VERSION ""

NS_ :

BS_:

BU_: PowertrainControlModule AtmosphericSensor SafetyRestraintSystem2 Aftertreatment_2_GasOutlet Aftertreatment_2_GasIntake DieselParticulateFilterControl Turbocharger SafetyRestraintSystem1 CabDisplay2 Aftertreatment_1_GasOutlet Aftertreatment_1_GasIntake OnBoardDataLogger OffBoardDiagnosticTool2 OffBoardDiagnosticTool1 FileServer ParkingBrakeController SeatController2 FanDriveController SteeringColumnUnit CommunicationUnitRadio CommunicationUnitSatellite CommunicationUnitCellular PropulsionBatteryCharger ChassisController2 ChassisController1 EngineValveControl AuxiliaryHeater2 AuxiliaryHeater1 ClutchUnit RampControl InformationSystem1 SuspensionSystemController2 OilSensor VehicleDynamicStability ExhaustEmissionController TransmissionDisplay2 TransmissionDisplay1 ClimateControl2 WaterPumpController RearAxleSteeringController LightingOperatorControl SeatController1 IgnitionController2 IgnitionController1 TirePressureController CabController2 CabController1 PneumaticSystemController SuspensionSystemController1 HydraulicPumpController EnduranceBrakingSystem RetarderExhaustEngine2 OnBoardDiagnosticUnit HeadwayController RetarderExhaustEngine1 CabDisplay1 ManagementComputer VirtualTerminal OffVehicleGateway PowerTakeOffFront HitchControl AuxiliaryValveControl BodyController TractorTrailerBridge1 StarterSystem ElectricalSystem VehicleSecurity VehicleNavigation AerodynamicControl ElectricalChargingSystem ClimateControl1 TripRecorder InstrumentCluster SuspensionDriveAxle2 SuspensionDriveAxle1 SuspensionSteerAxle SteeringController FuelSystem CruiseControl RetarderDriveline RetarderEngine BrakesDriveAxle2 BrakesDriveAxle1 BrakesSystemController BrakesSteerAxle AxleDrive2 AxleDrive1 AxleSteering PowerTakeOff ShiftConsoleSecondary ShiftConsolePrimary Transmission2 Transmission1 Engine2 Engine1

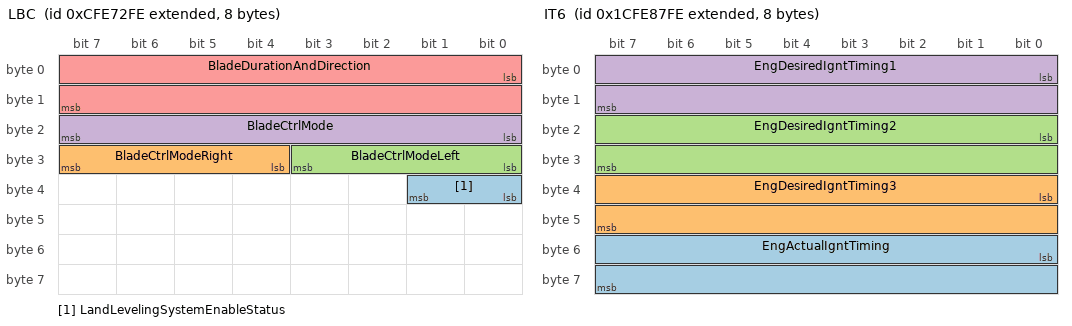
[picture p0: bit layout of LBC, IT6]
BO_ 2365485822 LBC: 8 Vector__XXX
 SG_ LandLevelingSystemEnableStatus : 32|2@1+ (1,0) [0|3] "" Vector__XXX
 SG_ BladeCtrlModeRight : 28|4@1+ (1,0) [0|15] "" Vector__XXX
 SG_ BladeCtrlModeLeft : 24|4@1+ (1,0) [0|15] "" Vector__XXX
 SG_ BladeCtrlMode : 16|8@1+ (1,0) [0|255] "" Vector__XXX
 SG_ BladeDurationAndDirection : 0|16@1+ (0.1,-3276.8) [-3276.8|3148.7] "s" Vector__XXX

BO_ 2633926654 IT6: 8 Vector__XXX
 SG_ EngActualIgntTiming : 48|16@1+ (0.0078125,-200) [-200|301.99] "deg" Vector__XXX
 SG_ EngDesiredIgntTiming3 : 32|16@1+ (0.0078125,-200) [-200|301.99] "deg" Vector__XXX
 SG_ EngDesiredIgntTiming2 : 16|16@1+ (0.0078125,-200) [-200|301.99] "deg" Vector__XXX
 SG_ EngDesiredIgntTiming1 : 0|16@1+ (0.0078125,-200) [-200|301.99] "deg" Vector__XXX

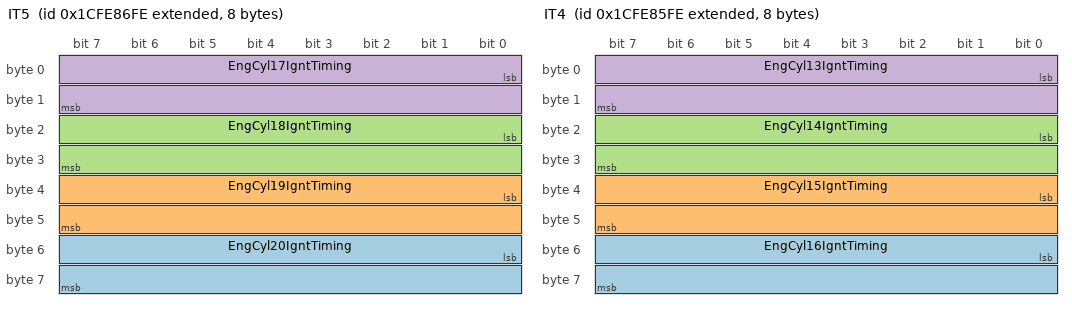
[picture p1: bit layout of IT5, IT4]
BO_ 2633926398 IT5: 8 Vector__XXX
 SG_ EngCyl20IgntTiming : 48|16@1+ (0.0078125,-200) [-200|301.99] "deg" Vector__XXX
 SG_ EngCyl19IgntTiming : 32|16@1+ (0.0078125,-200) [-200|301.99] "deg" Vector__XXX
 SG_ EngCyl18IgntTiming : 16|16@1+ (0.0078125,-200) [-200|301.99] "deg" Vector__XXX
 SG_ EngCyl17IgntTiming : 0|16@1+ (0.0078125,-200) [-200|301.99] "deg" Vector__XXX

BO_ 2633926142 IT4: 8 Vector__XXX
 SG_ EngCyl16IgntTiming : 48|16@1+ (0.0078125,-200) [-200|301.99] "deg" Vector__XXX
 SG_ EngCyl15IgntTiming : 32|16@1+ (0.0078125,-200) [-200|301.99] "deg" Vector__XXX
 SG_ EngCyl14IgntTiming : 16|16@1+ (0.0078125,-200) [-200|301.99] "deg" Vector__XXX
 SG_ EngCyl13IgntTiming : 0|16@1+ (0.0078125,-200) [-200|301.99] "deg" Vector__XXX

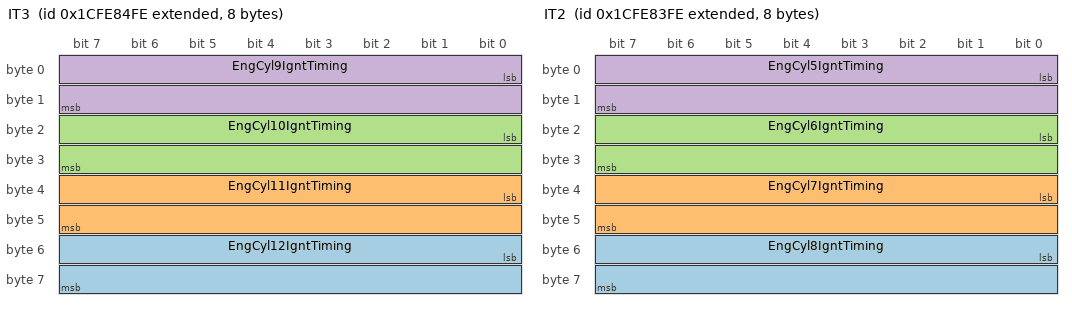
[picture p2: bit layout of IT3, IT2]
BO_ 2633925886 IT3: 8 Vector__XXX
 SG_ EngCyl12IgntTiming : 48|16@1+ (0.0078125,-200) [-200|301.99] "deg" Vector__XXX
 SG_ EngCyl11IgntTiming : 32|16@1+ (0.0078125,-200) [-200|301.99] "deg" Vector__XXX
 SG_ EngCyl10IgntTiming : 16|16@1+ (0.0078125,-200) [-200|301.99] "deg" Vector__XXX
 SG_ EngCyl9IgntTiming : 0|16@1+ (0.0078125,-200) [-200|301.99] "deg" Vector__XXX

BO_ 2633925630 IT2: 8 Vector__XXX
 SG_ EngCyl8IgntTiming : 48|16@1+ (0.0078125,-200) [-200|301.99] "deg" Vector__XXX
 SG_ EngCyl7IgntTiming : 32|16@1+ (0.0078125,-200) [-200|301.99] "deg" Vector__XXX
 SG_ EngCyl6IgntTiming : 16|16@1+ (0.0078125,-200) [-200|301.99] "deg" Vector__XXX
 SG_ EngCyl5IgntTiming : 0|16@1+ (0.0078125,-200) [-200|301.99] "deg" Vector__XXX

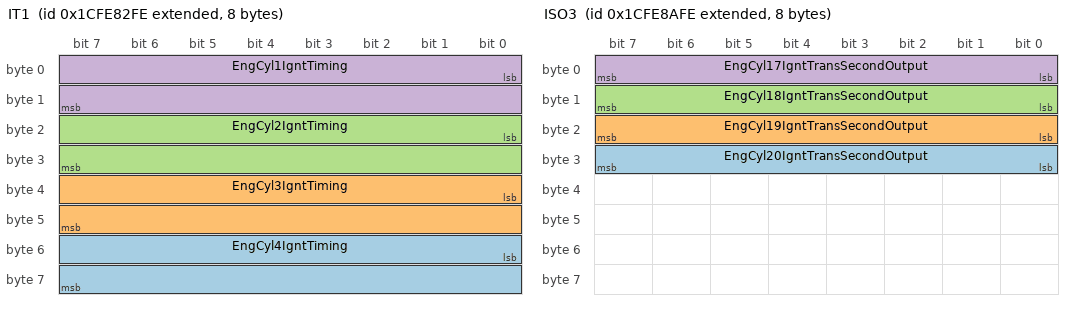
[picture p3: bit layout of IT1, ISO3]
BO_ 2633925374 IT1: 8 Vector__XXX
 SG_ EngCyl4IgntTiming : 48|16@1+ (0.0078125,-200) [-200|301.99] "deg" Vector__XXX
 SG_ EngCyl3IgntTiming : 32|16@1+ (0.0078125,-200) [-200|301.99] "deg" Vector__XXX
 SG_ EngCyl2IgntTiming : 16|16@1+ (0.0078125,-200) [-200|301.99] "deg" Vector__XXX
 SG_ EngCyl1IgntTiming : 0|16@1+ (0.0078125,-200) [-200|301.99] "deg" Vector__XXX

BO_ 2633927422 ISO3: 8 Vector__XXX
 SG_ EngCyl20IgntTransSecondOutput : 24|8@1+ (1,-125) [-125|125] "%" Vector__XXX
 SG_ EngCyl19IgntTransSecondOutput : 16|8@1+ (1,-125) [-125|125] "%" Vector__XXX
 SG_ EngCyl18IgntTransSecondOutput : 8|8@1+ (1,-125) [-125|125] "%" Vector__XXX
 SG_ EngCyl17IgntTransSecondOutput : 0|8@1+ (1,-125) [-125|125] "%" Vector__XXX

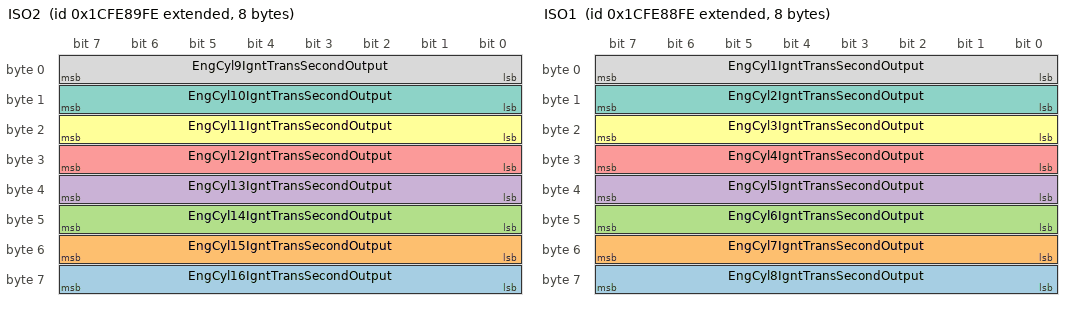
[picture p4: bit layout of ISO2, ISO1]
BO_ 2633927166 ISO2: 8 Vector__XXX
 SG_ EngCyl16IgntTransSecondOutput : 56|8@1+ (1,-125) [-125|125] "%" Vector__XXX
 SG_ EngCyl15IgntTransSecondOutput : 48|8@1+ (1,-125) [-125|125] "%" Vector__XXX
 SG_ EngCyl14IgntTransSecondOutput : 40|8@1+ (1,-125) [-125|125] "%" Vector__XXX
 SG_ EngCyl13IgntTransSecondOutput : 32|8@1+ (1,-125) [-125|125] "%" Vector__XXX
 SG_ EngCyl12IgntTransSecondOutput : 24|8@1+ (1,-125) [-125|125] "%" Vector__XXX
 SG_ EngCyl11IgntTransSecondOutput : 16|8@1+ (1,-125) [-125|125] "%" Vector__XXX
 SG_ EngCyl10IgntTransSecondOutput : 8|8@1+ (1,-125) [-125|125] "%" Vector__XXX
 SG_ EngCyl9IgntTransSecondOutput : 0|8@1+ (1,-125) [-125|125] "%" Vector__XXX

BO_ 2633926910 ISO1: 8 Vector__XXX
 SG_ EngCyl8IgntTransSecondOutput : 56|8@1+ (1,-125) [-125|125] "%" Vector__XXX
 SG_ EngCyl7IgntTransSecondOutput : 48|8@1+ (1,-125) [-125|125] "%" Vector__XXX
 SG_ EngCyl6IgntTransSecondOutput : 40|8@1+ (1,-125) [-125|125] "%" Vector__XXX
 SG_ EngCyl5IgntTransSecondOutput : 32|8@1+ (1,-125) [-125|125] "%" Vector__XXX
 SG_ EngCyl4IgntTransSecondOutput : 24|8@1+ (1,-125) [-125|125] "%" Vector__XXX
 SG_ EngCyl3IgntTransSecondOutput : 16|8@1+ (1,-125) [-125|125] "%" Vector__XXX
 SG_ EngCyl2IgntTransSecondOutput : 8|8@1+ (1,-125) [-125|125] "%" Vector__XXX
 SG_ EngCyl1IgntTransSecondOutput : 0|8@1+ (1,-125) [-125|125] "%" Vector__XXX

BO_ 2566768894 ISCS: 8 Vector__XXX
 SG_ EngOprtrPrmryIntrmdtSpdSlctState : 0|4@1+ (1,0) [0|15] "" Vector__XXX

BO_ 2566769406 ISC: 8 Vector__XXX
 SG_ EngOprtrPrmryIntrmdteSpeedSelect : 0|4@1+ (1,0) [0|15] "" Vector__XXX

BO_ 2566839550 IO: 8 Vector__XXX
 SG_ EngTotalIdleHours : 32|32@1+ (0.05,0) [0|210554060.75] "h" Vector__XXX
 SG_ EngTotalIdleFuelUsed : 0|32@1+ (0.5,0) [0|2105540607.5] "l" Vector__XXX

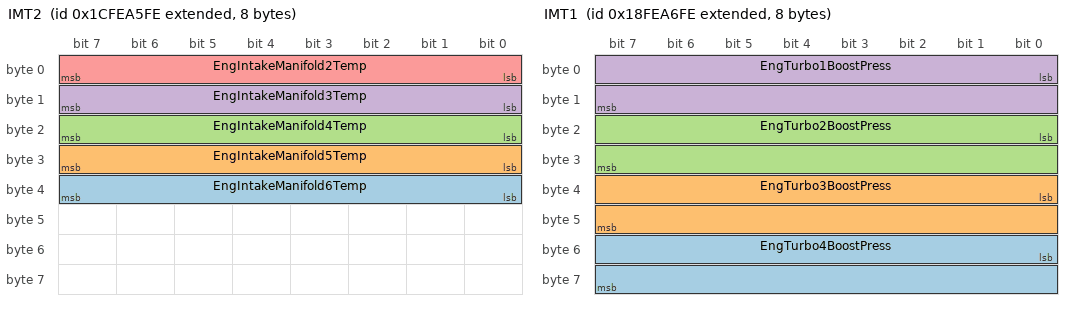
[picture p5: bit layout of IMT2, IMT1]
BO_ 2633934334 IMT2: 8 Vector__XXX
 SG_ EngIntakeManifold6Temp : 32|8@1+ (1,-40) [-40|210] "캜" Vector__XXX
 SG_ EngIntakeManifold5Temp : 24|8@1+ (1,-40) [-40|210] "캜" Vector__XXX
 SG_ EngIntakeManifold4Temp : 16|8@1+ (1,-40) [-40|210] "캜" Vector__XXX
 SG_ EngIntakeManifold3Temp : 8|8@1+ (1,-40) [-40|210] "캜" Vector__XXX
 SG_ EngIntakeManifold2Temp : 0|8@1+ (1,-40) [-40|210] "캜" Vector__XXX

BO_ 2566825726 IMT1: 8 Vector__XXX
 SG_ EngTurbo4BoostPress : 48|16@1+ (0.125,0) [0|8031.875] "kPa" Vector__XXX
 SG_ EngTurbo3BoostPress : 32|16@1+ (0.125,0) [0|8031.875] "kPa" Vector__XXX
 SG_ EngTurbo2BoostPress : 16|16@1+ (0.125,0) [0|8031.875] "kPa" Vector__XXX
 SG_ EngTurbo1BoostPress : 0|16@1+ (0.125,0) [0|8031.875] "kPa" Vector__XXX

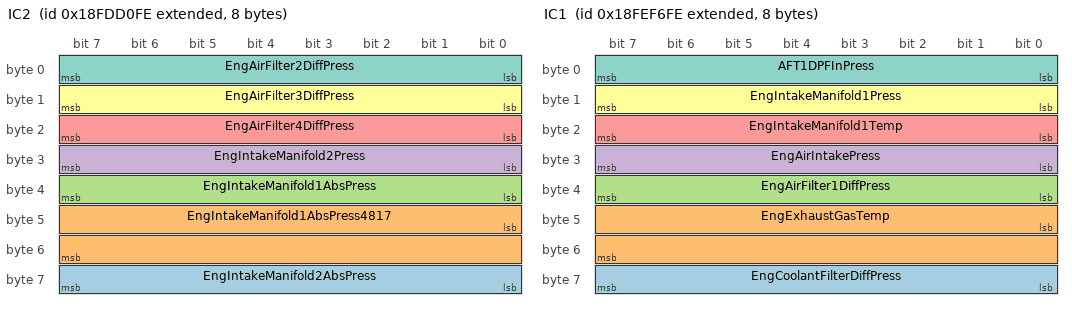
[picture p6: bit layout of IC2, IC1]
BO_ 2566770942 IC2: 8 Vector__XXX
 SG_ EngIntakeManifold2AbsPress : 56|8@1+ (2,0) [0|500] "kPa" Vector__XXX
 SG_ EngIntakeManifold1AbsPress4817 : 40|16@1+ (0.1,0) [0|6425.5] "kPa" Vector__XXX
 SG_ EngIntakeManifold1AbsPress : 32|8@1+ (2,0) [0|500] "kPa" Vector__XXX
 SG_ EngIntakeManifold2Press : 24|8@1+ (2,0) [0|500] "kPa" Vector__XXX
 SG_ EngAirFilter4DiffPress : 16|8@1+ (0.05,0) [0|12.5] "kPa" Vector__XXX
 SG_ EngAirFilter3DiffPress : 8|8@1+ (0.05,0) [0|12.5] "kPa" Vector__XXX
 SG_ EngAirFilter2DiffPress : 0|8@1+ (0.05,0) [0|12.5] "kPa" Vector__XXX

BO_ 2566846206 IC1: 8 Vector__XXX
 SG_ EngCoolantFilterDiffPress : 56|8@1+ (0.5,0) [0|125] "kPa" Vector__XXX
 SG_ EngExhaustGasTemp : 40|16@1+ (0.03125,-273) [-273|1734.96875] "캜" Vector__XXX
 SG_ EngAirFilter1DiffPress : 32|8@1+ (0.05,0) [0|12.5] "kPa" Vector__XXX
 SG_ EngAirIntakePress : 24|8@1+ (2,0) [0|500] "kPa" Vector__XXX
 SG_ EngIntakeManifold1Temp : 16|8@1+ (1,-40) [-40|210] "캜" Vector__XXX
 SG_ EngIntakeManifold1Press : 8|8@1+ (2,0) [0|500] "kPa" Vector__XXX
 SG_ AFT1DPFInPress : 0|8@1+ (0.5,0) [0|125] "kPa" Vector__XXX

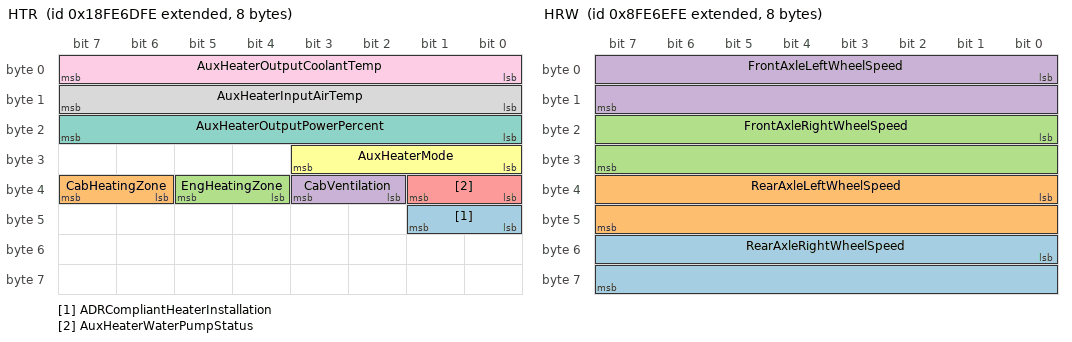
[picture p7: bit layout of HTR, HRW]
BO_ 2566811134 HTR: 8 Vector__XXX
 SG_ ADRCompliantHeaterInstallation : 40|2@1+ (1,0) [0|3] "" Vector__XXX
 SG_ CabHeatingZone : 38|2@1+ (1,0) [0|3] "" Vector__XXX
 SG_ EngHeatingZone : 36|2@1+ (1,0) [0|3] "" Vector__XXX
 SG_ CabVentilation : 34|2@1+ (1,0) [0|3] "" Vector__XXX
 SG_ AuxHeaterWaterPumpStatus : 32|2@1+ (1,0) [0|3] "" Vector__XXX
 SG_ AuxHeaterMode : 24|4@1+ (1,0) [0|15] "" Vector__XXX
 SG_ AuxHeaterOutputPowerPercent : 16|8@1+ (0.4,0) [0|100] "%" Vector__XXX
 SG_ AuxHeaterInputAirTemp : 8|8@1+ (1,-40) [-40|210] "캜" Vector__XXX
 SG_ AuxHeaterOutputCoolantTemp : 0|8@1+ (1,-40) [-40|210] "캜" Vector__XXX

BO_ 2298375934 HRW: 8 Vector__XXX
 SG_ RearAxleRightWheelSpeed : 48|16@1+ (0.00390625,0) [0|250.996] "km/h" Vector__XXX
 SG_ RearAxleLeftWheelSpeed : 32|16@1+ (0.00390625,0) [0|250.996] "km/h" Vector__XXX
 SG_ FrontAxleRightWheelSpeed : 16|16@1+ (0.00390625,0) [0|250.996] "km/h" Vector__XXX
 SG_ FrontAxleLeftWheelSpeed : 0|16@1+ (0.00390625,0) [0|250.996] "km/h" Vector__XXX

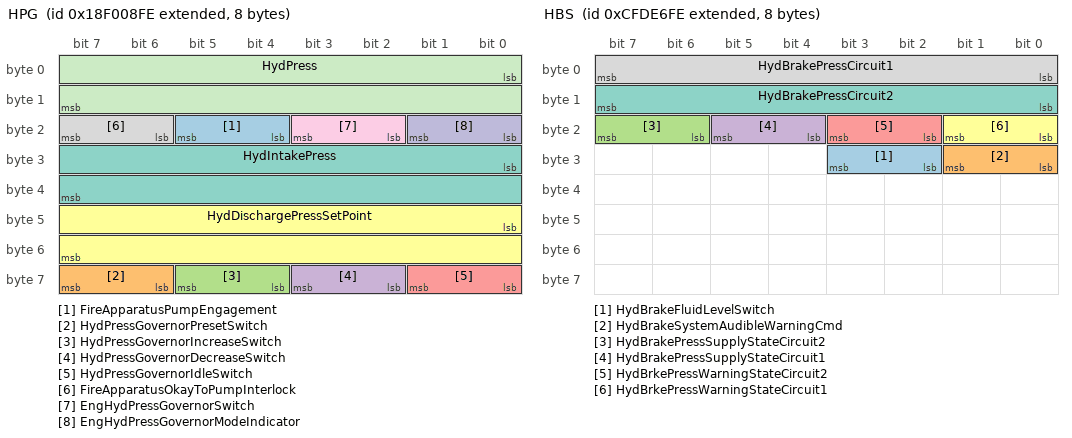
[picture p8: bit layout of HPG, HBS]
BO_ 2565867774 HPG: 8 Vector__XXX
 SG_ FireApparatusPumpEngagement : 20|2@1+ (1,0) [0|3] "" Vector__XXX
 SG_ HydPressGovernorPresetSwitch : 62|2@1+ (1,0) [0|3] "" Vector__XXX
 SG_ HydPressGovernorIncreaseSwitch : 60|2@1+ (1,0) [0|3] "" Vector__XXX
 SG_ HydPressGovernorDecreaseSwitch : 58|2@1+ (1,0) [0|3] "" Vector__XXX
 SG_ HydPressGovernorIdleSwitch : 56|2@1+ (1,0) [0|3] "" Vector__XXX
 SG_ HydDischargePressSetPoint : 40|16@1+ (2,0) [0|128510] "kPa" Vector__XXX
 SG_ HydIntakePress : 24|16@1+ (0.0001220703125,-1) [-1|6.84362793] "MPa" Vector__XXX
 SG_ FireApparatusOkayToPumpInterlock : 22|2@1+ (1,0) [0|3] "" Vector__XXX
 SG_ EngHydPressGovernorSwitch : 18|2@1+ (1,0) [0|3] "" Vector__XXX
 SG_ EngHydPressGovernorModeIndicator : 16|2@1+ (1,0) [0|3] "" Vector__XXX
 SG_ HydPress : 0|16@1+ (2,0) [0|128510] "kPa" Vector__XXX

BO_ 2566841854 HOURS: 8 Vector__XXX
 SG_ EngTotalRevolutions : 32|32@1+ (1000,0) [0|4211081215000] "r" Vector__XXX
 SG_ EngTotalHoursOfOperation : 0|32@1+ (0.05,0) [0|210554060.75] "h" Vector__XXX

BO_ 2365449982 HBS: 8 Vector__XXX
 SG_ HydBrakeFluidLevelSwitch : 26|2@1+ (1,0) [0|3] "" Vector__XXX
 SG_ HydBrakeSystemAudibleWarningCmd : 24|2@1+ (1,0) [0|3] "" Vector__XXX
 SG_ HydBrakePressSupplyStateCircuit2 : 22|2@1+ (1,0) [0|3] "" Vector__XXX
 SG_ HydBrakePressSupplyStateCircuit1 : 20|2@1+ (1,0) [0|3] "" Vector__XXX
 SG_ HydBrkePressWarningStateCircuit2 : 18|2@1+ (1,0) [0|3] "" Vector__XXX
 SG_ HydBrkePressWarningStateCircuit1 : 16|2@1+ (1,0) [0|3] "" Vector__XXX
 SG_ HydBrakePressCircuit2 : 8|8@1+ (100,0) [0|25000] "kPa" Vector__XXX
 SG_ HydBrakePressCircuit1 : 0|8@1+ (100,0) [0|25000] "kPa" Vector__XXX

BO_ 2633939198 GTFI: 22 Vector__XXX
 SG_ TripDriveFuelEconomy : 160|16@1+ (0.001953125,0) [0|125.498046875] "km/kg" Vector__XXX
 SG_ TripCruiseFuelUsed : 128|32@1+ (0.5,0) [0|2105540607.5] "kg" Vector__XXX
 SG_ TripVehicleIdleFuelUsed : 96|32@1+ (0.5,0) [0|2105540607.5] "kg" Vector__XXX
 SG_ TripPTOGovernorNonmovingFuelUsed : 64|32@1+ (0.5,0) [0|2105540607.5] "kg" Vector__XXX
 SG_ TripPTOGovernorMovingFuelUsed : 32|32@1+ (0.5,0) [0|2105540607.5] "kg" Vector__XXX
 SG_ TripDriveFuelUsed : 0|32@1+ (0.5,0) [0|2105540607.5] "kg" Vector__XXX

BO_ 2633927678 GFP1: 8 Vector__XXX
 SG_ EngFuelValve1OutletAbsPress : 48|16@1+ (0.1,0) [0|6425.5] "kPa" Vector__XXX
 SG_ EngAirToFuelDiffPress : 32|16@1+ (0.1,0) [0|6425.5] "kPa" Vector__XXX
 SG_ EngFuelValveDiffPress : 16|16@1+ (0.1,0) [0|6425.5] "kPa" Vector__XXX
 SG_ EngFuelValve1IntakeAbsPress : 0|16@1+ (0.1,0) [0|6425.5] "kPa" Vector__XXX

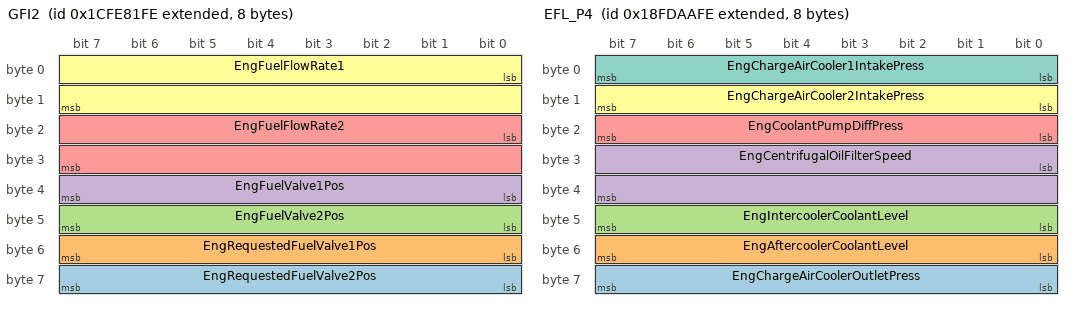
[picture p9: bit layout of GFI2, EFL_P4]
BO_ 2633925118 GFI2: 8 Vector__XXX
 SG_ EngRequestedFuelValve2Pos : 56|8@1+ (0.4,0) [0|100] "%" Vector__XXX
 SG_ EngRequestedFuelValve1Pos : 48|8@1+ (0.4,0) [0|100] "%" Vector__XXX
 SG_ EngFuelValve2Pos : 40|8@1+ (0.4,0) [0|100] "%" Vector__XXX
 SG_ EngFuelValve1Pos : 32|8@1+ (0.4,0) [0|100] "%" Vector__XXX
 SG_ EngFuelFlowRate2 : 16|16@1+ (0.1,0) [0|6425.5] "m�/h" Vector__XXX
 SG_ EngFuelFlowRate1 : 0|16@1+ (0.1,0) [0|6425.5] "m�/h" Vector__XXX

BO_ 2633937662 GFI1: 8 Vector__XXX
 SG_ EngFuelSpecificGravity : 48|16@1+ (0.0001,0) [0|2] "" Vector__XXX
 SG_ TripAverageFuelRate : 32|16@1+ (0.05,0) [0|3212.75] "kg/h" Vector__XXX
 SG_ TotalEngPTOGovernorFuelUsed : 0|32@1+ (0.5,0) [0|2105540607.5] "kg" Vector__XXX

BO_ 2566804990 GFD: 8 Vector__XXX
 SG_ FuelEnergyContent : 32|16@1+ (0.00390625,0) [0|250.996] "MJ/Nm�" Vector__XXX
 SG_ ReferenceEngGasMassFlowRate : 16|16@1+ (0.05,0) [0|3212.75] "kg/h" Vector__XXX
 SG_ SpecificHeatRatio : 0|16@1+ (0.001,0) [0|2] "" Vector__XXX

BO_ 2633936894 GFC: 8 Vector__XXX
 SG_ TotalFuelUsed : 32|32@1+ (0.5,0) [0|2105540607.5] "kg" Vector__XXX
 SG_ TripFuel : 0|32@1+ (0.5,0) [0|2105540607.5] "kg" Vector__XXX

BO_ 2566757630 SEP2: 8 Vector__XXX
 SG_ SensorSupplyVoltage8 : 48|16@1+ (0.05,0) [0|3212.75] "V" Vector__XXX
 SG_ SensorSupplyVoltage7 : 32|16@1+ (0.05,0) [0|3212.75] "V" Vector__XXX
 SG_ SensorSupplyVoltage6 : 16|16@1+ (0.05,0) [0|3212.75] "V" Vector__XXX
 SG_ SensorSupplyVoltage5 : 0|16@1+ (0.05,0) [0|3212.75] "V" Vector__XXX

BO_ 2566757886 SEP1: 8 Vector__XXX
 SG_ SensorSupplyVoltage4 : 48|16@1+ (0.05,0) [0|3212.75] "V" Vector__XXX
 SG_ SensorSupplyVoltage3 : 32|16@1+ (0.05,0) [0|3212.75] "V" Vector__XXX
 SG_ SensorSupplyVoltage2 : 16|16@1+ (0.05,0) [0|3212.75] "V" Vector__XXX
 SG_ SensorSupplyVoltage1 : 0|16@1+ (0.05,0) [0|3212.75] "V" Vector__XXX

BO_ 2566759678 PTODE: 8 Vector__XXX
 SG_ AtLeastOnePTOEngaged : 48|2@1+ (1,0) [0|3] "" Vector__XXX
 SG_ EnggmntSttsPTOEngAccessoryDrive2 : 44|2@1+ (1,0) [0|3] "" Vector__XXX
 SG_ EnggmntSttsPTOEngAccessoryDrive1 : 42|2@1+ (1,0) [0|3] "" Vector__XXX
 SG_ EngagementStatusPTOEngFlywheel : 40|2@1+ (1,0) [0|3] "" Vector__XXX
 SG_ EnggmntStatusTransInputShaftPTO1 : 38|2@1+ (1,0) [0|3] "" Vector__XXX
 SG_ EnggmntStatusTransInputShaftPTO2 : 36|2@1+ (1,0) [0|3] "" Vector__XXX
 SG_ EnggmntStatusTransOutputShaftPTO : 34|2@1+ (1,0) [0|3] "" Vector__XXX
 SG_ EnggmntSttsTrnsfrCsOtputShaftPTO : 32|2@1+ (1,0) [0|3] "" Vector__XXX
 SG_ EnggmntCnsntPTOEngAccssoryDrive2 : 28|2@1+ (1,0) [0|3] "" Vector__XXX
 SG_ EnggmntCnsntPTOEngAccssoryDrive1 : 26|2@1+ (1,0) [0|3] "" Vector__XXX
 SG_ EngagementConsentPTOEngFlywheel : 24|2@1+ (1,0) [0|3] "" Vector__XXX
 SG_ EnggmntCnsentTransInputShaftPTO1 : 22|2@1+ (1,0) [0|3] "" Vector__XXX
 SG_ EnggmntCnsentTransInputShaftPTO2 : 20|2@1+ (1,0) [0|3] "" Vector__XXX
 SG_ EnggmntCnsentTransOutputShaftPTO : 18|2@1+ (1,0) [0|3] "" Vector__XXX
 SG_ EnggmntCnsntTrnsfrCsOtptShaftPTO : 16|2@1+ (1,0) [0|3] "" Vector__XXX
 SG_ EnbleSwitchPTOEngAccessoryDrive2 : 12|2@1+ (1,0) [0|3] "" Vector__XXX
 SG_ EnbleSwitchPTOEngAccessoryDrive1 : 10|2@1+ (1,0) [0|3] "" Vector__XXX
 SG_ EnableSwitchPTOEngFlywheel : 8|2@1+ (1,0) [0|3] "" Vector__XXX
 SG_ EnableSwitchTransInputShaftPTO1 : 6|2@1+ (1,0) [0|3] "" Vector__XXX
 SG_ EnableSwitchTransInputShaftPTO2 : 4|2@1+ (1,0) [0|3] "" Vector__XXX
 SG_ EnableSwitchTransOutputShaftPTO : 2|2@1+ (1,0) [0|3] "" Vector__XXX
 SG_ EnblSwtchTrnsfrCseOutputShaftPTO : 0|2@1+ (1,0) [0|3] "" Vector__XXX

BO_ 2432541438 GFI3: 8 Vector__XXX
 SG_ EngFuelValve2OutletAbsPress : 48|16@1+ (0.1,0) [0|6425.5] "kPa" Vector__XXX
 SG_ EngFuelTemp2 : 32|8@1+ (1,-40) [-40|210] "캜" Vector__XXX
 SG_ EngGas2MassFlowRate : 16|16@1+ (0.05,0) [0|3212.75] "kg/h" Vector__XXX
 SG_ EngFuelValve2IntakeAbsPress : 0|16@1+ (0.1,0) [0|6425.5] "kPa" Vector__XXX

BO_ 2566761214 EFL_P4: 8 Vector__XXX
 SG_ EngChargeAirCoolerOutletPress : 56|8@1+ (2,0) [0|500] "kPa" Vector__XXX
 SG_ EngAftercoolerCoolantLevel : 48|8@1+ (0.4,0) [0|100] "%" Vector__XXX
 SG_ EngIntercoolerCoolantLevel : 40|8@1+ (0.4,0) [0|100] "%" Vector__XXX
 SG_ EngCentrifugalOilFilterSpeed : 24|16@1+ (4,0) [0|257020] "rpm" Vector__XXX
 SG_ EngCoolantPumpDiffPress : 16|8@1+ (1.64,-7) [-7|403] "kPa" Vector__XXX
 SG_ EngChargeAirCooler2IntakePress : 8|8@1+ (2,0) [0|500] "kPa" Vector__XXX
 SG_ EngChargeAirCooler1IntakePress : 0|8@1+ (2,0) [0|500] "kPa" Vector__XXX

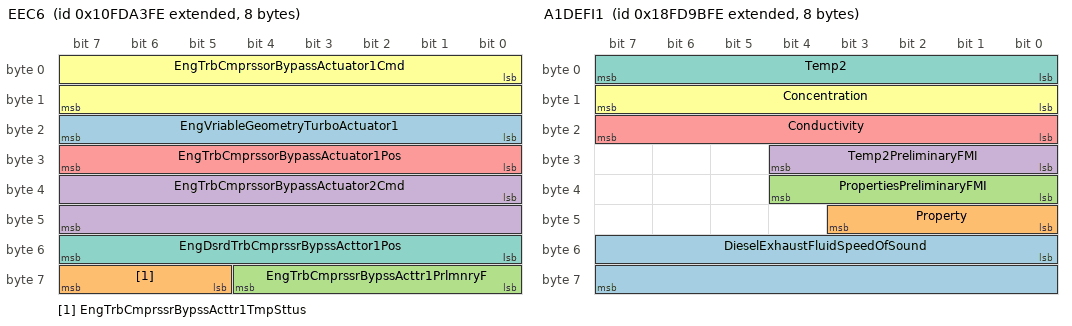
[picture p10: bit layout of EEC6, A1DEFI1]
BO_ 2432541694 EEC6: 8 Vector__XXX
 SG_ EngVriableGeometryTurboActuator1 : 16|8@1+ (0.4,0) [0|100] "%" Vector__XXX
 SG_ EngTrbCmprssrBypssActtr1TmpSttus : 61|3@1+ (1,0) [0|7] "" Vector__XXX
 SG_ EngTrbCmprssrBypssActtr1PrlmnryF : 56|5@1+ (1,0) [0|31] "" Vector__XXX
 SG_ EngTrbCmprssorBypassActuator2Cmd : 32|16@1+ (0.0025,0) [0|160.6375] "%" Vector__XXX
 SG_ EngTrbCmprssorBypassActuator1Pos : 24|8@1+ (0.4,0) [0|100] "%" Vector__XXX
 SG_ EngTrbCmprssorBypassActuator1Cmd : 0|16@1+ (0.0025,0) [0|100] "%" Vector__XXX
 SG_ EngDsrdTrbCmprssrBypssActtor1Pos : 48|8@1+ (0.4,0) [0|100] "%" Vector__XXX

BO_ 2566759934 DC2: 8 Vector__XXX
 SG_ EnableStatusOfDoor10 : 58|2@1+ (1,0) [0|3] "" Vector__XXX
 SG_ OpenStatusOfDoor10 : 56|2@1+ (1,0) [0|3] "" Vector__XXX
 SG_ LockStatusOfDoor10 : 54|2@1+ (1,0) [0|3] "" Vector__XXX
 SG_ EnableStatusOfDoor9 : 52|2@1+ (1,0) [0|3] "" Vector__XXX
 SG_ OpenStatusOfDoor9 : 50|2@1+ (1,0) [0|3] "" Vector__XXX
 SG_ LockStatusOfDoor9 : 48|2@1+ (1,0) [0|3] "" Vector__XXX
 SG_ EnableStatusOfDoor8 : 46|2@1+ (1,0) [0|3] "" Vector__XXX
 SG_ OpenStatusOfDoor8 : 44|2@1+ (1,0) [0|3] "" Vector__XXX
 SG_ LockStatusOfDoor8 : 42|2@1+ (1,0) [0|3] "" Vector__XXX
 SG_ EnableStatusOfDoor7 : 40|2@1+ (1,0) [0|3] "" Vector__XXX
 SG_ OpenStatusOfDoor7 : 38|2@1+ (1,0) [0|3] "" Vector__XXX
 SG_ LockStatusOfDoor7 : 36|2@1+ (1,0) [0|3] "" Vector__XXX
 SG_ EnableStatusOfDoor6 : 34|2@1+ (1,0) [0|3] "" Vector__XXX
 SG_ OpenStatusOfDoor6 : 32|2@1+ (1,0) [0|3] "" Vector__XXX
 SG_ LockStatusOfDoor6 : 30|2@1+ (1,0) [0|3] "" Vector__XXX
 SG_ EnableStatusOfDoor5 : 28|2@1+ (1,0) [0|3] "" Vector__XXX
 SG_ OpenStatusOfDoor5 : 26|2@1+ (1,0) [0|3] "" Vector__XXX
 SG_ LockStatusOfDoor5 : 24|2@1+ (1,0) [0|3] "" Vector__XXX
 SG_ EnableStatusOfDoor4 : 22|2@1+ (1,0) [0|3] "" Vector__XXX
 SG_ OpenStatusOfDoor4 : 20|2@1+ (1,0) [0|3] "" Vector__XXX
 SG_ LockStatusOfDoor4 : 18|2@1+ (1,0) [0|3] "" Vector__XXX
 SG_ EnableStatusOfDoor3 : 16|2@1+ (1,0) [0|3] "" Vector__XXX
 SG_ OpenStatusOfDoor3 : 14|2@1+ (1,0) [0|3] "" Vector__XXX
 SG_ LockStatusOfDoor3 : 12|2@1+ (1,0) [0|3] "" Vector__XXX
 SG_ EnableStatusOfDoor2 : 10|2@1+ (1,0) [0|3] "" Vector__XXX
 SG_ OpenStatusOfDoor2 : 8|2@1+ (1,0) [0|3] "" Vector__XXX
 SG_ LockStatusOfDoor2 : 6|2@1+ (1,0) [0|3] "" Vector__XXX
 SG_ EnableStatusOfDoor1 : 4|2@1+ (1,0) [0|3] "" Vector__XXX
 SG_ OpenStatusOfDoor1 : 2|2@1+ (1,0) [0|3] "" Vector__XXX
 SG_ LockStatusOfDoor1 : 0|2@1+ (1,0) [0|3] "" Vector__XXX

BO_ 2566757374 A1DEFI1: 8 Vector__XXX
 SG_ DieselExhaustFluidSpeedOfSound : 48|16@1+ (0.1,0) [0|6425.5] "m/s" Vector__XXX
 SG_ Property : 40|4@1+ (1,0) [0|15] "" Vector__XXX
 SG_ PropertiesPreliminaryFMI : 32|5@1+ (1,0) [0|31] "" Vector__XXX
 SG_ Temp2PreliminaryFMI : 24|5@1+ (1,0) [0|31] "" Vector__XXX
 SG_ Conductivity : 16|8@1+ (5,0) [0|1250] "킪iemens/mm" Vector__XXX
 SG_ Concentration : 8|8@1+ (0.25,0) [0|62.5] "%" Vector__XXX
 SG_ Temp2 : 0|8@1+ (1,-40) [-40|210] "캜" Vector__XXX

BO_ 2364546302 RGAAC: 8 Vector__XXX
 SG_ RqdGnrtrAvrgLneLineACRMSVoltage : 0|32@1+ (0.0078125,0) [0|32899071] "V" Vector__XXX

BO_ 2431654654 TFAC: 8 Vector__XXX
 SG_ EngFuelActuator2CtrlCmd : 48|16@1+ (0.0025,0) [0|100] "%" Vector__XXX
 SG_ EngFuelActuator1CtrlCmd : 32|16@1+ (0.0025,0) [0|100] "%" Vector__XXX
 SG_ EngThrottleActuator2CtrlCmd : 16|16@1+ (0.0025,0) [0|100] "%" Vector__XXX
 SG_ EngThrottleActuator1CtrlCmd : 0|16@1+ (0.0025,0) [0|100] "%" Vector__XXX

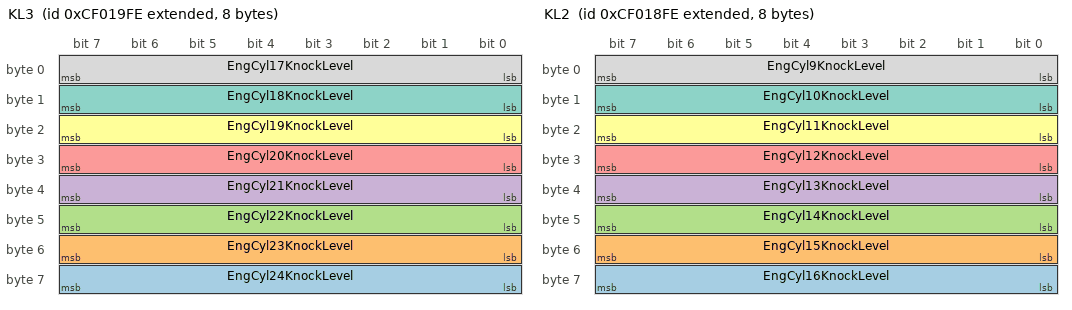
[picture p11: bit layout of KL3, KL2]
BO_ 2364545534 KL3: 8 Vector__XXX
 SG_ EngCyl24KnockLevel : 56|8@1+ (1,0) [0|250] "%" Vector__XXX
 SG_ EngCyl23KnockLevel : 48|8@1+ (1,0) [0|250] "%" Vector__XXX
 SG_ EngCyl22KnockLevel : 40|8@1+ (1,0) [0|250] "%" Vector__XXX
 SG_ EngCyl21KnockLevel : 32|8@1+ (1,0) [0|250] "%" Vector__XXX
 SG_ EngCyl20KnockLevel : 24|8@1+ (1,0) [0|250] "%" Vector__XXX
 SG_ EngCyl19KnockLevel : 16|8@1+ (1,0) [0|250] "%" Vector__XXX
 SG_ EngCyl18KnockLevel : 8|8@1+ (1,0) [0|250] "%" Vector__XXX
 SG_ EngCyl17KnockLevel : 0|8@1+ (1,0) [0|250] "%" Vector__XXX

BO_ 2364545278 KL2: 8 Vector__XXX
 SG_ EngCyl16KnockLevel : 56|8@1+ (1,0) [0|250] "%" Vector__XXX
 SG_ EngCyl15KnockLevel : 48|8@1+ (1,0) [0|250] "%" Vector__XXX
 SG_ EngCyl14KnockLevel : 40|8@1+ (1,0) [0|250] "%" Vector__XXX
 SG_ EngCyl13KnockLevel : 32|8@1+ (1,0) [0|250] "%" Vector__XXX
 SG_ EngCyl12KnockLevel : 24|8@1+ (1,0) [0|250] "%" Vector__XXX
 SG_ EngCyl11KnockLevel : 16|8@1+ (1,0) [0|250] "%" Vector__XXX
 SG_ EngCyl10KnockLevel : 8|8@1+ (1,0) [0|250] "%" Vector__XXX
 SG_ EngCyl9KnockLevel : 0|8@1+ (1,0) [0|250] "%" Vector__XXX

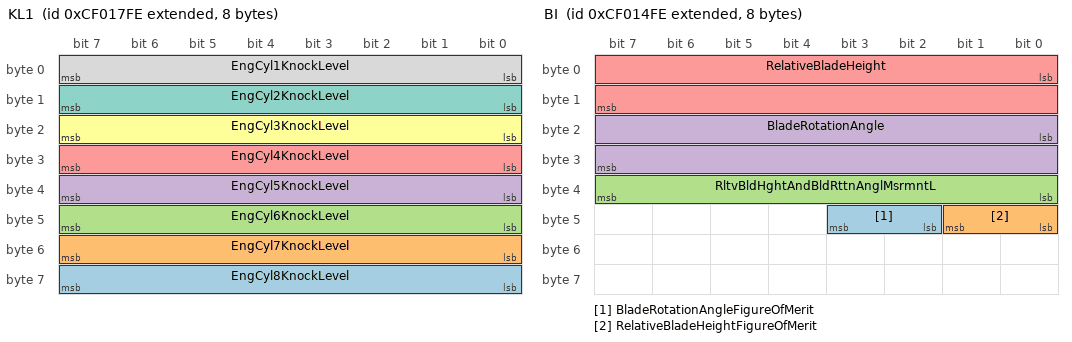
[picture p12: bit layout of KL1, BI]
BO_ 2364545022 KL1: 8 Vector__XXX
 SG_ EngCyl8KnockLevel : 56|8@1+ (1,0) [0|250] "%" Vector__XXX
 SG_ EngCyl7KnockLevel : 48|8@1+ (1,0) [0|250] "%" Vector__XXX
 SG_ EngCyl6KnockLevel : 40|8@1+ (1,0) [0|250] "%" Vector__XXX
 SG_ EngCyl5KnockLevel : 32|8@1+ (1,0) [0|250] "%" Vector__XXX
 SG_ EngCyl4KnockLevel : 24|8@1+ (1,0) [0|250] "%" Vector__XXX
 SG_ EngCyl3KnockLevel : 16|8@1+ (1,0) [0|250] "%" Vector__XXX
 SG_ EngCyl2KnockLevel : 8|8@1+ (1,0) [0|250] "%" Vector__XXX
 SG_ EngCyl1KnockLevel : 0|8@1+ (1,0) [0|100] "%" Vector__XXX

BO_ 2364544766 CCS: 8 Vector__XXX
 SG_ EngCyl24CombustionStatus : 46|2@1+ (1,0) [0|3] "" Vector__XXX
 SG_ EngCyl23CombustionStatus : 44|2@1+ (1,0) [0|3] "" Vector__XXX
 SG_ EngCyl22CombustionStatus : 42|2@1+ (1,0) [0|3] "" Vector__XXX
 SG_ EngCyl21CombustionStatus : 40|2@1+ (1,0) [0|3] "" Vector__XXX
 SG_ EngCyl20CombustionStatus : 38|2@1+ (1,0) [0|3] "" Vector__XXX
 SG_ EngCyl19CombustionStatus : 36|2@1+ (1,0) [0|3] "" Vector__XXX
 SG_ EngCyl18CombustionStatus : 34|2@1+ (1,0) [0|3] "" Vector__XXX
 SG_ EngCyl17CombustionStatus : 32|2@1+ (1,0) [0|3] "" Vector__XXX
 SG_ EngCyl16CombustionStatus : 30|2@1+ (1,0) [0|3] "" Vector__XXX
 SG_ EngCyl15CombustionStatus : 28|2@1+ (1,0) [0|3] "" Vector__XXX
 SG_ EngCyl14CombustionStatus : 26|2@1+ (1,0) [0|3] "" Vector__XXX
 SG_ EngCyl13CombustionStatus : 24|2@1+ (1,0) [0|3] "" Vector__XXX
 SG_ EngCyl12CombustionStatus : 22|2@1+ (1,0) [0|3] "" Vector__XXX
 SG_ EngCyl11CombustionStatus : 20|2@1+ (1,0) [0|3] "" Vector__XXX
 SG_ EngCyl10CombustionStatus : 18|2@1+ (1,0) [0|3] "" Vector__XXX
 SG_ EngCyl9CombustionStatus : 16|2@1+ (1,0) [0|3] "" Vector__XXX
 SG_ EngCyl8CombustionStatus : 14|2@1+ (1,0) [0|3] "" Vector__XXX
 SG_ EngCyl7CombustionStatus : 12|2@1+ (1,0) [0|3] "" Vector__XXX
 SG_ EngCyl6CombustionStatus : 10|2@1+ (1,0) [0|3] "" Vector__XXX
 SG_ EngCyl5CombustionStatus : 8|2@1+ (1,0) [0|3] "" Vector__XXX
 SG_ EngCyl4CombustionStatus : 6|2@1+ (1,0) [0|3] "" Vector__XXX
 SG_ EngCyl3CombustionStatus : 4|2@1+ (1,0) [0|3] "" Vector__XXX
 SG_ EngCyl2CombustionStatus : 2|2@1+ (1,0) [0|3] "" Vector__XXX
 SG_ EngCyl1CombustionStatus : 0|2@1+ (1,0) [0|3] "" Vector__XXX

BO_ 2364544510 RGTACRP: 8 Vector__XXX
 SG_ RqGenOverallPowerFactorLagging : 48|2@1+ (1,0) [0|3] "" Vector__XXX
 SG_ RqGeneratorOverallPowerFactor : 32|16@1+ (6.103515625E-005,-1) [-1|1] "" Vector__XXX
 SG_ RqGeneratorTotalACReactivePower : 0|32@1+ (1,-2000000000) [-2000000000|2211081215] "VA" Vector__XXX

BO_ 2364544254 BI: 8 Vector__XXX
 SG_ BladeRotationAngleFigureOfMerit : 42|2@1+ (1,0) [0|3] "" Vector__XXX
 SG_ RelativeBladeHeightFigureOfMerit : 40|2@1+ (1,0) [0|3] "" Vector__XXX
 SG_ RltvBldHghtAndBldRttnAnglMsrmntL : 32|8@1+ (0.5,0) [0|125] "ms" Vector__XXX
 SG_ BladeRotationAngle : 16|16@1+ (0.0078125,-200) [-200|301.99] "deg" Vector__XXX
 SG_ RelativeBladeHeight : 0|16@1+ (0.1,-3200) [-3200|3225.5] "mm" Vector__XXX

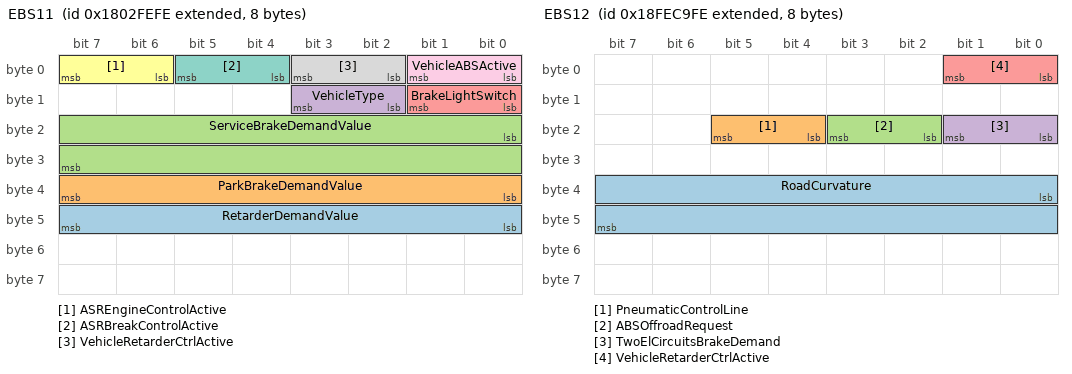
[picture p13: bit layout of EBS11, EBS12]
BO_ 2550333182 EBS11: 8 Vector__XXX
 SG_ RetarderDemandValue : 40|8@1+ (1,-125) [-125|125] "%" Vector__XXX
 SG_ ParkBrakeDemandValue : 32|8@1+ (0.4,0) [0|100] "%" Vector__XXX
 SG_ ServiceBrakeDemandValue : 16|16@1+ (0.01953125,0) [0|1255] "kPa" Vector__XXX
 SG_ VehicleType : 10|2@1+ (1,0) [0|3] "" Vector__XXX
 SG_ BrakeLightSwitch : 8|2@1+ (1,0) [0|3] "" Vector__XXX
 SG_ ASREngineControlActive : 6|2@1+ (1,0) [0|3] "" Vector__XXX
 SG_ ASRBreakControlActive : 4|2@1+ (1,0) [0|3] "" Vector__XXX
 SG_ VehicleRetarderCtrlActive : 2|2@1+ (1,0) [0|3] "" Vector__XXX
 SG_ VehicleABSActive : 0|2@1+ (1,0) [0|1] "" Vector__XXX

BO_ 2566834686 EBS12: 8 Vector__XXX
 SG_ RoadCurvature : 32|16@1+ (0.0078125,-250) [-250|251.992] "1/km" Vector__XXX
 SG_ PneumaticControlLine : 20|2@1+ (1,0) [0|1] "" Vector__XXX
 SG_ ABSOffroadRequest : 18|2@1+ (1,0) [0|1] "" Vector__XXX
 SG_ TwoElCircuitsBrakeDemand : 16|2@1+ (1,0) [0|1] "" Vector__XXX
 SG_ VehicleRetarderCtrlActive : 0|2@1+ (1,0) [0|3] "" Vector__XXX

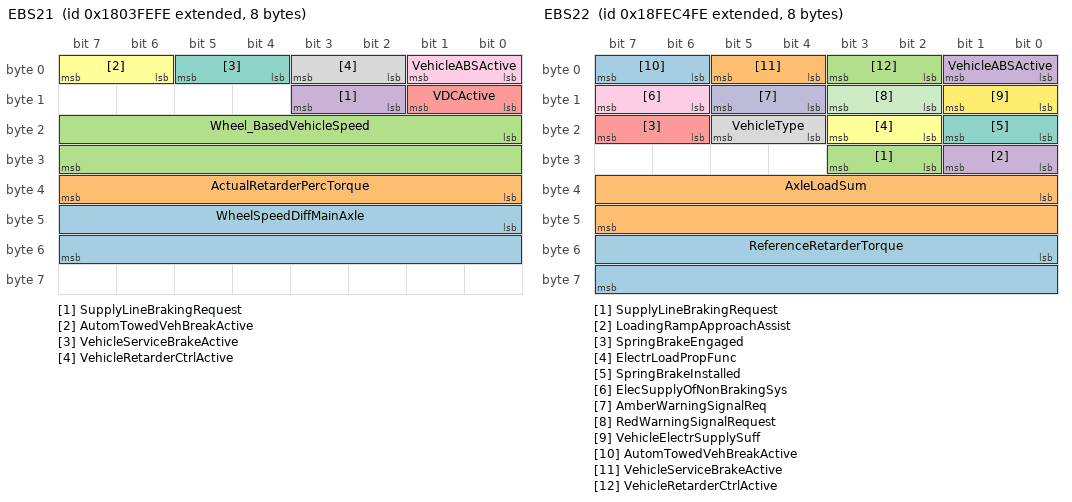
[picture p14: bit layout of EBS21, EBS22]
BO_ 2550398718 EBS21: 8 Vector__XXX
 SG_ WheelSpeedDiffMainAxle : 40|16@1+ (0.00390625,-125) [-125|125] "km/hr" Vector__XXX
 SG_ ActualRetarderPercTorque : 32|8@1+ (1,-125) [-125|125] "%" Vector__XXX
 SG_ Wheel_BasedVehicleSpeed : 16|16@1+ (0.00390625,0) [0|251] "km/hr" Vector__XXX
 SG_ SupplyLineBrakingRequest : 10|2@1+ (1,0) [0|1] "" Vector__XXX
 SG_ VDCActive : 8|2@1+ (1,0) [0|1] "" Vector__XXX
 SG_ AutomTowedVehBreakActive : 6|2@1+ (1,0) [0|1] "" Vector__XXX
 SG_ VehicleServiceBrakeActive : 4|2@1+ (1,0) [0|1] "" Vector__XXX
 SG_ VehicleRetarderCtrlActive : 2|2@1+ (1,0) [0|3] "" Vector__XXX
 SG_ VehicleABSActive : 0|2@1+ (1,0) [0|1] "" Vector__XXX

BO_ 2566833406 EBS22: 8 Vector__XXX
 SG_ ReferenceRetarderTorque : 48|16@1+ (1,0) [0|64255] "Nm" Vector__XXX
 SG_ AxleLoadSum : 32|16@1+ (2,0) [0|128510] "kg" Vector__XXX
 SG_ SupplyLineBrakingRequest : 26|2@1+ (1,0) [0|1] "" Vector__XXX
 SG_ LoadingRampApproachAssist : 24|2@1+ (1,0) [0|1] "" Vector__XXX
 SG_ SpringBrakeEngaged : 22|2@1+ (1,0) [0|1] "" Vector__XXX
 SG_ ElectrLoadPropFunc : 18|2@1+ (1,0) [0|1] "" Vector__XXX
 SG_ SpringBrakeInstalled : 16|2@1+ (1,0) [0|1] "" Vector__XXX
 SG_ VehicleType : 20|2@1+ (1,0) [0|3] "" Vector__XXX
 SG_ ElecSupplyOfNonBrakingSys : 14|2@1+ (1,0) [0|1] "" Vector__XXX
 SG_ AmberWarningSignalReq : 12|2@1+ (1,0) [0|1] "" Vector__XXX
 SG_ RedWarningSignalRequest : 10|2@1+ (1,0) [0|1] "" Vector__XXX
 SG_ VehicleElectrSupplySuff : 8|2@1+ (1,0) [0|1] "" Vector__XXX
 SG_ AutomTowedVehBreakActive : 6|2@1+ (1,0) [0|1] "" Vector__XXX
 SG_ VehicleServiceBrakeActive : 4|2@1+ (1,0) [0|1] "" Vector__XXX
 SG_ VehicleRetarderCtrlActive : 2|2@1+ (1,0) [0|3] "" Vector__XXX
 SG_ VehicleABSActive : 0|2@1+ (1,0) [0|1] "" Vector__XXX

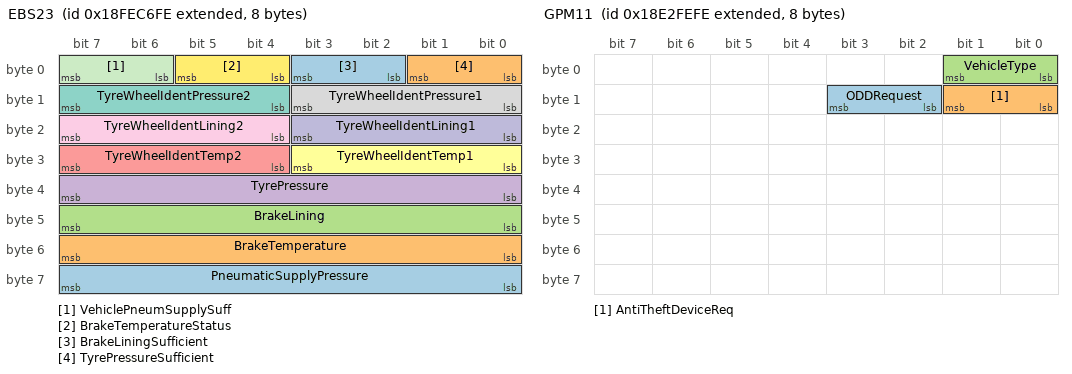
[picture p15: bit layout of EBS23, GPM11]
BO_ 2566833918 EBS23: 8 Vector__XXX
 SG_ PneumaticSupplyPressure : 56|8@1+ (5,0) [0|1250] "kPa" Vector__XXX
 SG_ BrakeTemperature : 48|8@1+ (10,0) [0|2500] "캜" Vector__XXX
 SG_ BrakeLining : 40|8@1+ (0.4,0) [0|100] "%" Vector__XXX
 SG_ TyrePressure : 32|8@1+ (10,0) [0|2500] "kPa" Vector__XXX
 SG_ TyreWheelIdentTemp2 : 28|4@1+ (1,0) [0|15] "" Vector__XXX
 SG_ TyreWheelIdentTemp1 : 24|4@1+ (1,0) [0|15] "" Vector__XXX
 SG_ TyreWheelIdentPressure2 : 12|4@1+ (1,0) [0|15] "" Vector__XXX
 SG_ TyreWheelIdentPressure1 : 8|4@1+ (1,0) [0|15] "" Vector__XXX
 SG_ TyreWheelIdentLining2 : 20|4@1+ (1,0) [0|15] "" Vector__XXX
 SG_ TyreWheelIdentLining1 : 16|4@1+ (1,0) [0|15] "" Vector__XXX
 SG_ VehiclePneumSupplySuff : 6|2@1+ (1,0) [0|1] "" Vector__XXX
 SG_ BrakeTemperatureStatus : 4|2@1+ (1,0) [0|1] "" Vector__XXX
 SG_ BrakeLiningSufficient : 2|2@1+ (1,0) [0|1] "" Vector__XXX
 SG_ TyrePressureSufficient : 0|2@1+ (1,0) [0|1] "" Vector__XXX

BO_ 2565013246 GPM11: 8 Vector__XXX
 SG_ ODDRequest : 10|2@1+ (1,0) [0|3] "" Vector__XXX
 SG_ AntiTheftDeviceReq : 8|2@1+ (1,0) [0|3] "" Vector__XXX
 SG_ VehicleType : 0|2@1+ (1,0) [0|3] "" Vector__XXX

BO_ 2566807038 GPM12: 8 Vector__XXX
 SG_ MaxVehicleSpeedLimit : 32|8@1+ (1,0) [0|250] "km/h" Vector__XXX
 SG_ EngineSpeedUpperLimit : 0|16@1+ (0.125,0) [0|8031.875] "rpm" Vector__XXX
 SG_ EngineSpeedLowerLimit : 16|16@1+ (0.125,0) [0|8191.875] "rpm" Vector__XXX

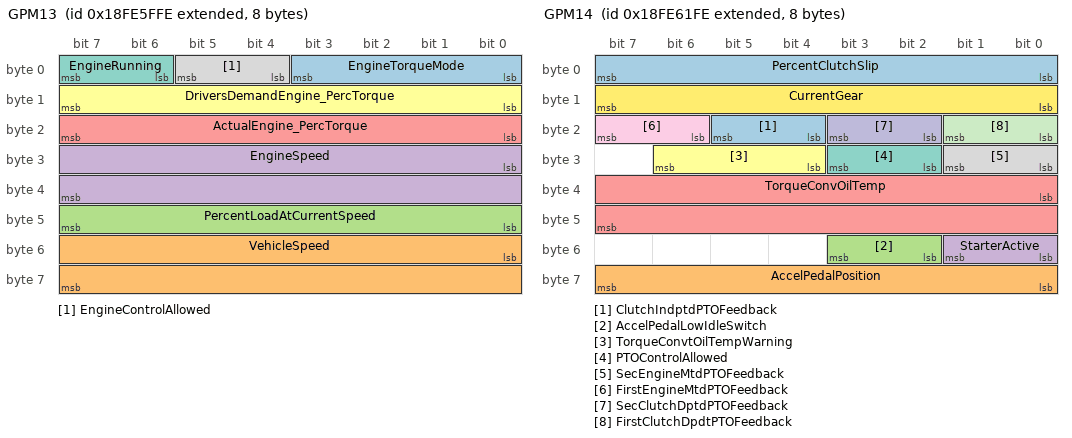
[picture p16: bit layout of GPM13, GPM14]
BO_ 2566807550 GPM13: 8 Vector__XXX
 SG_ EngineTorqueMode : 0|4@1+ (1,0) [0|15] "" Vector__XXX
 SG_ VehicleSpeed : 48|16@1+ (0.00390625,0) [0|250.996] "km/hr" Vector__XXX
 SG_ PercentLoadAtCurrentSpeed : 40|8@1+ (1,0) [0|125] "%" Vector__XXX
 SG_ EngineSpeed : 24|16@1+ (0.125,0) [0|8031.88] "rpm" Vector__XXX
 SG_ ActualEngine_PercTorque : 16|8@1+ (1,-125) [-125|125] "%" Vector__XXX
 SG_ DriversDemandEngine_PercTorque : 8|8@1+ (1,-125) [-125|125] "%" Vector__XXX
 SG_ EngineRunning : 6|2@1+ (1,0) [0|1] "" Vector__XXX
 SG_ EngineControlAllowed : 4|2@1+ (1,0) [0|1] "" Vector__XXX

BO_ 2566808062 GPM14: 8 Vector__XXX
 SG_ ClutchIndptdPTOFeedback : 20|2@1+ (1,0) [0|1] "" Vector__XXX
 SG_ AccelPedalPosition : 56|8@1+ (0.4,0) [0|100] "%" Vector__XXX
 SG_ AccelPedalLowIdleSwitch : 50|2@1+ (1,0) [0|1] "" Vector__XXX
 SG_ StarterActive : 48|2@1+ (1,0) [0|1] "" Vector__XXX
 SG_ TorqueConvOilTemp : 32|16@1+ (0.03125,-273) [-273|1735] "캜" Vector__XXX
 SG_ TorqueConvtOilTempWarning : 28|3@1+ (1,0) [0|2] "" Vector__XXX
 SG_ PTOControlAllowed : 26|2@1+ (1,0) [0|1] "" Vector__XXX
 SG_ SecEngineMtdPTOFeedback : 24|2@1+ (1,0) [0|1] "" Vector__XXX
 SG_ FirstEngineMtdPTOFeedback : 22|2@1+ (1,0) [0|1] "" Vector__XXX
 SG_ SecClutchDptdPTOFeedback : 18|2@1+ (1,0) [0|1] "" Vector__XXX
 SG_ FirstClutchDpdtPTOFeedback : 16|2@1+ (1,0) [0|1] "" Vector__XXX
 SG_ CurrentGear : 8|8@1+ (1,-125) [-125|125] "" Vector__XXX
 SG_ PercentClutchSlip : 0|8@1+ (0.4,0) [0|100] "%" Vector__XXX

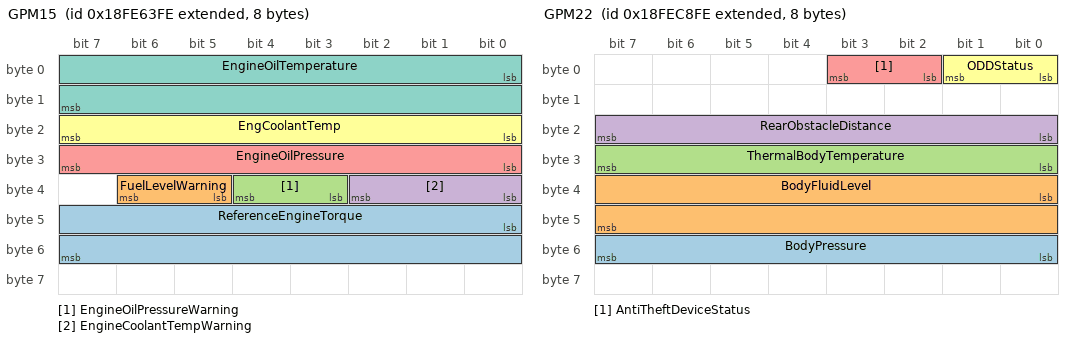
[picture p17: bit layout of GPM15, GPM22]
BO_ 2566808574 GPM15: 8 Vector__XXX
 SG_ ReferenceEngineTorque : 40|16@1+ (1,0) [0|64255] "Nm" Vector__XXX
 SG_ FuelLevelWarning : 37|2@1+ (1,0) [0|1] "" Vector__XXX
 SG_ EngineOilPressureWarning : 35|2@1+ (1,0) [0|1] "" Vector__XXX
 SG_ EngineCoolantTempWarning : 32|3@1+ (1,0) [0|2] "" Vector__XXX
 SG_ EngineOilPressure : 24|8@1+ (4,0) [0|1000] "kPa" Vector__XXX
 SG_ EngCoolantTemp : 16|8@1+ (1,-40) [-40|210] "캜" Vector__XXX
 SG_ EngineOilTemperature : 0|16@1+ (0.03125,-273) [-273|1735] "캜" Vector__XXX

BO_ 2566809086 GPM16: 8 Vector__XXX
 SG_ AmbientAirTemperature : 0|16@1+ (0.03125,-273) [-273|1735] "캜" Vector__XXX

BO_ 2564947710 GPM21: 8 Vector__XXX
 SG_ VehicleType : 0|2@1+ (1,0) [0|3] "" Vector__XXX

BO_ 2566834430 GPM22: 8 Vector__XXX
 SG_ BodyPressure : 48|8@1+ (0.1,0) [0|25] "bar" Vector__XXX
 SG_ BodyFluidLevel : 32|16@1+ (2,0) [0|128510] "L" Vector__XXX
 SG_ ThermalBodyTemperature : 24|8@1+ (1,-125) [-125|125] "캜" Vector__XXX
 SG_ RearObstacleDistance : 16|8@1+ (2,0) [0|500] "cm" Vector__XXX
 SG_ AntiTheftDeviceStatus : 2|2@1+ (1,0) [0|1] "" Vector__XXX
 SG_ ODDStatus : 0|2@1+ (1,0) [0|1] "" Vector__XXX

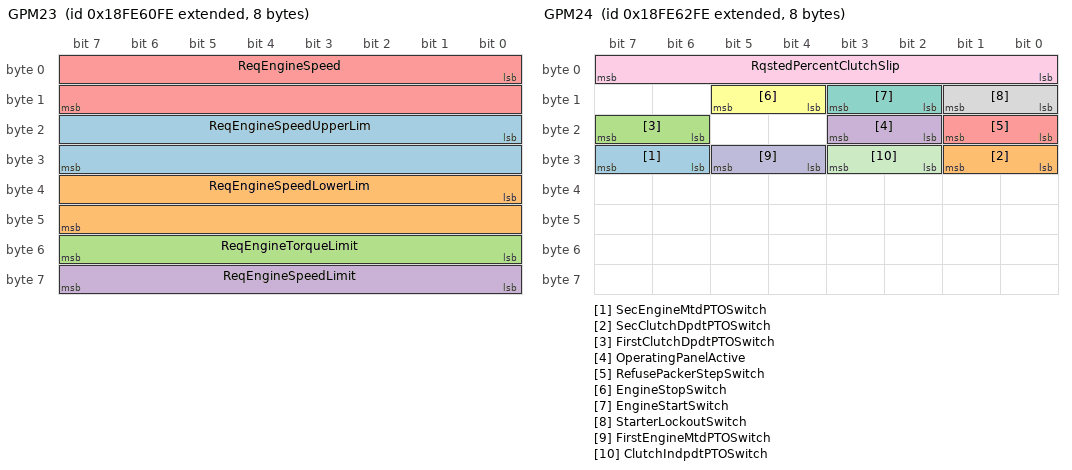
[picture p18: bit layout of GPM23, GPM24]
BO_ 2566807806 GPM23: 8 Vector__XXX
 SG_ ReqEngineSpeedUpperLim : 16|16@1+ (0.125,0) [0|8031.875] "rpm" Vector__XXX
 SG_ ReqEngineSpeedLowerLim : 32|16@1+ (0.125,0) [0|8031.875] "rpm" Vector__XXX
 SG_ ReqEngineTorqueLimit : 48|8@1+ (1,-125) [-125|125] "%" Vector__XXX
 SG_ ReqEngineSpeedLimit : 56|8@1+ (1,0) [0|250] "km/hr" Vector__XXX
 SG_ ReqEngineSpeed : 0|16@1+ (0.125,0) [0|8031.875] "rpm" Vector__XXX

BO_ 2566808318 GPM24: 8 Vector__XXX
 SG_ SecEngineMtdPTOSwitch : 30|2@1+ (1,0) [0|1] "" Vector__XXX
 SG_ SecClutchDpdtPTOSwitch : 24|2@1+ (1,0) [0|1] "" Vector__XXX
 SG_ FirstClutchDpdtPTOSwitch : 22|2@1+ (1,0) [0|1] "" Vector__XXX
 SG_ OperatingPanelActive : 18|2@1+ (1,0) [0|1] "" Vector__XXX
 SG_ RefusePackerStepSwitch : 16|2@1+ (1,0) [0|1] "" Vector__XXX
 SG_ EngineStopSwitch : 12|2@1+ (1,0) [0|1] "" Vector__XXX
 SG_ EngineStartSwitch : 10|2@1+ (1,0) [0|3] "" Vector__XXX
 SG_ StarterLockoutSwitch : 8|2@1+ (1,0) [0|1] "" Vector__XXX
 SG_ RqstedPercentClutchSlip : 0|8@1+ (0.4,0) [0|100] "%" Vector__XXX
 SG_ FirstEngineMtdPTOSwitch : 28|2@1+ (1,0) [0|1] "" Vector__XXX
 SG_ ClutchIndpdtPTOSwitch : 26|2@1+ (1,0) [0|1] "" Vector__XXX

BO_ 2566808830 GPM25: 8 Vector__XXX
 SG_ TrailerLeftSideMarkerLight : 20|2@1+ (1,0) [0|3] "" Vector__XXX
 SG_ TrailerLeftReversingLight : 16|2@1+ (1,0) [0|3] "" Vector__XXX
 SG_ TrailerLeftRearWidIndLight : 24|2@1+ (1,0) [0|3] "" Vector__XXX
 SG_ TrailerLeftRearRegPltLight : 32|2@1+ (1,0) [0|3] "" Vector__XXX
 SG_ TrailerLeftRearLight : 8|2@1+ (1,0) [0|3] "" Vector__XXX
 SG_ TrailerLeftRearFogLight : 12|2@1+ (1,0) [0|3] "" Vector__XXX
 SG_ TrailerLeftDirIndLight : 4|2@1+ (1,0) [0|3] "" Vector__XXX
 SG_ TrailerLeftCrnMarkerLight : 28|2@1+ (1,0) [0|3] "" Vector__XXX
 SG_ TrailerInteriorLight : 40|2@1+ (1,0) [0|3] "" Vector__XXX
 SG_ TrailerWorkLamp : 42|2@1+ (1,0) [0|3] "" Vector__XXX
 SG_ TrailerRotatingIdentLight : 38|2@1+ (1,0) [0|3] "" Vector__XXX
 SG_ TrailerRightStopLight : 2|2@1+ (1,0) [0|3] "" Vector__XXX
 SG_ TrailerRightSideMrkLight : 22|2@1+ (1,0) [0|3] "" Vector__XXX
 SG_ TrailerRightReversingLight : 18|2@1+ (1,0) [0|3] "" Vector__XXX
 SG_ TrailRightRearWidIndLight : 26|2@1+ (1,0) [0|3] "" Vector__XXX
 SG_ TrailerRightRearRegPltLight : 34|2@1+ (1,0) [0|3] "" Vector__XXX
 SG_ TrailerRightRearLight : 10|2@1+ (1,0) [0|3] "" Vector__XXX
 SG_ TrailerRightRearFogLight : 14|2@1+ (1,0) [0|3] "" Vector__XXX
 SG_ TrailerRightDirIndLight : 6|2@1+ (1,0) [0|3] "" Vector__XXX
 SG_ TrailerRightCrnMarkerLight : 30|2@1+ (1,0) [0|3] "" Vector__XXX
 SG_ TrailerRearWarningLight : 36|2@1+ (1,0) [0|3] "" Vector__XXX
 SG_ TrailerLeftStopLight : 0|2@1+ (1,0) [0|3] "" Vector__XXX

BO_ 2564554494 KWP1: 8 Vector__XXX
 SG_ SN m2 : 0|4@1+ (1,0) [0|15] "" Vector__XXX
 SG_ SeparationTime m3 : 16|8@1+ (1,0) [0|255] "ms" Vector__XXX
 SG_ BlockSize m3 : 8|8@1+ (1,0) [0|255] "" Vector__XXX
 SG_ FlowStatus m3 : 0|4@1+ (1,0) [0|3] "" Vector__XXX
 SG_ FirstFrameDataLength m1 : 3|12@0+ (1,0) [0|4095] "Byte" Vector__XXX
 SG_ SingleFrameDataLength m0 : 0|4@1+ (1,0) [0|7] "Byte" Vector__XXX
 SG_ ProtocolCtrlInformation M : 4|4@1+ (1,0) [0|3] "" Vector__XXX

BO_ 2564488958 KWP2: 8 Vector__XXX
 SG_ SN m2 : 0|4@1+ (1,0) [0|15] "" Vector__XXX
 SG_ SeparationTime m3 : 16|8@1+ (1,0) [0|255] "ms" Vector__XXX
 SG_ BlockSize m3 : 8|8@1+ (1,0) [0|255] "" Vector__XXX
 SG_ FlowStatus m3 : 0|4@1+ (1,0) [0|3] "" Vector__XXX
 SG_ FirstFrameDataLength m1 : 3|12@0+ (1,0) [0|4095] "Byte" Vector__XXX
 SG_ SingleFrameDataLength m0 : 0|4@1+ (1,0) [0|7] "Byte" Vector__XXX
 SG_ ProtocolCtrlInformation M : 4|4@1+ (1,0) [0|3] "" Vector__XXX

BO_ 2565734142 Nxx: 8 Vector__XXX
 SG_ NumberOfSA_NAMEPairs m67 : 16|8@1+ (1,0) [0|0] "" Vector__XXX
 SG_ ToPort m0 : 8|4@1+ (1,0) [0|15] "" Vector__XXX
 SG_ NetworkMessageControlByte M : 0|8@1+ (1,0) [0|255] "" Vector__XXX
 SG_ FilterMode m1 : 16|8@1+ (1,0) [0|255] "" Vector__XXX
 SG_ NIECUPort m64 : 8|4@1+ (1,0) [0|15] "" Vector__XXX
 SG_ FromPort m0 : 12|4@1+ (1,0) [0|15] "" Vector__XXX

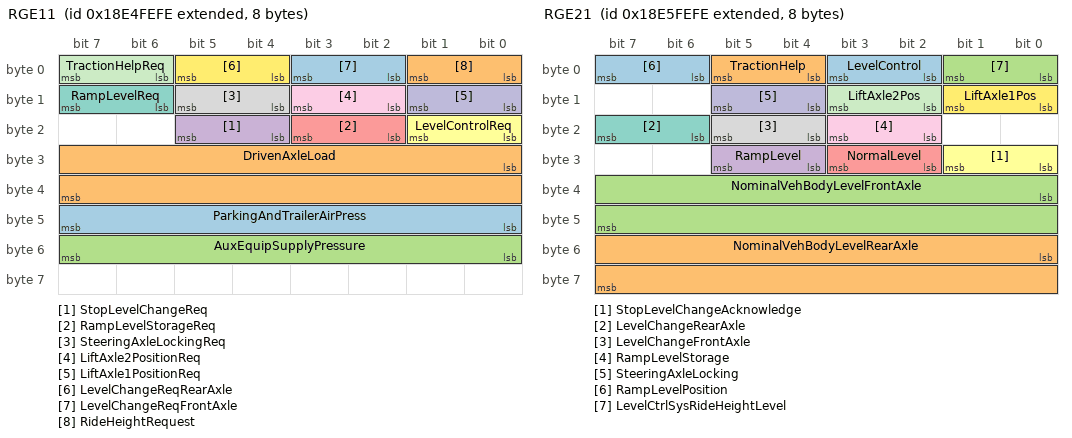
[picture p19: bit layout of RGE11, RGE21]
BO_ 2565144318 RGE11: 8 Vector__XXX
 SG_ ParkingAndTrailerAirPress : 40|8@1+ (8,0) [0|2000] "kPa" Vector__XXX
 SG_ DrivenAxleLoad : 24|16@1+ (2,0) [0|128510] "kg" Vector__XXX
 SG_ AuxEquipSupplyPressure : 48|8@1+ (8,0) [0|2000] "kPa" Vector__XXX
 SG_ StopLevelChangeReq : 20|2@1+ (1,0) [0|3] "" Vector__XXX
 SG_ RampLevelStorageReq : 18|2@1+ (1,0) [0|3] "" Vector__XXX
 SG_ LevelControlReq : 16|2@1+ (1,0) [0|3] "" Vector__XXX
 SG_ RampLevelReq : 14|2@1+ (1,0) [0|3] "" Vector__XXX
 SG_ SteeringAxleLockingReq : 12|2@1+ (1,0) [0|3] "" Vector__XXX
 SG_ LiftAxle2PositionReq : 10|2@1+ (1,0) [0|3] "" Vector__XXX
 SG_ LiftAxle1PositionReq : 8|2@1+ (1,0) [0|3] "" Vector__XXX
 SG_ TractionHelpReq : 6|2@1+ (1,0) [0|3] "" Vector__XXX
 SG_ LevelChangeReqRearAxle : 4|2@1+ (1,0) [0|3] "" Vector__XXX
 SG_ LevelChangeReqFrontAxle : 2|2@1+ (1,0) [0|3] "" Vector__XXX
 SG_ RideHeightRequest : 0|2@1+ (1,0) [0|3] "" Vector__XXX

BO_ 2565209854 RGE21: 8 Vector__XXX
 SG_ LevelControl : 2|2@1+ (1,0) [0|1] "" Vector__XXX
 SG_ NominalVehBodyLevelRearAxle : 48|16@1+ (1,0) [0|64255] "mm" Vector__XXX
 SG_ NominalVehBodyLevelFrontAxle : 32|16@1+ (1,0) [0|64255] "mm" Vector__XXX
 SG_ RampLevel : 28|2@1+ (1,0) [0|1] "" Vector__XXX
 SG_ NormalLevel : 26|2@1+ (1,0) [0|3] "" Vector__XXX
 SG_ StopLevelChangeAcknowledge : 24|2@1+ (1,0) [0|1] "" Vector__XXX
 SG_ LevelChangeRearAxle : 22|2@1+ (1,0) [0|1] "" Vector__XXX
 SG_ LevelChangeFrontAxle : 20|2@1+ (1,0) [0|1] "" Vector__XXX
 SG_ RampLevelStorage : 18|2@1+ (1,0) [0|1] "" Vector__XXX
 SG_ SteeringAxleLocking : 12|2@1+ (1,0) [0|3] "" Vector__XXX
 SG_ LiftAxle2Pos : 10|2@1+ (1,0) [0|3] "" Vector__XXX
 SG_ LiftAxle1Pos : 8|2@1+ (1,0) [0|3] "" Vector__XXX
 SG_ RampLevelPosition : 6|2@1+ (1,0) [0|3] "" Vector__XXX
 SG_ TractionHelp : 4|2@1+ (1,0) [0|1] "" Vector__XXX
 SG_ LevelCtrlSysRideHeightLevel : 0|2@1+ (1,0) [0|1] "" Vector__XXX

BO_ 2566806782 RGE22: 8 Vector__XXX
 SG_ RelVehBodyLevelRearAxle : 16|16@1+ (1,0) [0|64255] "mm" Vector__XXX
 SG_ RelVehBodyLevelFrontAxle : 0|16@1+ (1,-32000) [-32000|32255] "mm" Vector__XXX

CM_ BO_ 2365485822 "Laser Leveling System Blade Control";
CM_ SG_ 2365485822 LandLevelingSystemEnableStatus "Communicate the enable/disable status of the Land Leveling System.

00 = Disabled
01= Enabled
10 = Error
11 = Not available / Not installed";
CM_ SG_ 2365485822 BladeCtrlModeRight "Indicate if the land leveling system's automatic control is active or inactive for the elevation sensor on the right side of the blade.  The \"left\" notation is applicable to grading machines such tractors and motor graders where \"right\" is the ...";
CM_ SG_ 2365485822 BladeCtrlModeLeft "Indicate if the land leveling system's automatic control is active or inactive for the elevation sensor on the left side of the blade.  The \"left\" notation is applicable to grading machines such tractors and motor graders where \"left\" is the ...";
CM_ SG_ 2365485822 BladeCtrlMode "Allows the user to select the type of blade control for the land leveling system.  

00000000 Manual mode
00000001 Automatic mode
00000010 Inactive automatic mode
All other values Reserved";
CM_ SG_ 2365485822 BladeDurationAndDirection "Used to indicate the duration and direction that the land leveling system blade moves.";
CM_ BO_ 2633926654 "Ignition Timing 6";
CM_ SG_ 2633926654 EngActualIgntTiming "The actual ignition timing at the current engine conditions. This parameter may or may not be equal to one of the desired timing parameters (see SPNs 1433-1435), depending on the status of the engine. Positive values indicate an increasingly ...";
CM_ SG_ 2633926654 EngDesiredIgntTiming3 "A programmable timing value specific to the engine뭩 application. Factors affecting this value include both fuel type and the nature of the load being driven. Positive values indicate an increasingly advanced timing from TDC.";
CM_ SG_ 2633926654 EngDesiredIgntTiming2 "A programmable timing value specific to the engine뭩 application. Factors affecting this value include both fuel type and the nature of the load being driven. Positive values indicate an increasingly advanced timing from TDC.";
CM_ SG_ 2633926654 EngDesiredIgntTiming1 "A programmable timing value specific to the engine뭩 application. Factors affecting this value include both fuel type and the nature of the load being driven. Positive values indicate an increasingly advanced timing from TDC.";
CM_ BO_ 2633926398 "Ignition Timing 5";
CM_ SG_ 2633926398 EngCyl20IgntTiming "The ignition timing (SI engines) or main fuel injection timing (CI engines) of the cylinder. Positive values indicate an increasingly advanced timing from TDC.";
CM_ SG_ 2633926398 EngCyl19IgntTiming "The ignition timing (SI engines) or main fuel injection timing (CI engines) of the cylinder. Positive values indicate an increasingly advanced timing from TDC.";
CM_ SG_ 2633926398 EngCyl18IgntTiming "The ignition timing (SI engines) or main fuel injection timing (CI engines) of the cylinder. Positive values indicate an increasingly advanced timing from TDC.";
CM_ SG_ 2633926398 EngCyl17IgntTiming "The ignition timing (SI engines) or main fuel injection timing (CI engines) of the cylinder. Positive values indicate an increasingly advanced timing from TDC.";
CM_ BO_ 2633926142 "Ignition Timing 4";
CM_ SG_ 2633926142 EngCyl16IgntTiming "The ignition timing (SI engines) or main fuel injection timing (CI engines) of the cylinder. Positive values indicate an increasingly advanced timing from TDC.";
CM_ SG_ 2633926142 EngCyl15IgntTiming "The ignition timing (SI engines) or main fuel injection timing (CI engines) of the cylinder. Positive values indicate an increasingly advanced timing from TDC.";
CM_ SG_ 2633926142 EngCyl14IgntTiming "The ignition timing (SI engines) or main fuel injection timing (CI engines) of the cylinder. Positive values indicate an increasingly advanced timing from TDC.";
CM_ SG_ 2633926142 EngCyl13IgntTiming "The ignition timing (SI engines) or main fuel injection timing (CI engines) of the cylinder. Positive values indicate an increasingly advanced timing from TDC.";
CM_ BO_ 2633925886 "Ignition Timing 3";
CM_ SG_ 2633925886 EngCyl12IgntTiming "The ignition timing (SI engines) or main fuel injection timing (CI engines) of the cylinder. Positive values indicate an increasingly advanced timing from TDC.";
CM_ SG_ 2633925886 EngCyl11IgntTiming "The ignition timing (SI engines) or main fuel injection timing (CI engines) of the cylinder. Positive values indicate an increasingly advanced timing from TDC.";
CM_ SG_ 2633925886 EngCyl10IgntTiming "The ignition timing (SI engines) or main fuel injection timing (CI engines) of the cylinder. Positive values indicate an increasingly advanced timing from TDC.";
CM_ SG_ 2633925886 EngCyl9IgntTiming "The ignition timing (SI engines) or main fuel injection timing (CI engines) of the cylinder. Positive values indicate an increasingly advanced timing from TDC.";
CM_ BO_ 2633925630 "Ignition Timing 2";
CM_ SG_ 2633925630 EngCyl8IgntTiming "The ignition timing (SI engines) or main fuel injection timing (CI engines) of the cylinder. Positive values indicate an increasingly advanced timing from TDC.";
CM_ SG_ 2633925630 EngCyl7IgntTiming "The ignition timing (SI engines) or main fuel injection timing (CI engines) of the cylinder. Positive values indicate an increasingly advanced timing from TDC.";
CM_ SG_ 2633925630 EngCyl6IgntTiming "The ignition timing (SI engines) or main fuel injection timing (CI engines) of the cylinder. Positive values indicate an increasingly advanced timing from TDC.";
CM_ SG_ 2633925630 EngCyl5IgntTiming "The ignition timing (SI engines) or main fuel injection timing (CI engines) of the cylinder. Positive values indicate an increasingly advanced timing from TDC.";
CM_ BO_ 2633925374 "Ignition Timing 1";
CM_ SG_ 2633925374 EngCyl4IgntTiming "The ignition timing (SI engines) or main fuel injection timing (CI engines) of the cylinder. Positive values indicate an increasingly advanced timing from TDC.";
CM_ SG_ 2633925374 EngCyl3IgntTiming "The ignition timing (SI engines) or main fuel injection timing (CI engines) of the cylinder. Positive values indicate an increasingly advanced timing from TDC.";
CM_ SG_ 2633925374 EngCyl2IgntTiming "The ignition timing (SI engines) or main fuel injection timing (CI engines) of the cylinder. Positive values indicate an increasingly advanced timing from TDC.";
CM_ SG_ 2633925374 EngCyl1IgntTiming "The ignition timing (SI engines) or main fuel injection timing (CI engines) of the cylinder. Positive values indicate an increasingly advanced timing from TDC.";
CM_ BO_ 2633927422 "Ignition Transformer Secondary Output 3";
CM_ SG_ 2633927422 EngCyl20IgntTransSecondOutput "This parameter indicates the relative intensity of the secondary output voltage of the ignition transformer.";
CM_ SG_ 2633927422 EngCyl19IgntTransSecondOutput "This parameter indicates the relative intensity of the secondary output voltage of the ignition transformer.";
CM_ SG_ 2633927422 EngCyl18IgntTransSecondOutput "This parameter indicates the relative intensity of the secondary output voltage of the ignition transformer.";
CM_ SG_ 2633927422 EngCyl17IgntTransSecondOutput "This parameter indicates the relative intensity of the secondary output voltage of the ignition transformer.";
CM_ BO_ 2633927166 "Ignition Transformer Secondary Output 2";
CM_ SG_ 2633927166 EngCyl16IgntTransSecondOutput "This parameter indicates the relative intensity of the secondary output voltage of the ignition transformer.";
CM_ SG_ 2633927166 EngCyl15IgntTransSecondOutput "This parameter indicates the relative intensity of the secondary output voltage of the ignition transformer.";
CM_ SG_ 2633927166 EngCyl14IgntTransSecondOutput "This parameter indicates the relative intensity of the secondary output voltage of the ignition transformer.";
CM_ SG_ 2633927166 EngCyl13IgntTransSecondOutput "This parameter indicates the relative intensity of the secondary output voltage of the ignition transformer.";
CM_ SG_ 2633927166 EngCyl12IgntTransSecondOutput "This parameter indicates the relative intensity of the secondary output voltage of the ignition transformer.";
CM_ SG_ 2633927166 EngCyl11IgntTransSecondOutput "This parameter indicates the relative intensity of the secondary output voltage of the ignition transformer.";
CM_ SG_ 2633927166 EngCyl10IgntTransSecondOutput "This parameter indicates the relative intensity of the secondary output voltage of the ignition transformer.";
CM_ SG_ 2633927166 EngCyl9IgntTransSecondOutput "This parameter indicates the relative intensity of the secondary output voltage of the ignition transformer.";
CM_ BO_ 2633926910 "Ignition Transformer Secondary Output 1";
CM_ SG_ 2633926910 EngCyl8IgntTransSecondOutput "This parameter indicates the relative intensity of the secondary output voltage of the ignition transformer.";
CM_ SG_ 2633926910 EngCyl7IgntTransSecondOutput "This parameter indicates the relative intensity of the secondary output voltage of the ignition transformer.";
CM_ SG_ 2633926910 EngCyl6IgntTransSecondOutput "This parameter indicates the relative intensity of the secondary output voltage of the ignition transformer.";
CM_ SG_ 2633926910 EngCyl5IgntTransSecondOutput "This parameter indicates the relative intensity of the secondary output voltage of the ignition transformer.";
CM_ SG_ 2633926910 EngCyl4IgntTransSecondOutput "This parameter indicates the relative intensity of the secondary output voltage of the ignition transformer.";
CM_ SG_ 2633926910 EngCyl3IgntTransSecondOutput "This parameter indicates the relative intensity of the secondary output voltage of the ignition transformer.";
CM_ SG_ 2633926910 EngCyl2IgntTransSecondOutput "This parameter indicates the relative intensity of the secondary output voltage of the ignition transformer.";
CM_ SG_ 2633926910 EngCyl1IgntTransSecondOutput "This parameter indicates the relative intensity of the secondary output voltage of the ignition transformer.";
CM_ BO_ 2566768894 "Operator Primary Intermediate Speed Control state
The Operator Primary Intermediate Speed Control State is used to provide the controller feedback to indicate the controls state achieved.";
CM_ SG_ 2566768894 EngOprtrPrmryIntrmdtSpdSlctState "13 preprogrammed intermediate speed control settings are available for the controlling ECM to select.  If no speed setting is requested, the engine operates normally. The Intermediate Speed Control is widely used in the Industrial application to ...";
CM_ BO_ 2566769406 "Intermediate Speed Control
The Intermediate Speed Control is widely used in the Industrial application to control the engine to an intermediate speed setting which can bypass the accelerator position control. An example of this operation would be ...";
CM_ SG_ 2566769406 EngOprtrPrmryIntrmdteSpeedSelect "Allows the operator to select one of 13 preprogrammed Intermediate Speed Control settings. If no speed setting is requested, the engine operates normally. The Intermediate Speed Control is widely used in the Industrial application to control the ...";
CM_ BO_ 2566839550 "Idle Operation";
CM_ SG_ 2566839550 EngTotalIdleHours "Accumulated time of operation of the engine while under idle conditions.";
CM_ SG_ 2566839550 EngTotalIdleFuelUsed "Accumulated amount of fuel used during vehicle operation while under idle conditions.";
CM_ BO_ 2633934334 "Intake Manifold Information 2";
CM_ SG_ 2633934334 EngIntakeManifold6Temp "Temperature of pre-combustion air found in intake manifold  number 6 of engine air supply system.";
CM_ SG_ 2633934334 EngIntakeManifold5Temp "Temperature of pre-combustion air found in intake manifold number 5 of engine air supply system.";
CM_ SG_ 2633934334 EngIntakeManifold4Temp "Temperature of pre-combustion air found in intake manifold of engine air supply system.";
CM_ SG_ 2633934334 EngIntakeManifold3Temp "Temperature of pre-combustion air found in intake manifold of engine air supply system.";
CM_ SG_ 2633934334 EngIntakeManifold2Temp "Temperature of pre-combustion air found in intake manifold of engine air supply system.";
CM_ BO_ 2566825726 "Intake Manifold Information 1";
CM_ SG_ 2566825726 EngTurbo4BoostPress "Gage pressure of air measured downstream of the compressor discharge side of the turbocharger.  See also SPN 102 for alternate range and resolution. If there is only one boost pressure to report and the range and resolution in SPN 102 is adequate, ...";
CM_ SG_ 2566825726 EngTurbo3BoostPress "Gage pressure of air measured downstream of the compressor discharge side of the turbocharger.  See also SPN 102 for alternate range and resolution. If there is only one boost pressure to report and the range and resolution in SPN 102 is adequate, ...";
CM_ SG_ 2566825726 EngTurbo2BoostPress "Gage pressure of air measured downstream of the compressor discharge side of the turbocharger.  See also SPN 102 for alternate range and resolution. If there is only one boost pressure to report and the range and resolution in SPN 102  is adequate, ...";
CM_ SG_ 2566825726 EngTurbo1BoostPress "Gage pressure of air measured downstream of the compressor discharge side of the turbocharger.  See also SPN 102 for alternate range and resolution. If there is only one boost pressure to report and the range and resolution in SPN 102 is adequate, ...";
CM_ BO_ 2566770942 "Intake/Exhaust Conditions 2
Intake/Exhaust Conditions 2 is a second PGN conveying this type of engine information. Also see PGN 65270.";
CM_ SG_ 2566770942 EngIntakeManifold2AbsPress "The absolute pressure measurement of the air intake manifold for bank 2 or the second air intake manifold. If there are multiple air pressure sensors in the intake stream, this is the last one in flow direction before entering the combustion ...";
CM_ SG_ 2566770942 EngIntakeManifold1AbsPress4817 "The absolute pressure measurement of the air intake manifold. If there are multiple air pressure sensors in the intake stream, this is the last one in flow direction before entering the combustion chamber.  This SPN is a high resolution measurement ...";
CM_ SG_ 2566770942 EngIntakeManifold1AbsPress "The absolute pressure measurement of the air intake manifold. If there are multiple air pressure sensors in the intake stream, this is the last one in flow direction before entering the combustion chamber.";
CM_ SG_ 2566770942 EngIntakeManifold2Press "The gage pressure measurement of the air intake manifold for bank #2 or the second air intake manifold. If there are multiple air pressure sensors in the second intake stream, this is the last one in flow direction before entering the combustion ...";
CM_ SG_ 2566770942 EngAirFilter4DiffPress "Change in engine air system pressure, measured across the fourth air filter, due to the filter and any accumulation of solid foreign matter on or in the filter.
This is for monitoring the air filter on the intake to the fourth turbocharger. Filter ...";
CM_ SG_ 2566770942 EngAirFilter3DiffPress "Change in engine air system pressure, measured across the third air filter, due to the filter and any accumulation of solid foreign matter on or in the filter.
This is for monitoring the air filter on the intake to the third turbocharger. Filter ...";
CM_ SG_ 2566770942 EngAirFilter2DiffPress "Change in engine air system pressure, measured across the second air filter, due to the filter and any accumulation of solid foreign matter on or in the filter.
This is for monitoring the air filter on the intake to the second turbocharger. Filter ...";
CM_ BO_ 2566846206 "Intake/Exhaust Conditions 1";
CM_ SG_ 2566846206 EngCoolantFilterDiffPress "Change in coolant pressure, measured across the filter, due to the filter and any accumulation of solid or semisolid matter on or in the filter.";
CM_ SG_ 2566846206 EngExhaustGasTemp "Temperature of combustion byproducts leaving the engine.  See SPNs 2433, 2434, 5969 and 5970 for engines with more than one exhaust temperature measurement.";
CM_ SG_ 2566846206 EngAirFilter1DiffPress "Change in engine air system pressure, measured across the filter, due to the filter and any accumulation of solid foreign matter on or in the filter.
This is the measurement of the first filter in a multiple air filter system.  In a single air ...";
CM_ SG_ 2566846206 EngAirIntakePress "Absolute air pressure at input port to intake manifold or air box.";
CM_ SG_ 2566846206 EngIntakeManifold1Temp "Temperature of pre-combustion air found in intake manifold of engine air supply system.";
CM_ SG_ 2566846206 EngIntakeManifold1Press "The gage pressure measurement of the air intake manifold. If there are multiple air pressure sensors in the intake stream, this is the last one in flow direction before entering the combustion chamber.  This should be the pressure used to drive ...";
CM_ SG_ 2566846206 AFT1DPFInPress "Exhaust pressure as a result of particle accumulation on filter media placed in the exhaust stream.  It is recommended that SPN 3609 be used as it has better resolution.";
CM_ BO_ 2566811134 "Heater Information";
CM_ SG_ 2566811134 ADRCompliantHeaterInstallation "Indicates that the heater is installed in an ADR compliant vehicle.
00 -  Heater installation is not ADR compliant
01 -  Heater installation is ADR compliant
10 -  Error
11 -  Not Available
Note:  ADR is a European agreement concerning the ...";
CM_ SG_ 2566811134 CabHeatingZone "Parameter indicating whether the cab zone is being heated.

00 Cab heating zone off
01 Cab heating zone on
10 Reserved
11 Not available";
CM_ SG_ 2566811134 EngHeatingZone "Parameter indicating whether the engine zone is being heated.

00 Engine heating zone off
01 Engine heating zone on
10 Reserved
11 Not available";
CM_ SG_ 2566811134 CabVentilation "Indicates whether the cab is being ventilated or not.

00 Cab not ventilated
01 Cab is ventilated
10 Reserved
11 Not available";
CM_ SG_ 2566811134 AuxHeaterWaterPumpStatus "Parameter indicating whether the auxiliary heater water pump is running

00 Water Pump is not running
01 Water Pump is  running
10 Reserved
11 Not available";
CM_ SG_ 2566811134 AuxHeaterMode "State of the auxiliary heater
0000 Heater not active
0001 Off due to ADR per European Regulations for Transport of hazardous materials
0010 Economy mode
0011 Normal mode
0100 Heater pump up-keep   (running the equipment in order to keep it in ...";
CM_ SG_ 2566811134 AuxHeaterOutputPowerPercent "Current auxiliary heater output power, relative to the auxiliary heater maximum output power.";
CM_ SG_ 2566811134 AuxHeaterInputAirTemp "Temperature of the input air in an auxiliary heater system.";
CM_ SG_ 2566811134 AuxHeaterOutputCoolantTemp "Temperature of the auxiliary heater output coolant (I.e. water in a water heater system.)";
CM_ BO_ 2298375934 "High Resolution Wheel Speed";
CM_ SG_ 2298375934 RearAxleRightWheelSpeed "High resolution measurement of the speed of the right wheel on the rear axle.";
CM_ SG_ 2298375934 RearAxleLeftWheelSpeed "High resolution measurement of the speed of the left wheel on the rear axle.";
CM_ SG_ 2298375934 FrontAxleRightWheelSpeed "High resolution measurement of the speed of the right wheel on the front axle.";
CM_ SG_ 2298375934 FrontAxleLeftWheelSpeed "High resolution measurement of the speed of the left wheel on the front axle.";
CM_ BO_ 2565867774 "Hydraulic Pressure Governor Info
Information to be used for a hydraulic pressure governing control system";
CM_ SG_ 2565867774 FireApparatusPumpEngagement "The measured status of the pump used to provide water in fire fighting apparatus for distribution of water through water cannons or fire hoses.

00 Pump not engaged
01 Pump engaged
10 Error
11 Not available or not installed";
CM_ SG_ 2565867774 HydPressGovernorPresetSwitch "Switch that commands hydraulic pressure governor to increase or decrease engine rpm to achieve a predefined discharge pressure.

00 Preset Switch Inactive
01 Preset Switch Active
10 Error
11 Not available";
CM_ SG_ 2565867774 HydPressGovernorIncreaseSwitch "Switch that commands hydraulic pressure governor to increase engine rpm resulting in expected increase of hydraulic discharge pressure.

00 Increase Switch Inactive
01 Increase Switch Active
10 Error
11 Not available";
CM_ SG_ 2565867774 HydPressGovernorDecreaseSwitch "Switch that commands hydraulic pressure governor to decrease engine rpm resulting in expected decrease of hydraulic discharge pressure.

00 Decrease Switch Inactive
01 Decrease Switch Active
10 Error
11 Not available";
CM_ SG_ 2565867774 HydPressGovernorIdleSwitch "Switch that commands hydraulic pressure governor to decrease engine rpm to its idle position.

00 Idle Switch Inactive
01 Idle Switch Active
10 Error
11 Not available";
CM_ SG_ 2565867774 HydDischargePressSetPoint "Hydraulic pressure governing system discharge pressure set point.";
CM_ SG_ 2565867774 HydIntakePress "Hydraulic pressure measured at the intake of the hydraulic pump.";
CM_ SG_ 2565867774 FireApparatusOkayToPumpInterlock "The measured state of the Okay To Pump interlock of the fire apparatus.
00 Okay to Pump Interlock Inactive
01 Okay to Pump Interlock Active
10 Error
11 Not Available
Note: \"Okay to Pump\" is incorporated into the NFPA 1901 Standard for Fire ...";
CM_ SG_ 2565867774 EngHydPressGovernorSwitch "Switch that sets the  mode of hydraulic governor

00 Pressure Mode Inactive
01 Pressure Mode Active
10 Error Indicator
11 Not Available";
CM_ SG_ 2565867774 EngHydPressGovernorModeIndicator "Mode for governor operation is hydraulic pressure control.

00 Disabled
01 Enabled
10 Error Indicator
11 Not Available";
CM_ SG_ 2565867774 HydPress "Hydraulic pressure measured at the output of the hydraulic pump.";
CM_ BO_ 2566841854 "Engine Hours, Revolutions";
CM_ SG_ 2566841854 EngTotalRevolutions "Accumulated number of revolutions of engine crankshaft during its operation.";
CM_ SG_ 2566841854 EngTotalHoursOfOperation "Accumulated time of operation of engine.";
CM_ BO_ 2365449982 "Hydraulic Braking System
Used for information on a hydraulic brake system
As an example: this PGN may be used for a two circuit hydraulic brake system with separate circuits for front and rear axle. The hydraulic energy is supplied via two ...";
CM_ SG_ 2365449982 HydBrakeFluidLevelSwitch "Signal which indicates whether the hydraulic fluid level in the reservoir(s) is sufficient.

00      Fluid level is not sufficient
01      Fluid level is sufficient
10      Error indicator
11      Not available";
CM_ SG_ 2365449982 HydBrakeSystemAudibleWarningCmd "Signal which commands an audible warning by the hydraulic braking system.

00       Audible warning off
01       Audible warning on
10       Reserved
11       Don't care";
CM_ SG_ 2365449982 HydBrakePressSupplyStateCircuit2 "Signal which indicates whether the hydraulic brake pressure supply of circuit 2 is reliable; that is, able to support continued braking.

00 Supply is not reliable
01 Supply is reliable
10 Error indicator
11 Not available";
CM_ SG_ 2365449982 HydBrakePressSupplyStateCircuit1 "Signal which indicates whether the hydraulic brake pressure supply of circuit 1 is reliable; that is, able to support continued braking.

00 Supply is not reliable
01 Supply is reliable
10 Error indicator
11 Not available";
CM_ SG_ 2365449982 HydBrkePressWarningStateCircuit2 "Signal which indicates whether the hydraulic brake pressure of circuit 2 is below the warning level

00 Pressure level sufficient
01 Pressure level below warning level
10 Error indicator
11 Not available";
CM_ SG_ 2365449982 HydBrkePressWarningStateCircuit1 "Signal which indicates whether the hydraulic brake pressure of circuit 1 is below the warning level

00 Pressure level sufficient
01 Pressure level below warning level
10 Error indicator
11 Not available";
CM_ SG_ 2365449982 HydBrakePressCircuit2 "Gage hydraulic pressure in circuit 2 of the hydraulic brake system";
CM_ SG_ 2365449982 HydBrakePressCircuit1 "Gage hydraulic pressure in circuit 1 of the hydraulic brake system";
CM_ BO_ 2633939198 "Trip Fuel Information (Gaseous)";
CM_ SG_ 2633939198 TripDriveFuelEconomy "Trip drive fuel economy is equal to the distance traveled by vehicle in the drive state (engine speed greater than zero, vehicle speed greater than or equal to 2 km/h, and neither the PTO or remote PTO governors are controlling engine power output) ...";
CM_ SG_ 2633939198 TripCruiseFuelUsed "Total fuel consumed while the engine is in the cruise hold state since the last trip reset.  If both cruise control and VSL (vehicle speed limiter) are commanding the same amount of fuel, the cruise control is deemed the active torque mode and fuel ...";
CM_ SG_ 2633939198 TripVehicleIdleFuelUsed "Total fuel consumed while neither the PTO or remote PTO governors are active, the engine speed is greater than zero, and vehicle speed is less than to 2 km/h, since the last trip reset.
NOTE뾗his parameter is intended for gaseous fueled engines ...";
CM_ SG_ 2633939198 TripPTOGovernorNonmovingFuelUsed "Total fuel consumed while the PTO or remote PTO governors are in the hold state, the engine speed is greater than zero, and vehicle speed is less than to 2 km/h, since the last trip reset.
NOTE뾗his parameter is intended for gaseous fueled engines ...";
CM_ SG_ 2633939198 TripPTOGovernorMovingFuelUsed "Total fuel consumed while the PTO or remote PTO governors are in the hold state, the engine speed is greater than zero, and vehicle speed is greater than or equal to 2 km/h, since the last trip reset.
NOTE뾗his parameter is intended for gaseous ...";
CM_ SG_ 2633939198 TripDriveFuelUsed "Total fuel consumed while the engine speed is greater than zero, vehicle speed is greater than or equal to 2 km/h, and neither the PTO or the remote PTO governors are controlling the engine power output, since the last trip reset.
NOTE뾗his ...";
CM_ BO_ 2633927678 "Gaseous Fuel Pressure 1";
CM_ SG_ 2633927678 EngFuelValve1OutletAbsPress "Absolute Pressure of gas on outlet side of the first or only fuel system control valve.  See SPN 3469 for the second fuel control valve.";
CM_ SG_ 2633927678 EngAirToFuelDiffPress "The differential pressure between the gaseous fuel and the air intake manifold.";
CM_ SG_ 2633927678 EngFuelValveDiffPress "The differential pressure between the intake and the outlet of the first or only gaseous fuel valve.

See SPN 8494 for alternate range and resolution.";
CM_ SG_ 2633927678 EngFuelValve1IntakeAbsPress "The absolute pressure of gas on the intake side of the first system control valve.  See SPN 3466 for Engine Fuel Valve 2, 7505 for Engine Fuel Valve 3 & 7506 for Engine Fuel Valve 4.";
CM_ BO_ 2633925118 "Fuel Information 2 (Gaseous)
Gaseous fuel information 2";
CM_ SG_ 2633925118 EngRequestedFuelValve2Pos "The commanded position of the second fuel valve that is metering the fuel flow to the engine.";
CM_ SG_ 2633925118 EngRequestedFuelValve1Pos "The commanded position of the first fuel valve that is metering the fuel flow to the engine.";
CM_ SG_ 2633925118 EngFuelValve2Pos "The position of a gaseous fuel valve that is metering the fuel flow to the engine.  0% indicates no fuel flow through valve and 100% means maximum fuel flow through valve.";
CM_ SG_ 2633925118 EngFuelValve1Pos "The position of a gaseous fuel valve that is metering the fuel flow to the engine.  0% indicates no fuel flow through valve and 100% means maximum fuel flow through valve.";
CM_ SG_ 2633925118 EngFuelFlowRate2 "The rate at which the fuel is flowing through a fuel valve.";
CM_ SG_ 2633925118 EngFuelFlowRate1 "The rate at which the fuel is flowing through a fuel valve.";
CM_ BO_ 2633937662 "Fuel Information 1 (Gaseous)";
CM_ SG_ 2633937662 EngFuelSpecificGravity "This parameter conveys the specific gravity of the gaseous fuel being used by the engine.  The specific gravity of the fuel can then be used to compute the density of the fuel.";
CM_ SG_ 2633937662 TripAverageFuelRate "Average fuel rate, equal to trip fuel divided by trip time while the engine speed is above zero, since the last trip reset.  This includes idle, engine PTO governor (both moving and non-moving) and drive operation but excludes ignition-on time while ...";
CM_ SG_ 2633937662 TotalEngPTOGovernorFuelUsed "Total fuel used while the PTO or remote PTO governors are in the hold state and engine speed is above zero, over the life of the engine.

NOTE뾗his parameter is intended for gaseous fueled engines.  See SPN 1028 for alternate resolution.";
CM_ BO_ 2566804990 "Gaseous Fuel Properties";
CM_ SG_ 2566804990 FuelEnergyContent "Energy content (lower heating value) of the gaseous fuel.
Note:  For gaseous fuels, the fuel's energy content (lower heating value) is commonly defined in terms of energy / volume. The gas volume is defined for regular pressure and temperature ...";
CM_ SG_ 2566804990 ReferenceEngGasMassFlowRate "Configuration of the mass flow rate of gaseous fuel expected for 100% engine fuel valve control command.
Note:  The actuator will request this parameter from the ECU in order to determine what mass fuel flow to associate with a command of 100% from ...";
CM_ SG_ 2566804990 SpecificHeatRatio "The specific heat ratio of the fuel.";
CM_ BO_ 2633936894 "Fuel Consumption (Gaseous)";
CM_ SG_ 2633936894 TotalFuelUsed "Total fuel consumed (trip drive fuel + trip PTO governor moving fuel + trip PTO governor non-moving fuel + trip idle fuel) over the life of the engine.";
CM_ SG_ 2633936894 TripFuel "Total fuel consumed (trip drive fuel + trip PTO governor moving fuel + trip PTO governor non-moving fuel + trip idle fuel) since the last trip reset.";
CM_ BO_ 2566757630 "Sensor Electrical Power #2
Voltage supplies for sensors #2";
CM_ SG_ 2566757630 SensorSupplyVoltage8 "Sensor ECU supply voltage 8";
CM_ SG_ 2566757630 SensorSupplyVoltage7 "Sensor ECU supply voltage 7";
CM_ SG_ 2566757630 SensorSupplyVoltage6 "Sensor ECU supply voltage 6";
CM_ SG_ 2566757630 SensorSupplyVoltage5 "Sensor ECU supply voltage 5";
CM_ BO_ 2566757886 "Sensor Electrical Power #1
Voltage supplies for sensors #1";
CM_ SG_ 2566757886 SensorSupplyVoltage4 "Sensor ECU supply voltage 4";
CM_ SG_ 2566757886 SensorSupplyVoltage3 "Sensor ECU supply voltage 3";
CM_ SG_ 2566757886 SensorSupplyVoltage2 "Sensor ECU supply voltage 2";
CM_ SG_ 2566757886 SensorSupplyVoltage1 "Sensor ECU supply voltage 1";
CM_ BO_ 2566759678 "PTO Drive Engagement
Information relating to the request for engagement, consent for engagement, and status of engagement of various specific physical PTO drives.  This message may be broadcast by one or all controllers involved in the enabling of ...";
CM_ SG_ 2566759678 AtLeastOnePTOEngaged "Indicates that at least one PTO is engaged
00 No PTO drive is engaged
01 At least one PTO drive is engaged
10 Error
11 Not available
Note:  This parameter should only be sent by the controller that has knowledge of all PTO drives on the vehicle ...";
CM_ SG_ 2566759678 EnggmntSttsPTOEngAccessoryDrive2 "Engagement status of the PTO engine accessory drive 2

00 Drive not engaged
01 Drive engaged
10 Error
11 Not available";
CM_ SG_ 2566759678 EnggmntSttsPTOEngAccessoryDrive1 "Engagement status of the PTO engine accessory drive 1

00 Drive not engaged
01 Drive engaged
10 Error
11 Not available";
CM_ SG_ 2566759678 EngagementStatusPTOEngFlywheel "Engagement status of the PTO Engine Flywheel

00 Drive not engaged
01 Drive engaged
10 Error
11 Not available";
CM_ SG_ 2566759678 EnggmntStatusTransInputShaftPTO1 "Reports if this specific PTO drive is engaged.  This parameter should be broadcast only by the controller(s) receiving feedback about the specific drive.
For example, a pressure switch may be used to determine if a PTO-driven pump has been engaged ...";
CM_ SG_ 2566759678 EnggmntStatusTransInputShaftPTO2 "Reports if this specific PTO drive is engaged.  This parameter should be broadcast only by the controller(s) receiving feedback about the specific drive.
For example, a pressure switch may be used to determine if a PTO-driven pump has been engaged ...";
CM_ SG_ 2566759678 EnggmntStatusTransOutputShaftPTO "Reports if this specific PTO drive is engaged.  This parameter should be broadcast only by the controller(s) receiving feedback about the specific drive.
For example, a pressure switch may be used to determine if a PTO-driven pump has been engaged ...";
CM_ SG_ 2566759678 EnggmntSttsTrnsfrCsOtputShaftPTO "Reports if this specific PTO drive is engaged.  This parameter should be broadcast only by the controller(s) receiving feedback about the specific drive.
For example, a pressure switch may be used to determine if a PTO-driven pump has been engaged ...";
CM_ SG_ 2566759678 EnggmntCnsntPTOEngAccssoryDrive2 "Engagement Consent status for the PTO engine accessory drive 2 

00 Consent not given - PTO drive may not be engaged
01 Consent given - PTO drive may be engaged
10 Error
11 Not available";
CM_ SG_ 2566759678 EnggmntCnsntPTOEngAccssoryDrive1 "Engagement consent status for the PTO engine accessory drive 1

00 Consent not given - PTO drive may not be engaged
01 Consent given - PTO drive may be engaged
10 Error
11 Not available";
CM_ SG_ 2566759678 EngagementConsentPTOEngFlywheel "Engagement Consent status for the PTO Engine Flywheel

00 Consent not given - PTO drive may not be engaged
01 Consent given - PTO drive may be engaged
10 Error
11 Not available";
CM_ SG_ 2566759678 EnggmntCnsentTransInputShaftPTO1 "Status of the transmission controller뭩 consent to engage the first or sole PTO drive mounted on the transmission case.  The controller in charge of the PTO drive should monitor this parameter and only engage the drive when consent is given.  If ...";
CM_ SG_ 2566759678 EnggmntCnsentTransInputShaftPTO2 "Status of the transmission controller뭩 consent to engage the second PTO drive mounted on the transmission case.  The controller in charge of the PTO drive should monitor this parameter and only engage the drive when consent is given.  If consent is ...";
CM_ SG_ 2566759678 EnggmntCnsentTransOutputShaftPTO "Status of the transmission controller뭩 consent to engage the PTO drive connected to the transmission output shaft.  The controller in charge of the PTO drive should monitor this parameter and only engage the drive when consent is given.  If consent ...";
CM_ SG_ 2566759678 EnggmntCnsntTrnsfrCsOtptShaftPTO "Status of the transmission controller뭩 consent to engage the PTO drive connected to the transfer case output shaft.  The controller in charge of the PTO drive should monitor this parameter and only engage the drive when consent is given.  If ...";
CM_ SG_ 2566759678 EnbleSwitchPTOEngAccessoryDrive2 "Status of the PTO engine accessory drive 2 enable switch

00 Enable switch off - PTO operation not desired
01 Enable switch on - PTO operation desired
10 Error
11 Not available";
CM_ SG_ 2566759678 EnbleSwitchPTOEngAccessoryDrive1 "Status of the PTO engine accessory drive 1 enable switch

00 Enable switch off - PTO operation not desired
01 Enable switch on - PTO operation desired
10 Error
11 Not available";
CM_ SG_ 2566759678 EnableSwitchPTOEngFlywheel "Status of the PTO Engine Flywheel enable switch

00 Enable switch off - PTO operation not desired
01 Enable switch on - PTO operation desired 
10 Error
11 Not available";
CM_ SG_ 2566759678 EnableSwitchTransInputShaftPTO1 "Status of the operator뭩 switch or other input which indicates the desire for engaging the first PTO drive mounted on the transmission case.  There may be more than one PTO drive mounted on the transmission case.
00   Enable switch off - PTO ...";
CM_ SG_ 2566759678 EnableSwitchTransInputShaftPTO2 "Status of the operator뭩 switch or other input which indicates the desire for engaging the second PTO drive mounted on the transmission case.   If there is only one PTO drive on the transmission case, use SPN 3452 Enable Switch - Transmission input ...";
CM_ SG_ 2566759678 EnableSwitchTransOutputShaftPTO "Status of the operator뭩 switch or other input which indicates the desire for engaging the PTO drive mounted on the transmission output shaft.
00   Enable switch off - PTO operation not desired
01   Enable switch on - PTO operation desired
10 ...";
CM_ SG_ 2566759678 EnblSwtchTrnsfrCseOutputShaftPTO "Status of the operator뭩 switch or other input which indicates the desire for engaging the PTO drive mounted on the output shaft of the transfer case.
00   Enable switch off - PTO operation not desired
01   Enable switch on - PTO operation desired
 ...";
CM_ BO_ 2432541438 "Fuel Information 3 (Gaseous)
Gaseous fuel information 3";
CM_ SG_ 2432541438 EngFuelValve2OutletAbsPress "Absolute pressure of gas on outlet side of the second fuel system control valve.  See SPN 2980 for the first or only fuel system control valve.";
CM_ SG_ 2432541438 EngFuelTemp2 "Second Temperature measurement of fuel (or gas) of the first fuel type. See SPN 174 for first fuel temperature measurement.";
CM_ SG_ 2432541438 EngGas2MassFlowRate "Gas mass flow rate delivered to an engine through its second fuel control system, using standard convention for determining position.
In a system with two fuel system control valves, left/front is #1 (SPN 1241) and right/rear is #2 (SPN 3467).
In ...";
CM_ SG_ 2432541438 EngFuelValve2IntakeAbsPress "Absolute pressure of gas on intake side of the second fuel system control valve, using standard convention for determining position.
In a system with two fuel system control valves, left/front is #1 (SPN 1390) and right/rear is #2 (SPN 3466).
In a ...";
CM_ BO_ 2566761214 "Engine Fluid Level/Pressure 4
4th PGN which identifies parameters that are either measuring various pressures within the engine or identifying engine fluid levels";
CM_ SG_ 2566761214 EngChargeAirCoolerOutletPress "Measures pressure of air at outlet from charge air cooler";
CM_ SG_ 2566761214 EngAftercoolerCoolantLevel "Ratio of aftercooler coolant system volume of liquid to total cooling system volume.  The engine aftercooler coolant level is for  the low temperature (LT) cooling circuit used for the compressor outlet air or charge aftercooling.
SPN 111 \"Coolant ...";
CM_ SG_ 2566761214 EngIntercoolerCoolantLevel "Ratio of volume of liquid found in an engine charge air cooler cooling system to total engine charge air cooler cooling system volume.";
CM_ SG_ 2566761214 EngCentrifugalOilFilterSpeed "The speed of a rotating (centrifugal) engine oil filter.";
CM_ SG_ 2566761214 EngCoolantPumpDiffPress "The differential pressure measured across the input and output of the engine coolant pump.";
CM_ SG_ 2566761214 EngChargeAirCooler2IntakePress "Pressure of air at intake to 2nd charge air cooler, from multiple first stage turbochargers being cooled and feeding multiple second stage turbochargers.";
CM_ SG_ 2566761214 EngChargeAirCooler1IntakePress "Pressure of air at intake to 1st or only charge air cooler, from multiple first stage turbochargers being cooled and feeding multiple second stage turbochargers.";
CM_ BO_ 2432541694 "Electronic Engine Controller 6
Engine related parameters";
CM_ SG_ 2432541694 EngVriableGeometryTurboActuator1 "Actuator that controls the variable geometry turbocharger geometry.The control command to the actuator, normalized to percent, where 0% nominally represents fully closed (smallest turbocharger geometry) and 100% represents fully open (largest ...";
CM_ SG_ 2432541694 EngTrbCmprssrBypssActtr1TmpSttus "Used to identify the status of the Engine Turbocharger Compresssor Bypass Actuator 1 drive circuitry temperature.  Temperature excursions may affect the torque output.
000 - High Most severe
001 - High Least severe
010 - In Range
011 - Low Least ...";
CM_ SG_ 2432541694 EngTrbCmprssrBypssActtr1PrlmnryF "Used to identify the applicable J1939-73 FMI detected in the Engine Turbocharger Compressor Bypass Actuator 1 by the manufacturers software.  When there is multiple failures, the most severe is transmitted.
A value of 31 is sent to indicate that no ...";
CM_ SG_ 2432541694 EngTrbCmprssorBypassActuator2Cmd "The command to a compressor bypass actuator 2, normalized to percent, where 0% nominally represents fully closed and 100% represents fully open. Typically, the turbocharger compressor bypass actuator is used to keep the engine out of surge by ...";
CM_ SG_ 2432541694 EngTrbCmprssorBypassActuator1Pos "Measures the position of the turbocharger compressor bypass actuator, where 0% represents bypass fully closed and 100% represents bypass fully open.  Typically, the compressor bypass is used to lower the compressor outlet pressure and/or intake ...";
CM_ SG_ 2432541694 EngTrbCmprssorBypassActuator1Cmd "The command to a compressor bypass actuator, normalized to percent, where 0% nominally represents fully closed and 100% represents fully open.  Typically, the turbocharger compressor bypass actuator is used to keep the engine out of surge by ...";
CM_ SG_ 2432541694 EngDsrdTrbCmprssrBypssActtor1Pos "The requested position of the Engine Turbocharger Compressor Bypass actuator by the engine ECU, where 0% represents bypass fully closed and 100% represents bypass fully open.

This is the position that the device is attempting to achieve.";
CM_ BO_ 2566759934 "Door Control 2
Used for door information.";
CM_ SG_ 2566759934 EnableStatusOfDoor10 "Enable status of bus door 10.  Enabled means the bus doors are able to be automatically opened or closed.

00  door disabled
01  door enabled
10  error
11  not available";
CM_ SG_ 2566759934 OpenStatusOfDoor10 "Open status of bus door 10

00  door closed
01  door opened
10  error
11  not available";
CM_ SG_ 2566759934 LockStatusOfDoor10 "Lock status of bus door 10

00  unlocked 
01  locked
10  error
11  not available";
CM_ SG_ 2566759934 EnableStatusOfDoor9 "Enable status of bus door 9.  Enabled means the bus doors are able to be automatically opened or closed.

00  door disabled
01  door enabled
10  error
11  not available";
CM_ SG_ 2566759934 OpenStatusOfDoor9 "Open status of bus door 9

00  door closed
01  door opened
10  error
11  not available";
CM_ SG_ 2566759934 LockStatusOfDoor9 "Lock status of bus door 9

00  unlocked 
01  locked
10  error
11  not available";
CM_ SG_ 2566759934 EnableStatusOfDoor8 "Enable status of bus door 8.  Enabled means the bus doors are able to be automatically opened or closed.

00  door disabled
01  door enabled
10  error
11  not available";
CM_ SG_ 2566759934 OpenStatusOfDoor8 "Open status of bus door 8

00  door closed
01  door opened
10  error
11  not available";
CM_ SG_ 2566759934 LockStatusOfDoor8 "Lock status of bus door 8

00  unlocked 
01  locked
10  error
11  not available";
CM_ SG_ 2566759934 EnableStatusOfDoor7 "Enable status of bus door 7.  Enabled means the bus doors are able to be automatically opened or closed.

00  door disabled
01  door enabled
10  error
11  not available";
CM_ SG_ 2566759934 OpenStatusOfDoor7 "Open status of bus door 7

00  door closed
01  door opened
10  error
11  not available";
CM_ SG_ 2566759934 LockStatusOfDoor7 "Lock status of bus door 7

00  unlocked 
01  locked
10  error
11  not available";
CM_ SG_ 2566759934 EnableStatusOfDoor6 "Enable status of bus door 6.  Enabled means the bus doors are able to be automatically opened or closed.

00  door disabled
01  door enabled
10  error
11  not available";
CM_ SG_ 2566759934 OpenStatusOfDoor6 "Open status of bus door 6

00  door closed
01  door opened
10  error
11  not available";
CM_ SG_ 2566759934 LockStatusOfDoor6 "Lock status of bus door 6

00  unlocked 
01  locked
10  error
11  not available";
CM_ SG_ 2566759934 EnableStatusOfDoor5 "Enable status of bus door 5.  Enabled means the bus doors are able to be automatically opened or closed.

00  door disabled
01  door enabled
10  error
11  not available";
CM_ SG_ 2566759934 OpenStatusOfDoor5 "Open status of bus door 5

00  door closed
01  door opened
10  error
11  not available";
CM_ SG_ 2566759934 LockStatusOfDoor5 "Lock status of bus door 5

00  unlocked 
01  locked
10  error
11  not available";
CM_ SG_ 2566759934 EnableStatusOfDoor4 "Enable status of bus door 4.  Enabled means the bus doors are able to be automatically opened or closed.

00  door disabled
01  door enabled
10  error
11  not available";
CM_ SG_ 2566759934 OpenStatusOfDoor4 "Open status of bus door 4

00  door closed
01  door opened
10  error
11  not available";
CM_ SG_ 2566759934 LockStatusOfDoor4 "Lock status of bus door 4

00  unlocked 
01  locked
10  error
11  not available";
CM_ SG_ 2566759934 EnableStatusOfDoor3 "Enable status of bus door 3.  Enabled means the bus doors are able to be automatically opened or closed.

00  door disabled
01  door enabled
10  error
11  not available";
CM_ SG_ 2566759934 OpenStatusOfDoor3 "Open status of bus door 3

00  door closed
01  door opened
10  error
11  not available";
CM_ SG_ 2566759934 LockStatusOfDoor3 "Lock status of bus door 3

00  unlocked 
01  locked
10  error
11  not available";
CM_ SG_ 2566759934 EnableStatusOfDoor2 "Enable status of bus door 2.  Enabled means the bus doors are able to be automatically opened or closed.

00  door disabled
01  door enabled
10  error
11  not available";
CM_ SG_ 2566759934 OpenStatusOfDoor2 "Open status of bus door 2

00  door closed
01  door opened
10  error
11  not available";
CM_ SG_ 2566759934 LockStatusOfDoor2 "Lock status of bus door 2

00  unlocked 
01  locked
10  error
11  not available";
CM_ SG_ 2566759934 EnableStatusOfDoor1 "Enable status of bus door 1.  Enabled means the bus doors are able to be automatically opened or closed.

00  door disabled
01  door enabled
10  error
11  not available";
CM_ SG_ 2566759934 OpenStatusOfDoor1 "Open status of bus door 1

00  door closed
01  door opened
10  error
11  not available";
CM_ SG_ 2566759934 LockStatusOfDoor1 "Lock status of bus door 1

00  unlocked 
01  locked
10  error
11  not available";
CM_ BO_ 2566757374 "Aftertreatment 1 Diesel Exhaust Fluid Information 1
Sensor Information which measures temperature, concentration, and conductivity of the diesel exhaust fluid of the aftertreatment 1 system.";
CM_ SG_ 2566757374 DieselExhaustFluidSpeedOfSound "The speed of sound in the fluid that is in the diesel exhaust fluid tank.";
CM_ SG_ 2566757374 Property "This parameter indicates the property of the fluid compound in the tank.  A value of 0011 indicates uncontaminated Diesel Exhaust Fluid.
0000 - Urea concentration too high
0001 - Urea concentration too low
0010 - Fluid is diesel
0011 - Diesel ...";
CM_ SG_ 2566757374 PropertiesPreliminaryFMI "Used to identify the applicable J1939-73 FMI that applies to the most significant failure of the diesel exhaust fluid properties sensor.  This may be used for indicating failures of the diesel exhaust fluid concentration, diesel exhaust fluid ...";
CM_ SG_ 2566757374 Temp2PreliminaryFMI "Used to identify the applicable J1939-73 FMI that applies to the most significant failure of the diesel exhaust fluid temperature sensor.  In the case of multiple failures the most severe is communicated.
A value of 31 is sent to indicate that no ...";
CM_ SG_ 2566757374 Conductivity "A measure of the conductivity of the diesel exhaust fluid at the sensor.  The conductivity is an indication of the diesel exhaust fluid's chemical make up.";
CM_ SG_ 2566757374 Concentration "A measure of the concentration of urea in water.  Zero percent means that the tank contains no urea.  A 32.5% value indicates that the diesel exhaust fluid is of the proper concentration.  The 32.5% value indicates that the concentration is highest ...";
CM_ SG_ 2566757374 Temp2 "Temperature of the diesel exhaust fluid at the device measuring diesel exhaust fluid quality";
CM_ BO_ 2364546302 "Requested Generator Average Basic AC Quantities
Contains Requested Generator Average Basic AC Quantities";
CM_ SG_ 2364546302 RqdGnrtrAvrgLneLineACRMSVoltage "The requested average AC RMS voltage to be delivered by the generator.";
CM_ BO_ 2431654654 "Engine Throttle / Fuel Actuator Control Command
Used to control networked electronic throttle control actuator and/or fuel control actuator valves.  Otherwise, this PGN can be used to monitor commanded % positioning to electronic throttle control ...";
CM_ SG_ 2431654654 EngFuelActuator2CtrlCmd "The control command to fuel actuator 2, normalized to percent, where 0% represents fully closed and 100% represents fully open. Typically, this fuel actuator is used to regulate low pressure natural gas flow rate, mixing into the air flow, which ...";
CM_ SG_ 2431654654 EngFuelActuator1CtrlCmd "The control command to fuel actuator 1, normalized to percent, where 0% represents fully closed and 100% represents fully open. In applications where the fuel actuator controls to differential pressure, 0% represents minimum differential pressure ...";
CM_ SG_ 2431654654 EngThrottleActuator2CtrlCmd "The control command to throttle actuator 2, normalized to percent, where 0% represents fully closed and 100% represents fully open.  Typically, this throttle actuator is used to regulate air or air / fuel mix to the engine. Using the standard ...";
CM_ SG_ 2431654654 EngThrottleActuator1CtrlCmd "The control command to throttle actuator 1, normalized to percent, where 0% represents fully closed and 100% represents fully open.  Typically, this throttle actuator is used to regulate air or air / fuel mix to the engine. Using the standard ...";
CM_ BO_ 2364545534 "Engine Knock Level #3
Used to send the SPNs containing information relating to the level of knock for 8 cylinders. When knock is detected on any one cylinder, this PGN needs to be sent every crank revolution (engine speed dependant). If there is no ...";
CM_ SG_ 2364545534 EngCyl24KnockLevel "Used to indicate the level of knock for engine cylinder 24. The level of knock is reported using a relative scale where 0% is least level of knock, and increasing levels indicate more knock until 100% indicates the most severe level of knock allowed ...";
CM_ SG_ 2364545534 EngCyl23KnockLevel "Used to indicate the level of knock for engine cylinder 23. The level of knock is reported using a relative scale where 0% is least level of knock, and increasing levels indicate more knock until 100% indicates the most severe level of knock allowed ...";
CM_ SG_ 2364545534 EngCyl22KnockLevel "Used to indicate the level of knock for engine cylinder 22. The level of knock is reported using a relative scale where 0% is least level of knock, and increasing levels indicate more knock until 100% indicates the most severe level of knock allowed ...";
CM_ SG_ 2364545534 EngCyl21KnockLevel "Used to indicate the level of knock for engine cylinder 21. The level of knock is reported using a relative scale where 0% is least level of knock, and increasing levels indicate more knock until 100% indicates the most severe level of knock allowed ...";
CM_ SG_ 2364545534 EngCyl20KnockLevel "Used to indicate the level of knock for engine cylinder 20. The level of knock is reported using a relative scale where 0% is least level of knock, and increasing levels indicate more knock until 100% indicates the most severe level of knock allowed ...";
CM_ SG_ 2364545534 EngCyl19KnockLevel "Used to indicate the level of knock for engine cylinder 19. The level of knock is reported using a relative scale where 0% is least level of knock, and increasing levels indicate more knock until 100% indicates the most severe level of knock allowed ...";
CM_ SG_ 2364545534 EngCyl18KnockLevel "Used to indicate the level of knock for engine cylinder 18. The level of knock is reported using a relative scale where 0% is least level of knock, and increasing levels indicate more knock until 100% indicates the most severe level of knock allowed ...";
CM_ SG_ 2364545534 EngCyl17KnockLevel "Used to indicate the level of knock for engine cylinder 17. The level of knock is reported using a relative scale where 0% is least level of knock, and increasing levels indicate more knock until 100% indicates the most severe level of knock allowed ...";
CM_ BO_ 2364545278 "Engine Knock Level #2
Used to send the SPNs containing information relating to the level of knock for 8 cylinders. When knock is detected on any one cylinder, this PGN needs to be sent every crank revolution (engine speed dependant). If there is no ...";
CM_ SG_ 2364545278 EngCyl16KnockLevel "Used to indicate the level of knock for engine cylinder 16. The level of knock is reported using a relative scale where 0% is least level of knock, and increasing levels indicate more knock until 100% indicates the most severe level of knock allowed ...";
CM_ SG_ 2364545278 EngCyl15KnockLevel "Used to indicate the level of knock for engine cylinder 15. The level of knock is reported using a relative scale where 0% is least level of knock, and increasing levels indicate more knock until 100% indicates the most severe level of knock allowed ...";
CM_ SG_ 2364545278 EngCyl14KnockLevel "Used to indicate the level of knock for engine cylinder 14. The level of knock is reported using a relative scale where 0% is least level of knock, and increasing levels indicate more knock until 100% indicates the most severe level of knock allowed ...";
CM_ SG_ 2364545278 EngCyl13KnockLevel "Used to indicate the level of knock for engine cylinder 13. The level of knock is reported using a relative scale where 0% is least level of knock, and increasing levels indicate more knock until 100% indicates the most severe level of knock allowed ...";
CM_ SG_ 2364545278 EngCyl12KnockLevel "Used to indicate the level of knock for engine cylinder 12. The level of knock is reported using a relative scale where 0% is least level of knock, and increasing levels indicate more knock until 100% indicates the most severe level of knock allowed ...";
CM_ SG_ 2364545278 EngCyl11KnockLevel "Used to indicate the level of knock for engine cylinder 11. The level of knock is reported using a relative scale where 0% is least level of knock, and increasing levels indicate more knock until 100% indicates the most severe level of knock allowed ...";
CM_ SG_ 2364545278 EngCyl10KnockLevel "Used to indicate the level of knock for engine cylinder 10. The level of knock is reported using a relative scale where 0% is least level of knock, and increasing levels indicate more knock until 100% indicates the most severe level of knock allowed ...";
CM_ SG_ 2364545278 EngCyl9KnockLevel "Used to indicate the level of knock for engine cylinder 9. The level of knock is reported using a relative scale where 0% is least level of knock, and increasing levels indicate more knock until 100% indicates the most severe level of knock allowed ...";
CM_ BO_ 2364545022 "Engine Knock Level #1
Used to send the SPNs containing information relating to the level of knock for 8 cylinders. When knock is detected on any one cylinder, this PGN needs to be sent every crank revolution (engine speed dependant). If there is no ...";
CM_ SG_ 2364545022 EngCyl8KnockLevel "Used to indicate the level of knock for engine cylinder 8. The level of knock is reported using a relative scale where 0% is least level of knock, and increasing levels indicate more knock until 100% indicates the most severe level of knock allowed ...";
CM_ SG_ 2364545022 EngCyl7KnockLevel "Used to indicate the level of knock for engine cylinder 7. The level of knock is reported using a relative scale where 0% is least level of knock, and increasing levels indicate more knock until 100% indicates the most severe level of knock allowed ...";
CM_ SG_ 2364545022 EngCyl6KnockLevel "Used to indicate the level of knock for engine cylinder 6. The level of knock is reported using a relative scale where 0% is least level of knock, and increasing levels indicate more knock until 100% indicates the most severe level of knock allowed ...";
CM_ SG_ 2364545022 EngCyl5KnockLevel "Used to indicate the level of knock for engine cylinder 5. The level of knock is reported using a relative scale where 0% is least level of knock, and increasing levels indicate more knock until 100% indicates the most severe level of knock allowed ...";
CM_ SG_ 2364545022 EngCyl4KnockLevel "Used to indicate the level of knock for engine cylinder 4. The level of knock is reported using a relative scale where 0% is least level of knock, and increasing levels indicate more knock until 100% indicates the most severe level of knock allowed ...";
CM_ SG_ 2364545022 EngCyl3KnockLevel "Used to indicate the level of knock for engine cylinder 3. The level of knock is reported using a relative scale where 0% is least level of knock, and increasing levels indicate more knock until 100% indicates the most severe level of knock allowed ...";
CM_ SG_ 2364545022 EngCyl2KnockLevel "Used to indicate the level of knock for engine cylinder 2. The level of knock is reported using a relative scale where 0% is least level of knock, and increasing levels indicate more knock until 100% indicates the most severe level of knock allowed ...";
CM_ SG_ 2364545022 EngCyl1KnockLevel "Used to indicate the level of knock for engine cylinder 1. The level of knock is reported using a relative scale where 0% is least level of knock, and increasing levels indicate more knock until 100% indicates the most severe level of knock allowed ...";
CM_ BO_ 2364544766 "Cylinder Combustion Status
Used to send the SPNs containing information relating to the state of combustion for 24 cylinders. When there is no combustion detected on any one cylinder, this PGN needs to be sent every crank revolution (engine speed ...";
CM_ SG_ 2364544766 EngCyl24CombustionStatus "This parameter is used to indicate state of combustion in engine cylinder #24

00        No combustion
01        Combustion exists
10        Error
11        Not available";
CM_ SG_ 2364544766 EngCyl23CombustionStatus "This parameter is used to indicate state of combustion in engine cylinder #23

00        No combustion
01        Combustion exists
10        Error
11        Not available";
CM_ SG_ 2364544766 EngCyl22CombustionStatus "This parameter is used to indicate state of combustion in engine cylinder #22

00        No combustion
01        Combustion exists
10        Error
11        Not available";
CM_ SG_ 2364544766 EngCyl21CombustionStatus "This parameter is used to indicate state of combustion in engine cylinder #21

00        No combustion
01        Combustion exists
10        Error
11        Not available";
CM_ SG_ 2364544766 EngCyl20CombustionStatus "This parameter is used to indicate state of combustion in engine cylinder #20

00        No combustion
01        Combustion exists
10        Error
11        Not available";
CM_ SG_ 2364544766 EngCyl19CombustionStatus "This parameter is used to indicate state of combustion in engine cylinder #19

00        No combustion
01        Combustion exists
10        Error
11        Not available";
CM_ SG_ 2364544766 EngCyl18CombustionStatus "This parameter is used to indicate state of combustion in engine cylinder #18

00        No combustion
01        Combustion exists
10        Error
11        Not available";
CM_ SG_ 2364544766 EngCyl17CombustionStatus "This parameter is used to indicate state of combustion in engine cylinder #17

00        No combustion
01        Combustion exists
10        Error
11        Not available";
CM_ SG_ 2364544766 EngCyl16CombustionStatus "This parameter is used to indicate state of combustion in engine cylinder #16

00        No combustion
01        Combustion exists
10        Error
11        Not available";
CM_ SG_ 2364544766 EngCyl15CombustionStatus "This parameter is used to indicate state of combustion in engine cylinder #15

00        No combustion
01        Combustion exists
10        Error
11        Not available";
CM_ SG_ 2364544766 EngCyl14CombustionStatus "This parameter is used to indicate state of combustion in engine cylinder #14
00        No combustion
01        Combustion exists
10        Error
11        Not available";
CM_ SG_ 2364544766 EngCyl13CombustionStatus "This parameter is used to indicate state of combustion in engine cylinder #13

00        No combustion
01        Combustion exists
10        Error
11        Not available";
CM_ SG_ 2364544766 EngCyl12CombustionStatus "This parameter is used to indicate state of combustion in engine cylinder #12

00        No combustion
01        Combustion exists
10        Error
11        Not available";
CM_ SG_ 2364544766 EngCyl11CombustionStatus "This parameter is used to indicate state of combustion in engine cylinder #11

00        No combustion
01        Combustion exists
10        Error
11        Not available";
CM_ SG_ 2364544766 EngCyl10CombustionStatus "This parameter is used to indicate state of combustion in engine cylinder #10

00        No combustion
01        Combustion exists
10        Error
11        Not available";
CM_ SG_ 2364544766 EngCyl9CombustionStatus "This parameter is used to indicate state of combustion in engine cylinder #9

00        No combustion
01        Combustion exists
10        Error
11        Not available";
CM_ SG_ 2364544766 EngCyl8CombustionStatus "This parameter is used to indicate state of combustion in engine cylinder #8

00        No combustion
01        Combustion exists
10        Error
11        Not available";
CM_ SG_ 2364544766 EngCyl7CombustionStatus "This parameter is used to indicate state of combustion in engine cylinder #7

00        No combustion
01        Combustion exists
10        Error
11        Not available";
CM_ SG_ 2364544766 EngCyl6CombustionStatus "This parameter is used to indicate state of combustion in engine cylinder #6

00        No combustion
01        Combustion exists
10        Error
11        Not available";
CM_ SG_ 2364544766 EngCyl5CombustionStatus "This parameter is used to indicate state of combustion in engine cylinder #5

00        No combustion
01        Combustion exists
10        Error
11        Not available";
CM_ SG_ 2364544766 EngCyl4CombustionStatus "This parameter is used to indicate state of combustion in engine cylinder #4

00        No combustion
01        Combustion exists
10        Error
11        Not available";
CM_ SG_ 2364544766 EngCyl3CombustionStatus "This parameter is used to indicate state of combustion in engine cylinder #3

00        No combustion
01        Combustion exists
10        Error
11        Not available";
CM_ SG_ 2364544766 EngCyl2CombustionStatus "This parameter is used to indicate state of combustion in engine cylinder #2

00        No combustion
01        Combustion exists
10        Error
11        Not available";
CM_ SG_ 2364544766 EngCyl1CombustionStatus "This parameter is used to indicate state of combustion in engine cylinder #1

00        No combustion
01        Combustion exists
10        Error
11        Not available";
CM_ BO_ 2364544510 "Requested Generator Total AC Reactive Power
Contains requested reactive and power factor control values";
CM_ SG_ 2364544510 RqGenOverallPowerFactorLagging "The requested lead/lag status for the generator average AC power factor

00 - Leading
01 - Lagging
10 - Reserved
11 - Not available or Not installed";
CM_ SG_ 2364544510 RqGeneratorOverallPowerFactor "The requested average power factor of the generator.";
CM_ SG_ 2364544510 RqGeneratorTotalACReactivePower "The total reactive power requested to be delivered by the generator";
CM_ BO_ 2364544254 "Blade Information
A measurement of the machine's relative blade height and a rotational angle measurement of the machine blade yaw angle around the machine z-axis.  The vehicle dynamics measurements in this message shall be according to a Z-Down ...";
CM_ SG_ 2364544254 BladeRotationAngleFigureOfMerit "Figure of merit for blade rotation measurement.
Bits
00  Blade Rotation Angle fully functional.  Data is within sensor specification.
01  Blade Rotation Angle  degraded.  Data is suspect due to environmental conditions.
10  Blade Rotation Angle ...";
CM_ SG_ 2364544254 RelativeBladeHeightFigureOfMerit "Figure of merit for blade height measurement.
Bits
00  Relative Blade Height fully functional.  Data is within sensor specification.
01  Relative Blade Height degraded.  Data is suspect due to environmental conditions.
10  Relative Blade Height ...";
CM_ SG_ 2364544254 RltvBldHghtAndBldRttnAnglMsrmntL "The estimated measurement latency of the measurement.
NOTE: This is only the sensor latency and does not include any additional latencies that might exist because of the CAN Bus or overall system implementation.
For example, if the technique used ...";
CM_ SG_ 2364544254 BladeRotationAngle "The blade rotation angle measurement around the yaw (z-axis).  The Blade Rotation Angle is defined to be the angle from the null position on the machine.  The null position is orthogonal from the z-axis along the x-axis.  A positive blade angle ...";
CM_ SG_ 2364544254 RelativeBladeHeight "The measured vertical distance from a fixed location on the machine blade to a ground-based reference (i.e. relative height).  Examples of a ground based reference include a curb, a stringline or the ground itself.  The measurement may be positive ...";
CM_ BO_ 2550333182 "Electronic Brake System #1/1
Message to transmit data of the towing vehicle to the towed vehicle. See ISO 11992-2.";
CM_ SG_ 2550333182 RetarderDemandValue "The demanded value of the retarder on the towed vehicle(s) as a percentage of the absolute peak torque of retarder.";
CM_ SG_ 2550333182 ParkBrakeDemandValue "The requested brake pressure value of the parking brake as a percentage of maximum.";
CM_ SG_ 2550333182 ServiceBrakeDemandValue "The requested brake pressure value of the service brake demanded by the driver.";
CM_ SG_ 2550333182 VehicleType "Information to identify a dolly axle within the road train.";
CM_ SG_ 2550333182 BrakeLightSwitch "Signal which indicates that the brake pedal is being pressed.";
CM_ SG_ 2550333182 ASREngineControlActive "Signal which indicates that ASR engine control is active/passive.";
CM_ SG_ 2550333182 ASRBreakControlActive "Signal which indicates that ASR brake control is active/passive.";
CM_ SG_ 2550333182 VehicleRetarderCtrlActive "This signal indicates the active/passive state in all cases when the installed retarder is applied by the driver뭩 demand or by other systems (brakes).";
CM_ SG_ 2550333182 VehicleABSActive "Signal indicating the ABS is active/passive.";
CM_ BO_ 2566834686 "Electronic Brake System #1/2
Message to transmit data of the towing vehicle to the towed vehicle. See ISO 11992-2.";
CM_ SG_ 2566834686 RoadCurvature "Estimated value of the current road curvature for use by the adaptive cruise control system.  Positive values are used for left curves.  Curvature is the inverse of the radius and is zero for straight roads.";
CM_ SG_ 2566834686 PneumaticControlLine "Signal which indicates that the towing vehicle has a pneumatic control line for the towed vehicle service braking system";
CM_ SG_ 2566834686 ABSOffroadRequest "Request to activate the ABS off-road function. The switch signal is independent of an actual ABS control situation.";
CM_ SG_ 2566834686 TwoElCircuitsBrakeDemand "Signal which indicates that the service brake demand value sent by the towing vehicle can be generated by one or two independent electrical braking circuit(s).";
CM_ SG_ 2566834686 VehicleRetarderCtrlActive "This signal indicates the active/passive state in all cases when the installed retarder is applied by the driver뭩 demand or by other systems (brakes).";
CM_ BO_ 2550398718 "Electronic Brake System #2/1
Message to transmit data of the towed vehicle to the towing vehicle. See ISO 11992-2.";
CM_ SG_ 2550398718 WheelSpeedDiffMainAxle "Difference between the wheel speed at the right side and and the left side of the main axle.";
CM_ SG_ 2550398718 ActualRetarderPercTorque "Actual torque of the retarder as negative percentage of maximum.";
CM_ SG_ 2550398718 Wheel_BasedVehicleSpeed "Actual speed of the vehicle (positive value for forward and backward speed) calculated as the average of the wheel speeds of one axle influenced by slip and filtered by a frequency range of 5 Hz to 20 Hz.";
CM_ SG_ 2550398718 SupplyLineBrakingRequest "Signal indicating the trailer is requesting to be braked by the commercial vehicle by means of bleeding the pneumatic supply line.";
CM_ SG_ 2550398718 VDCActive "Signal which indicates that Vehicle Dynamic Control (VDC) is active/passive.";
CM_ SG_ 2550398718 AutomTowedVehBreakActive "Signal indicating the automatic towed vehicle braking is active/passive.";
CM_ SG_ 2550398718 VehicleServiceBrakeActive "Signal indicating the service brake of the towed vehicle is active/passive, by observing the brake pressure.";
CM_ SG_ 2550398718 VehicleRetarderCtrlActive "This signal indicates the active/passive state in all cases when the installed retarder is applied by the driver뭩 demand or by other systems (brakes).";
CM_ SG_ 2550398718 VehicleABSActive "Signal indicating the ABS is active/passive.";
CM_ BO_ 2566833406 "Electronic Brake System #2/2
Message to transmit data of the towed vehicle to the towing vehicle. See ISO 11992-2.";
CM_ SG_ 2566833406 ReferenceRetarderTorque "This parameter is the 100% reference value for all defined indicated retarder torque parameters.  It is only defined once and doesn't change if a different retarder torque map becomes valid.";
CM_ SG_ 2566833406 AxleLoadSum "Sum of the static vertical loads of the vehicle axles.";
CM_ SG_ 2566833406 SupplyLineBrakingRequest "Signal indicating the trailer is requesting to be braked by the commercial vehicle by means of bleeding the pneumatic supply line.";
CM_ SG_ 2566833406 LoadingRampApproachAssist "The parameter indicates whether the loading ramp approach assistance is activated.";
CM_ SG_ 2566833406 SpringBrakeEngaged "Signal indicating the vehicle spring brake is engaged.";
CM_ SG_ 2566833406 ElectrLoadPropFunc "Signal indicating the vehicle is equipped with an electrical load proportional function.";
CM_ SG_ 2566833406 SpringBrakeInstalled "Signal indicating the vehicle has one or more axle(s) fitted with spring brakes.";
CM_ SG_ 2566833406 VehicleType "Information to identify a dolly axle within the road train.";
CM_ SG_ 2566833406 ElecSupplyOfNonBrakingSys "Signal which indicates the status of the supply of non-braking systems.";
CM_ SG_ 2566833406 AmberWarningSignalReq "Request from the towed vehicle to the commercial vehicle to activate the amber warning signal on the commercial vehicle.";
CM_ SG_ 2566833406 RedWarningSignalRequest "Request from the towed vehicle to the commercial vehicle to activate the red warning signal on the commercial vehicle, which indicates certain specified failures within the braking equipment of the towed vehicles.";
CM_ SG_ 2566833406 VehicleElectrSupplySuff "Signal indicating the actual supply voltage is sufficient/insufficient for proper brake function (including over voltage).";
CM_ SG_ 2566833406 AutomTowedVehBreakActive "Signal indicating the automatic towed vehicle braking is active/passive.";
CM_ SG_ 2566833406 VehicleServiceBrakeActive "Signal indicating the service brake of the towed vehicle is active/passive, by observing the brake pressure.";
CM_ SG_ 2566833406 VehicleRetarderCtrlActive "This signal indicates the active/passive state in all cases when the installed retarder is applied by the driver뭩 demand or by other systems (brakes).";
CM_ SG_ 2566833406 VehicleABSActive "Signal indicating the ABS is active/passive.";
CM_ BO_ 2566833918 "Electronic Brake System #2/3
Message to transmit data of the towed vehicle to the towing vehicle. See ISO 11992-2.";
CM_ SG_ 2566833918 PneumaticSupplyPressure "Actual supply pressure of the reservoir of the braking system.";
CM_ SG_ 2566833918 BrakeTemperature "Actual brake temperature.";
CM_ SG_ 2566833918 BrakeLining "Actual relative value of brake lining of a specific brake.";
CM_ SG_ 2566833918 TyrePressure "Actual tyre pressure without corrections.";
CM_ SG_ 2566833918 TyreWheelIdentTemp2 "Second part of identification number of the tyre or wheel (the number of axles).";
CM_ SG_ 2566833918 TyreWheelIdentTemp1 "First part of identification number of the tyre or wheel (position on each axle).";
CM_ SG_ 2566833918 TyreWheelIdentPressure2 "Second part of identification number of the tyre or wheel (the number of axles).";
CM_ SG_ 2566833918 TyreWheelIdentPressure1 "First part of identification number of the tyre or wheel (position on each axle).";
CM_ SG_ 2566833918 TyreWheelIdentLining2 "Second part of identification number of the tyre or wheel (the number of axles).";
CM_ SG_ 2566833918 TyreWheelIdentLining1 "First part of identification number of the tyre or wheel (position on each axle).";
CM_ SG_ 2566833918 VehiclePneumSupplySuff "Signal indicating the actual supply pressure of the reservoir of the braking system is insufficient or sufficient.";
CM_ SG_ 2566833918 BrakeTemperatureStatus "Signal which indicates that the brake temperature is higher than a specific level.";
CM_ SG_ 2566833918 BrakeLiningSufficient "Signal which indicates that the brake lining is sufficient/insufficient.";
CM_ SG_ 2566833918 TyrePressureSufficient "Signal which indicates that the tyre pressure is insufficient";
CM_ BO_ 2565013246 "General Purpose Message #1/1
Message to transmit data of the towing vehicle to the towed vehicle. See ISO 11992-3.";
CM_ SG_ 2565013246 ODDRequest "Command signal to switch on or off the obstacle detection device (ODD).";
CM_ SG_ 2565013246 AntiTheftDeviceReq "Command signal to activate the anti-theft device.";
CM_ SG_ 2565013246 VehicleType "Information to identify a dolly axle within the road train.";
CM_ BO_ 2566807038 "General Purpose Message #1/2
Message to transmit data of the towing vehicle to the towed vehicle. See ISO 11992-3.";
CM_ SG_ 2566807038 MaxVehicleSpeedLimit "Maximum vehicle velocity allowed.   See SPN 6808 for an alternate resolution.";
CM_ SG_ 2566807038 EngineSpeedUpperLimit "The engine speed which cannot be exceeded.";
CM_ SG_ 2566807038 EngineSpeedLowerLimit "The minimum engine speed which the engine is allowed to reach.";
CM_ BO_ 2566807550 "General Purpose Message #1/3
Message to transmit data of the towing vehicle to the towed vehicle. See ISO 11992-3.";
CM_ SG_ 2566807550 EngineTorqueMode "State signal which indicates which engine torque mode is currently generating, limiting, or controlling the torque";
CM_ SG_ 2566807550 PercentLoadAtCurrentSpeed "The ratio of actual engine percent torque to maximum indicated torque available at the current engine speed, clipped to zero torque during engine braking.";
CM_ SG_ 2566807550 EngineSpeed "Actual engine speed which is calculated over a minimum crankshaft angle of 720 degrees divided by
the number of cylinders.";
CM_ SG_ 2566807550 ActualEngine_PercTorque "The calculated output torque of the engine.";
CM_ SG_ 2566807550 DriversDemandEngine_PercTorque "The torque output of the engine requested by the driver.";
CM_ SG_ 2566807550 EngineRunning "Signal which indicates whether the engine is running.";
CM_ SG_ 2566807550 EngineControlAllowed "Switch signal which indicates that engine control is allowed.";
CM_ BO_ 2566808062 "General Purpose Message #1/4
Message to transmit data of the towing vehicle to the towed vehicle. See ISO 11992-3.";
CM_ SG_ 2566808062 ClutchIndptdPTOFeedback "Signal which indicates the current state of the clutch independent power take off.";
CM_ SG_ 2566808062 AccelPedalPosition "The ratio of actual accelerator pedal position to maximum pedal position.";
CM_ SG_ 2566808062 AccelPedalLowIdleSwitch "Switch signal which indicates whether the accelerator pedal low idle switch is opened or closed.";
CM_ SG_ 2566808062 StarterActive "Signal which indicates whether the starter is in use.";
CM_ SG_ 2566808062 TorqueConvOilTemp "Temperature of the torque converter lubricant.";
CM_ SG_ 2566808062 TorqueConvtOilTempWarning "Signal which indicates that the torque converter oil temperature has reached its warning level.";
CM_ SG_ 2566808062 PTOControlAllowed "Switch signal which indicates that PTO control is allowed.";
CM_ SG_ 2566808062 SecEngineMtdPTOFeedback "Signal which indicates the current state of the second engine mounted power take off.";
CM_ SG_ 2566808062 FirstEngineMtdPTOFeedback "Signal which indicates the current state of the first engine mounted power take off.";
CM_ SG_ 2566808062 SecClutchDptdPTOFeedback "Signal which indicates the current state of the second clutch dependent power take off.";
CM_ SG_ 2566808062 FirstClutchDpdtPTOFeedback "Signal which indicates the current state of the first clutch dependent power take off.";
CM_ SG_ 2566808062 CurrentGear "The gear currently engaged in the transmission or the last gear engaged while the transmission is in process of shifting to the new or selected gear.";
CM_ SG_ 2566808062 PercentClutchSlip "Parameter which represents the ratio of input shaft speed to current engine speed (in percent).

Percent Clutch Slip = ((Engine rpm - Input shaft rpm)/(Engine rpm)) x 100";
CM_ BO_ 2566808574 "General Purpose Message #1/5
Message to transmit data of the towing vehicle to the towed vehicle. See ISO 11992-3.";
CM_ SG_ 2566808574 ReferenceEngineTorque "The 100 % reference value for all defined indicated engine torque parameters.";
CM_ SG_ 2566808574 FuelLevelWarning "This signal indicates the decrease of the fuel level to a certain minimum.";
CM_ SG_ 2566808574 EngineOilPressureWarning "Signal which indicates that the engine oil pressure has reached its warning level.";
CM_ SG_ 2566808574 EngineCoolantTempWarning "Signal which indicates that the engine coolant temperature has reached its warning level.";
CM_ SG_ 2566808574 EngineOilPressure "Gauge pressure of the oil in the engine lubrication system as provided by the oil pump.";
CM_ SG_ 2566808574 EngCoolantTemp "Temperature of liquid found in engine cooling system.";
CM_ SG_ 2566808574 EngineOilTemperature "Temperature of the engine lubricant.";
CM_ BO_ 2566809086 "General Purpose Message #1/6
Message to transmit data of the towing vehicle to the towed vehicle. See ISO 11992-3.";
CM_ SG_ 2566809086 AmbientAirTemperature "Temperature of air surrounding vehicle.";
CM_ BO_ 2564947710 "General Purpose Message #2/1
Message to transmit data of the towed vehicle to the towing vehicle. See ISO 11992-3.";
CM_ SG_ 2564947710 VehicleType "Information to identify a dolly axle within the road train.";
CM_ BO_ 2566834430 "General Purpose Message #2/2
Message to transmit data of the towed vehicle to the towing vehicle. See ISO 11992-3.";
CM_ SG_ 2566834430 BodyPressure "The actual pressure in a body on the towed vehicle.";
CM_ SG_ 2566834430 BodyFluidLevel "The actual fluid level in a body on the towed vehicle.";
CM_ SG_ 2566834430 ThermalBodyTemperature "The actual temperature in a thermal body on the towed vehicle.";
CM_ SG_ 2566834430 RearObstacleDistance "The actual distance between the back of the towed vehicle and any obstacle.";
CM_ SG_ 2566834430 AntiTheftDeviceStatus "Signal which indicates that the anti-theft device is switched on or off.";
CM_ SG_ 2566834430 ODDStatus "Signal which indicates that an obstacle detection device (ODD) is active/inactive.";
CM_ BO_ 2566807806 "General Purpose Message #2/3
Message to transmit data of the towed vehicle to the towing vehicle. See ISO 11992-3.";
CM_ SG_ 2566807806 ReqEngineSpeedUpperLim "The requested engine speed which is not to be exceeded.";
CM_ SG_ 2566807806 ReqEngineSpeedLowerLim "The requested minimum engine speed which the engine is to allow.";
CM_ SG_ 2566807806 ReqEngineTorqueLimit "The requested engine torque that the engine is not allowed to exceed, indicated as a ratio of the reference engine torque.";
CM_ SG_ 2566807806 ReqEngineSpeedLimit "The requested vehicle speed which the vehicle is not allowed to exceed.";
CM_ SG_ 2566807806 ReqEngineSpeed "This is the engine speed which the engine is expected to operate at.";
CM_ BO_ 2566808318 "General Purpose Message #2/4
Message to transmit data of the towed vehicle to the towing vehicle. See ISO 11992-3.";
CM_ SG_ 2566808318 SecEngineMtdPTOSwitch "Signal which indicates the state of the second engine mounted power take off switch.";
CM_ SG_ 2566808318 SecClutchDpdtPTOSwitch "Signal which indicates the state of the second clutch dependent power take off switch.";
CM_ SG_ 2566808318 FirstClutchDpdtPTOSwitch "Signal which indicates the state of the first clutch dependent power take off switch.";
CM_ SG_ 2566808318 OperatingPanelActive "Signal which indicates that the operating panel is active.";
CM_ SG_ 2566808318 RefusePackerStepSwitch "Signal which indicates the state of the refuse packer step switch.";
CM_ SG_ 2566808318 EngineStopSwitch "Signal which indicates the state of the engine stop switch.";
CM_ SG_ 2566808318 EngineStartSwitch "Signal which indicates the state of the engine start switch.";
CM_ SG_ 2566808318 StarterLockoutSwitch "Signal which indicates the state of the starter lockout switch.";
CM_ SG_ 2566808318 RqstedPercentClutchSlip "Command signal to influence the clutch.";
CM_ SG_ 2566808318 FirstEngineMtdPTOSwitch "Signal which indicates the state of the first engine mounted power take off switch.";
CM_ SG_ 2566808318 ClutchIndpdtPTOSwitch "Signal which indicates the state of the clutch independent power take off switch.";
CM_ BO_ 2566808830 "General Purpose Message #2/5
Message to transmit data of the towed vehicle to the towing vehicle. See ISO 11992-3.";
CM_ SG_ 2566808830 TrailerLeftSideMarkerLight "This signal indicates the state of the trailer left-hand side marker light(s).";
CM_ SG_ 2566808830 TrailerLeftReversingLight "This signal indicates the state of the trailer left-hand reversing light(s).";
CM_ SG_ 2566808830 TrailerLeftRearWidIndLight "This signal indicates the state of the trailer left-hand rear width indicator light(s).";
CM_ SG_ 2566808830 TrailerLeftRearRegPltLight "This signal indicates the state of the trailer left-hand rear registration-plate light(s).";
CM_ SG_ 2566808830 TrailerLeftRearLight "This signal indicates the state of the trailer left-hand rear light(s).";
CM_ SG_ 2566808830 TrailerLeftRearFogLight "This signal indicates the state of the trailer left-hand rear fog light(s).";
CM_ SG_ 2566808830 TrailerLeftDirIndLight "This signal indicates the state of the trailer left-hand direction indicator light(s).";
CM_ SG_ 2566808830 TrailerLeftCrnMarkerLight "This signal indicates the state of the trailer left-hand corner marker light(s).";
CM_ SG_ 2566808830 TrailerInteriorLight "This signal indicates the state of the trailer interior light(s).";
CM_ SG_ 2566808830 TrailerWorkLamp "This signal indicates the state of the trailer work lamp(s).";
CM_ SG_ 2566808830 TrailerRotatingIdentLight "This signal indicates the state of the trailer rotating identification light(s).";
CM_ SG_ 2566808830 TrailerRightStopLight "This signal indicates the state of the trailer right-hand stop light(s).";
CM_ SG_ 2566808830 TrailerRightSideMrkLight "This signal indicates the state of the trailer right-hand side marker light(s).";
CM_ SG_ 2566808830 TrailerRightReversingLight "This signal indicates the state of the trailer right-hand reversing light(s).";
CM_ SG_ 2566808830 TrailRightRearWidIndLight "This signal indicates the state of the trailer right-hand rear width indicator light(s).";
CM_ SG_ 2566808830 TrailerRightRearRegPltLight "This signal indicates the state of the trailer right-hand rear registration-plate light(s).";
CM_ SG_ 2566808830 TrailerRightRearLight "This signal indicates the state of the trailer right-hand rear light(s).";
CM_ SG_ 2566808830 TrailerRightRearFogLight "This signal indicates the state of the trailer right-hand rear fog light(s).";
CM_ SG_ 2566808830 TrailerRightDirIndLight "This signal indicates the state of the trailer right-hand direction indicator light(s).";
CM_ SG_ 2566808830 TrailerRightCrnMarkerLight "This signal indicates the state of the trailer right-hand corner marker light(s).";
CM_ SG_ 2566808830 TrailerRearWarningLight "This signal indicates the state of the trailer rear warning light(s).";
CM_ SG_ 2566808830 TrailerLeftStopLight "This signal indicates the state of the trailer left-hand stop light(s).";
CM_ BO_ 2564554494 "Reserved for ISO 15765";
CM_ SG_ 2564554494 ProtocolCtrlInformation "Part of Network Protocol Control Information (N_PCI) of a ISO 15765 message.";
CM_ BO_ 2564488958 "Reserved for ISO 15765";
CM_ SG_ 2564488958 ProtocolCtrlInformation "Part of Network Protocol Control Information (N_PCI) of a ISO 15765 message.";
CM_ BO_ 2565734142 "Network Layer";
CM_ SG_ 2565734142 NumberOfSA_NAMEPairs "The number of instances of Source Addresses and associated NAMEs included in the associated data content.";
CM_ SG_ 2565734142 ToPort "Identifies the destination port, or send port, of messages being moved through the NIECU. 
The Port Number assignments are defined within SAE J1939-31. ";
CM_ SG_ 2565734142 NetworkMessageControlByte "Identifies the function or service of an instance of the Network Message.  
A summary of the Network Message Control Bytes value assignments are defined within SAE J1939-31.";
CM_ SG_ 2565734142 FilterMode "Identifies the mode of filtering operation applied for messages being passed from one specific port to another specific port. 
The Filter Mode value assignments are defined within SAE J1939-31.";
CM_ SG_ 2565734142 NIECUPort "Identifies a specific port of the NIECU without context of messaging direction. 
The Port Number assignments are defined within SAE J1939-31.";
CM_ SG_ 2565734142 FromPort "Identifies the origination port, or receive port, of messages being moved through the NIECU. 
The Port Number assignments are defined within SAE J1939-31. ";
CM_ BO_ 2565144318 "Running Gear Equipment #1/1
Message to transmit data of the towing vehicle to the towed vehicle. See ISO 11992-2.";
CM_ SG_ 2565144318 ParkingAndTrailerAirPress "The pneumatic pressure in the circuit or reservoir for the parking brake and the trailer supply.";
CM_ SG_ 2565144318 DrivenAxleLoad "Actual static vertical load on driven axle of the commercial vehicle. In case of more than one driven axle the value of the axle with the highest vertical load is transmitted.";
CM_ SG_ 2565144318 AuxEquipSupplyPressure "The pneumatic pressure in the auxiliary circuit.";
CM_ SG_ 2565144318 StopLevelChangeReq "Command signal to stop immediately any change of the actual body height level.";
CM_ SG_ 2565144318 RampLevelStorageReq "Command signal to store the actual body height level as new programmed and memorised ramp levels 1 or 2 in the ECU";
CM_ SG_ 2565144318 LevelControlReq "Command signal to enable or disable the automatic level control.";
CM_ SG_ 2565144318 RampLevelReq "Command signal to control the body height to a level programmed and memorised in the ECU.";
CM_ SG_ 2565144318 SteeringAxleLockingReq "Command signal to lock the steering axle.";
CM_ SG_ 2565144318 LiftAxle2PositionReq "Command signal to control the lift axle position / tag axle load condition.";
CM_ SG_ 2565144318 LiftAxle1PositionReq "Command signal to control the lift axle position / tag axle load condition.";
CM_ SG_ 2565144318 TractionHelpReq "Command signal to control the lift axle position / tag axle load condition to transfer more load on the driven axle of the commercial vehicle.";
CM_ SG_ 2565144318 LevelChangeReqRearAxle "Command signal to control the body height [up (lifting)/down (lowering)] for the rear axle.";
CM_ SG_ 2565144318 LevelChangeReqFrontAxle "Command signal to control the body height [up (lifting)/down (lowering)] for the front axle.";
CM_ SG_ 2565144318 RideHeightRequest "Command signal to activate a normal ride body height. The normal levels 1 and 2 are trailer specific body heights.";
CM_ BO_ 2565209854 "Running Gear Equipment #2/1
Message to transmit data of the towed vehicle to the towing vehicle. See ISO 11992-2.";
CM_ SG_ 2565209854 LevelControl "Signal which indicates that the automatic level control is enabled or disabled.";
CM_ SG_ 2565209854 NominalVehBodyLevelRearAxle "Actual nominal vehicle body height.";
CM_ SG_ 2565209854 NominalVehBodyLevelFrontAxle "Actual nominal vehicle body height.";
CM_ SG_ 2565209854 RampLevel "Signal which indicates the level of the body height as an anser to 'ramp level request'.";
CM_ SG_ 2565209854 NormalLevel "Signal which indicates the normal levels of the vehicle independently of a specific request.";
CM_ SG_ 2565209854 StopLevelChangeAcknowledge "Signal which indicates the stop of any level change due to a 'stop request'.";
CM_ SG_ 2565209854 LevelChangeRearAxle "Signal which indicates the level change of the body height at the rear axle due to any external requests.";
CM_ SG_ 2565209854 LevelChangeFrontAxle "Signal which indicates the level change of the body height at the front axle due to any external requests.";
CM_ SG_ 2565209854 RampLevelStorage "Signal which indicates the storage of a new ramp level in the ECU.";
CM_ SG_ 2565209854 SteeringAxleLocking "Signal which indicates the actual steering axle locking status.";
CM_ SG_ 2565209854 LiftAxle2Pos "Signal which indicates the position / load condition of lift axle / tag axle #2.   Numbering of lift/tag axles starts at front axle.  See SPN 6844 for more detail.
00 Lift axle position down / tag axle laden
01 Lift axle position up / tag axle ...";
CM_ SG_ 2565209854 LiftAxle1Pos "Signal which indicates the position / load condition of lift axle / tag axle 1.   Numbering of lift/tag axles starts at front axle.  See SPN 6843 for more detail.
00 Lift axle position down / tag axle laden
01 Lift axle position up / tag axle ...";
CM_ SG_ 2565209854 RampLevelPosition "Signal which indicates the ramp level positions of the vehicle independently of a specific request.";
CM_ SG_ 2565209854 TractionHelp "Signal which indicates that a load transfer is active.";
CM_ SG_ 2565209854 LevelCtrlSysRideHeightLevel "Signal which indicates the body height position of the vehicle as an answer to 'ride height request'.";
CM_ BO_ 2566806782 "Running Gear Equipment #2/2
Message to transmit data of the towed vehicle to the towing vehicle. See ISO 11992-2.";
CM_ SG_ 2566806782 RelVehBodyLevelRearAxle "Actual relative vehicle body height.";
CM_ SG_ 2566806782 RelVehBodyLevelFrontAxle "Actual relative vehicle body height.";
BA_DEF_ SG_  "SigType" ENUM  "Default","Range","RangeSigned","ASCII","Discrete","Control","ReferencePGN","DTC","StringDelimiter","StringLength","StringLengthControl","MessageCounter","MessageChecksum";
BA_DEF_ SG_  "GenSigStartValue" INT 0 2147483647;
BA_DEF_ SG_  "GenSigSendType" ENUM  "Cyclic","OnWrite","OnWriteWithRepetition","OnChange","OnChangeWithRepetition","IfActive","IfActiveWithRepetition","NoSigSendType";
BA_DEF_ SG_  "GenSigILSupport" ENUM  "No","Yes";
BA_DEF_ SG_  "GenSigEVName" STRING ;
BA_DEF_ SG_  "SPN" INT 0 524287;
BA_DEF_ BO_  "TpJ1939VarDlc" ENUM  "No","Yes";
BA_DEF_ BO_  "GenMsgStartDelayTime" INT 0 100000;
BA_DEF_ BO_  "GenMsgILSupport" ENUM  "No","Yes";
BA_DEF_ BO_  "GenMsgDelayTime" INT 0 1000;
BA_DEF_ BO_  "GenMsgRequestable" INT 0 1;
BA_DEF_ BO_  "GenMsgSendType" ENUM  "cyclic","NotUsed","NotUsed","NotUsed","NotUsed","NotUsed","NotUsed","IfActive","noMsgSendType";
BA_DEF_ BO_  "VFrameFormat" ENUM  "StandardCAN","ExtendedCAN","reserved","J1939PG";
BA_DEF_ BO_  "GenMsgCycleTime" INT 0 3600000;
BA_DEF_ SG_  "SystemSignalLongSymbol" STRING ;
BA_DEF_DEF_  "SigType" "Default";
BA_DEF_DEF_  "GenSigStartValue" 0;
BA_DEF_DEF_  "GenSigSendType" "NoSigSendType";
BA_DEF_DEF_  "GenSigILSupport" "Yes";
BA_DEF_DEF_  "GenSigEVName" "Env@Nodename_@Signame";
BA_DEF_DEF_  "SPN" 0;
BA_DEF_DEF_  "TpJ1939VarDlc" "No";
BA_DEF_DEF_  "GenMsgStartDelayTime" 0;
BA_DEF_DEF_  "GenMsgILSupport" "Yes";
BA_DEF_DEF_  "GenMsgDelayTime" 0;
BA_DEF_DEF_  "GenMsgRequestable" 1;
BA_DEF_DEF_  "GenMsgSendType" "noMsgSendType";
BA_DEF_DEF_  "VFrameFormat" "J1939PG";
BA_DEF_DEF_  "GenMsgCycleTime" 0;
BA_DEF_DEF_  "SystemSignalLongSymbol" "";
BA_ "GenMsgCycleTime" BO_ 2365485822 50;
BA_ "GenMsgSendType" BO_ 2365485822 0;
BA_ "GenMsgCycleTime" BO_ 2566768894 1000;
BA_ "GenMsgSendType" BO_ 2566768894 0;
BA_ "GenMsgCycleTime" BO_ 2566769406 1000;
BA_ "GenMsgSendType" BO_ 2566769406 0;
BA_ "GenMsgCycleTime" BO_ 2633934334 1000;
BA_ "GenMsgSendType" BO_ 2633934334 0;
BA_ "GenMsgCycleTime" BO_ 2566825726 5000;
BA_ "GenMsgSendType" BO_ 2566825726 0;
BA_ "GenMsgCycleTime" BO_ 2566770942 5000;
BA_ "GenMsgSendType" BO_ 2566770942 0;
BA_ "GenMsgCycleTime" BO_ 2566846206 5000;
BA_ "GenMsgSendType" BO_ 2566846206 0;
BA_ "GenMsgCycleTime" BO_ 2566811134 1000;
BA_ "GenMsgSendType" BO_ 2566811134 0;
BA_ "GenMsgCycleTime" BO_ 2298375934 20;
BA_ "GenMsgSendType" BO_ 2298375934 0;
BA_ "GenMsgCycleTime" BO_ 2565867774 50;
BA_ "GenMsgSendType" BO_ 2565867774 0;
BA_ "GenMsgCycleTime" BO_ 2365449982 100;
BA_ "GenMsgSendType" BO_ 2365449982 0;
BA_ "GenMsgCycleTime" BO_ 2633927678 100;
BA_ "GenMsgSendType" BO_ 2633927678 0;
BA_ "GenMsgCycleTime" BO_ 2566757630 1000;
BA_ "GenMsgSendType" BO_ 2566757630 0;
BA_ "GenMsgCycleTime" BO_ 2566757886 1000;
BA_ "GenMsgSendType" BO_ 2566757886 0;
BA_ "GenMsgCycleTime" BO_ 2566759678 100;
BA_ "GenMsgSendType" BO_ 2566759678 0;
BA_ "GenMsgCycleTime" BO_ 2432541438 500;
BA_ "GenMsgSendType" BO_ 2432541438 0;
BA_ "GenMsgCycleTime" BO_ 2566761214 500;
BA_ "GenMsgSendType" BO_ 2566761214 0;
BA_ "GenMsgCycleTime" BO_ 2432541694 100;
BA_ "GenMsgSendType" BO_ 2432541694 0;
BA_ "GenMsgCycleTime" BO_ 2566759934 100;
BA_ "GenMsgSendType" BO_ 2566759934 0;
BA_ "GenMsgCycleTime" BO_ 2566757374 1000;
BA_ "GenMsgSendType" BO_ 2566757374 0;
BA_ "GenMsgCycleTime" BO_ 2364546302 100;
BA_ "GenMsgSendType" BO_ 2364546302 0;
BA_ "GenMsgCycleTime" BO_ 2431654654 50;
BA_ "GenMsgSendType" BO_ 2431654654 0;
BA_ "GenMsgCycleTime" BO_ 2364545534 5000;
BA_ "GenMsgSendType" BO_ 2364545534 0;
BA_ "GenMsgCycleTime" BO_ 2364545278 5000;
BA_ "GenMsgSendType" BO_ 2364545278 0;
BA_ "GenMsgCycleTime" BO_ 2364545022 5000;
BA_ "GenMsgSendType" BO_ 2364545022 0;
BA_ "GenMsgCycleTime" BO_ 2364544766 5000;
BA_ "GenMsgSendType" BO_ 2364544766 0;
BA_ "GenMsgCycleTime" BO_ 2364544510 100;
BA_ "GenMsgSendType" BO_ 2364544510 0;
BA_ "GenMsgCycleTime" BO_ 2364544254 50;
BA_ "GenMsgSendType" BO_ 2364544254 0;
BA_ "GenMsgCycleTime" BO_ 2550333182 10;
BA_ "GenMsgSendType" BO_ 2550333182 0;
BA_ "GenMsgCycleTime" BO_ 2566834686 100;
BA_ "GenMsgSendType" BO_ 2566834686 0;
BA_ "GenMsgCycleTime" BO_ 2550398718 10;
BA_ "GenMsgSendType" BO_ 2550398718 0;
BA_ "GenMsgCycleTime" BO_ 2566833406 100;
BA_ "GenMsgSendType" BO_ 2566833406 0;
BA_ "GenMsgCycleTime" BO_ 2566833918 100;
BA_ "GenMsgSendType" BO_ 2566833918 0;
BA_ "GenMsgCycleTime" BO_ 2565013246 100;
BA_ "GenMsgSendType" BO_ 2565013246 0;
BA_ "GenMsgCycleTime" BO_ 2566807038 500;
BA_ "GenMsgSendType" BO_ 2566807038 0;
BA_ "GenMsgCycleTime" BO_ 2566807550 50;
BA_ "GenMsgSendType" BO_ 2566807550 0;
BA_ "GenMsgCycleTime" BO_ 2566808062 100;
BA_ "GenMsgSendType" BO_ 2566808062 0;
BA_ "GenMsgCycleTime" BO_ 2566808574 1000;
BA_ "GenMsgSendType" BO_ 2566808574 0;
BA_ "GenMsgCycleTime" BO_ 2566809086 100;
BA_ "GenMsgSendType" BO_ 2566809086 0;
BA_ "GenMsgCycleTime" BO_ 2564947710 100;
BA_ "GenMsgSendType" BO_ 2564947710 0;
BA_ "GenMsgCycleTime" BO_ 2566834430 100;
BA_ "GenMsgSendType" BO_ 2566834430 0;
BA_ "GenMsgCycleTime" BO_ 2566807806 100;
BA_ "GenMsgSendType" BO_ 2566807806 0;
BA_ "GenMsgCycleTime" BO_ 2566808318 100;
BA_ "GenMsgSendType" BO_ 2566808318 0;
BA_ "GenMsgCycleTime" BO_ 2566808830 100;
BA_ "GenMsgSendType" BO_ 2566808830 0;
BA_ "GenMsgRequestable" BO_ 2564554494 0;
BA_ "GenMsgRequestable" BO_ 2564488958 0;
BA_ "GenMsgCycleTime" BO_ 2565144318 100;
BA_ "GenMsgSendType" BO_ 2565144318 0;
BA_ "GenMsgCycleTime" BO_ 2565209854 100;
BA_ "GenMsgSendType" BO_ 2565209854 0;
BA_ "GenMsgCycleTime" BO_ 2566806782 100;
BA_ "GenMsgSendType" BO_ 2566806782 0;
BA_ "SPN" SG_ 2365485822 LandLevelingSystemEnableStatus 5409;
BA_ "SigType" SG_ 2365485822 LandLevelingSystemEnableStatus 5;
BA_ "SPN" SG_ 2365485822 BladeCtrlModeRight 5408;
BA_ "SPN" SG_ 2365485822 BladeCtrlModeLeft 5407;
BA_ "SPN" SG_ 2365485822 BladeCtrlMode 1578;
BA_ "SPN" SG_ 2365485822 BladeDurationAndDirection 1577;
BA_ "SigType" SG_ 2365485822 BladeDurationAndDirection 1;
BA_ "SPN" SG_ 2633926654 EngActualIgntTiming 1436;
BA_ "SigType" SG_ 2633926654 EngActualIgntTiming 1;
BA_ "SPN" SG_ 2633926654 EngDesiredIgntTiming3 1435;
BA_ "SigType" SG_ 2633926654 EngDesiredIgntTiming3 1;
BA_ "SPN" SG_ 2633926654 EngDesiredIgntTiming2 1434;
BA_ "SigType" SG_ 2633926654 EngDesiredIgntTiming2 1;
BA_ "SPN" SG_ 2633926654 EngDesiredIgntTiming1 1433;
BA_ "SigType" SG_ 2633926654 EngDesiredIgntTiming1 1;
BA_ "SPN" SG_ 2633926398 EngCyl20IgntTiming 1432;
BA_ "SigType" SG_ 2633926398 EngCyl20IgntTiming 1;
BA_ "SPN" SG_ 2633926398 EngCyl19IgntTiming 1431;
BA_ "SigType" SG_ 2633926398 EngCyl19IgntTiming 1;
BA_ "SPN" SG_ 2633926398 EngCyl18IgntTiming 1430;
BA_ "SigType" SG_ 2633926398 EngCyl18IgntTiming 1;
BA_ "SPN" SG_ 2633926398 EngCyl17IgntTiming 1429;
BA_ "SigType" SG_ 2633926398 EngCyl17IgntTiming 1;
BA_ "SPN" SG_ 2633926142 EngCyl16IgntTiming 1428;
BA_ "SigType" SG_ 2633926142 EngCyl16IgntTiming 1;
BA_ "SPN" SG_ 2633926142 EngCyl15IgntTiming 1427;
BA_ "SigType" SG_ 2633926142 EngCyl15IgntTiming 1;
BA_ "SPN" SG_ 2633926142 EngCyl14IgntTiming 1426;
BA_ "SigType" SG_ 2633926142 EngCyl14IgntTiming 1;
BA_ "SPN" SG_ 2633926142 EngCyl13IgntTiming 1425;
BA_ "SigType" SG_ 2633926142 EngCyl13IgntTiming 1;
BA_ "SPN" SG_ 2633925886 EngCyl12IgntTiming 1424;
BA_ "SigType" SG_ 2633925886 EngCyl12IgntTiming 1;
BA_ "SPN" SG_ 2633925886 EngCyl11IgntTiming 1423;
BA_ "SigType" SG_ 2633925886 EngCyl11IgntTiming 1;
BA_ "SPN" SG_ 2633925886 EngCyl10IgntTiming 1422;
BA_ "SigType" SG_ 2633925886 EngCyl10IgntTiming 1;
BA_ "SPN" SG_ 2633925886 EngCyl9IgntTiming 1421;
BA_ "SigType" SG_ 2633925886 EngCyl9IgntTiming 1;
BA_ "SPN" SG_ 2633925630 EngCyl8IgntTiming 1420;
BA_ "SigType" SG_ 2633925630 EngCyl8IgntTiming 1;
BA_ "SPN" SG_ 2633925630 EngCyl7IgntTiming 1419;
BA_ "SigType" SG_ 2633925630 EngCyl7IgntTiming 1;
BA_ "SPN" SG_ 2633925630 EngCyl6IgntTiming 1418;
BA_ "SigType" SG_ 2633925630 EngCyl6IgntTiming 1;
BA_ "SPN" SG_ 2633925630 EngCyl5IgntTiming 1417;
BA_ "SigType" SG_ 2633925630 EngCyl5IgntTiming 1;
BA_ "SPN" SG_ 2633925374 EngCyl4IgntTiming 1416;
BA_ "SigType" SG_ 2633925374 EngCyl4IgntTiming 1;
BA_ "SPN" SG_ 2633925374 EngCyl3IgntTiming 1415;
BA_ "SigType" SG_ 2633925374 EngCyl3IgntTiming 1;
BA_ "SPN" SG_ 2633925374 EngCyl2IgntTiming 1414;
BA_ "SigType" SG_ 2633925374 EngCyl2IgntTiming 1;
BA_ "SPN" SG_ 2633925374 EngCyl1IgntTiming 1413;
BA_ "SigType" SG_ 2633925374 EngCyl1IgntTiming 1;
BA_ "SPN" SG_ 2633927422 EngCyl20IgntTransSecondOutput 1412;
BA_ "SigType" SG_ 2633927422 EngCyl20IgntTransSecondOutput 1;
BA_ "SPN" SG_ 2633927422 EngCyl19IgntTransSecondOutput 1411;
BA_ "SigType" SG_ 2633927422 EngCyl19IgntTransSecondOutput 1;
BA_ "SPN" SG_ 2633927422 EngCyl18IgntTransSecondOutput 1410;
BA_ "SigType" SG_ 2633927422 EngCyl18IgntTransSecondOutput 1;
BA_ "SPN" SG_ 2633927422 EngCyl17IgntTransSecondOutput 1409;
BA_ "SigType" SG_ 2633927422 EngCyl17IgntTransSecondOutput 1;
BA_ "SPN" SG_ 2633927166 EngCyl16IgntTransSecondOutput 1408;
BA_ "SigType" SG_ 2633927166 EngCyl16IgntTransSecondOutput 1;
BA_ "SPN" SG_ 2633927166 EngCyl15IgntTransSecondOutput 1407;
BA_ "SigType" SG_ 2633927166 EngCyl15IgntTransSecondOutput 1;
BA_ "SPN" SG_ 2633927166 EngCyl14IgntTransSecondOutput 1406;
BA_ "SigType" SG_ 2633927166 EngCyl14IgntTransSecondOutput 1;
BA_ "SPN" SG_ 2633927166 EngCyl13IgntTransSecondOutput 1405;
BA_ "SigType" SG_ 2633927166 EngCyl13IgntTransSecondOutput 1;
BA_ "SPN" SG_ 2633927166 EngCyl12IgntTransSecondOutput 1404;
BA_ "SigType" SG_ 2633927166 EngCyl12IgntTransSecondOutput 1;
BA_ "SPN" SG_ 2633927166 EngCyl11IgntTransSecondOutput 1403;
BA_ "SigType" SG_ 2633927166 EngCyl11IgntTransSecondOutput 1;
BA_ "SPN" SG_ 2633927166 EngCyl10IgntTransSecondOutput 1402;
BA_ "SigType" SG_ 2633927166 EngCyl10IgntTransSecondOutput 1;
BA_ "SPN" SG_ 2633927166 EngCyl9IgntTransSecondOutput 1401;
BA_ "SigType" SG_ 2633927166 EngCyl9IgntTransSecondOutput 1;
BA_ "SPN" SG_ 2633926910 EngCyl8IgntTransSecondOutput 1400;
BA_ "SigType" SG_ 2633926910 EngCyl8IgntTransSecondOutput 1;
BA_ "SPN" SG_ 2633926910 EngCyl7IgntTransSecondOutput 1399;
BA_ "SigType" SG_ 2633926910 EngCyl7IgntTransSecondOutput 1;
BA_ "SPN" SG_ 2633926910 EngCyl6IgntTransSecondOutput 1398;
BA_ "SigType" SG_ 2633926910 EngCyl6IgntTransSecondOutput 1;
BA_ "SPN" SG_ 2633926910 EngCyl5IgntTransSecondOutput 1397;
BA_ "SigType" SG_ 2633926910 EngCyl5IgntTransSecondOutput 1;
BA_ "SPN" SG_ 2633926910 EngCyl4IgntTransSecondOutput 1396;
BA_ "SigType" SG_ 2633926910 EngCyl4IgntTransSecondOutput 1;
BA_ "SPN" SG_ 2633926910 EngCyl3IgntTransSecondOutput 1395;
BA_ "SigType" SG_ 2633926910 EngCyl3IgntTransSecondOutput 1;
BA_ "SPN" SG_ 2633926910 EngCyl2IgntTransSecondOutput 1394;
BA_ "SigType" SG_ 2633926910 EngCyl2IgntTransSecondOutput 1;
BA_ "SPN" SG_ 2633926910 EngCyl1IgntTransSecondOutput 1393;
BA_ "SigType" SG_ 2633926910 EngCyl1IgntTransSecondOutput 1;
BA_ "SPN" SG_ 2566768894 EngOprtrPrmryIntrmdtSpdSlctState 2892;
BA_ "SPN" SG_ 2566769406 EngOprtrPrmryIntrmdteSpeedSelect 2880;
BA_ "SPN" SG_ 2566839550 EngTotalIdleHours 235;
BA_ "SigType" SG_ 2566839550 EngTotalIdleHours 1;
BA_ "SPN" SG_ 2566839550 EngTotalIdleFuelUsed 236;
BA_ "SigType" SG_ 2566839550 EngTotalIdleFuelUsed 1;
BA_ "SPN" SG_ 2633934334 EngIntakeManifold6Temp 1803;
BA_ "SigType" SG_ 2633934334 EngIntakeManifold6Temp 1;
BA_ "SPN" SG_ 2633934334 EngIntakeManifold5Temp 1802;
BA_ "SigType" SG_ 2633934334 EngIntakeManifold5Temp 1;
BA_ "SPN" SG_ 2633934334 EngIntakeManifold4Temp 1133;
BA_ "SigType" SG_ 2633934334 EngIntakeManifold4Temp 1;
BA_ "SPN" SG_ 2633934334 EngIntakeManifold3Temp 1132;
BA_ "SigType" SG_ 2633934334 EngIntakeManifold3Temp 1;
BA_ "SPN" SG_ 2633934334 EngIntakeManifold2Temp 1131;
BA_ "SigType" SG_ 2633934334 EngIntakeManifold2Temp 1;
BA_ "SPN" SG_ 2566825726 EngTurbo4BoostPress 1130;
BA_ "SigType" SG_ 2566825726 EngTurbo4BoostPress 1;
BA_ "SPN" SG_ 2566825726 EngTurbo3BoostPress 1129;
BA_ "SigType" SG_ 2566825726 EngTurbo3BoostPress 1;
BA_ "SPN" SG_ 2566825726 EngTurbo2BoostPress 1128;
BA_ "SigType" SG_ 2566825726 EngTurbo2BoostPress 1;
BA_ "SPN" SG_ 2566825726 EngTurbo1BoostPress 1127;
BA_ "SigType" SG_ 2566825726 EngTurbo1BoostPress 1;
BA_ "SPN" SG_ 2566770942 EngIntakeManifold2AbsPress 5422;
BA_ "SigType" SG_ 2566770942 EngIntakeManifold2AbsPress 1;
BA_ "SPN" SG_ 2566770942 EngIntakeManifold1AbsPress4817 4817;
BA_ "SigType" SG_ 2566770942 EngIntakeManifold1AbsPress4817 1;
BA_ "SPN" SG_ 2566770942 EngIntakeManifold1AbsPress 3563;
BA_ "SigType" SG_ 2566770942 EngIntakeManifold1AbsPress 1;
BA_ "SPN" SG_ 2566770942 EngIntakeManifold2Press 3562;
BA_ "SigType" SG_ 2566770942 EngIntakeManifold2Press 1;
BA_ "SPN" SG_ 2566770942 EngAirFilter4DiffPress 2811;
BA_ "SigType" SG_ 2566770942 EngAirFilter4DiffPress 1;
BA_ "SPN" SG_ 2566770942 EngAirFilter3DiffPress 2810;
BA_ "SigType" SG_ 2566770942 EngAirFilter3DiffPress 1;
BA_ "SPN" SG_ 2566770942 EngAirFilter2DiffPress 2809;
BA_ "SigType" SG_ 2566770942 EngAirFilter2DiffPress 1;
BA_ "SPN" SG_ 2566846206 EngCoolantFilterDiffPress 112;
BA_ "SigType" SG_ 2566846206 EngCoolantFilterDiffPress 1;
BA_ "SPN" SG_ 2566846206 EngExhaustGasTemp 173;
BA_ "SigType" SG_ 2566846206 EngExhaustGasTemp 1;
BA_ "SPN" SG_ 2566846206 EngAirFilter1DiffPress 107;
BA_ "SigType" SG_ 2566846206 EngAirFilter1DiffPress 1;
BA_ "SPN" SG_ 2566846206 EngAirIntakePress 106;
BA_ "SigType" SG_ 2566846206 EngAirIntakePress 1;
BA_ "SPN" SG_ 2566846206 EngIntakeManifold1Temp 105;
BA_ "SigType" SG_ 2566846206 EngIntakeManifold1Temp 1;
BA_ "SPN" SG_ 2566846206 EngIntakeManifold1Press 102;
BA_ "SigType" SG_ 2566846206 EngIntakeManifold1Press 1;
BA_ "SPN" SG_ 2566846206 AFT1DPFInPress 81;
BA_ "SigType" SG_ 2566846206 AFT1DPFInPress 1;
BA_ "SPN" SG_ 2566811134 ADRCompliantHeaterInstallation 6821;
BA_ "SigType" SG_ 2566811134 ADRCompliantHeaterInstallation 5;
BA_ "SPN" SG_ 2566811134 CabHeatingZone 1680;
BA_ "SigType" SG_ 2566811134 CabHeatingZone 5;
BA_ "SPN" SG_ 2566811134 EngHeatingZone 1679;
BA_ "SigType" SG_ 2566811134 EngHeatingZone 5;
BA_ "SPN" SG_ 2566811134 CabVentilation 1678;
BA_ "SigType" SG_ 2566811134 CabVentilation 5;
BA_ "SPN" SG_ 2566811134 AuxHeaterWaterPumpStatus 1676;
BA_ "SigType" SG_ 2566811134 AuxHeaterWaterPumpStatus 5;
BA_ "SPN" SG_ 2566811134 AuxHeaterMode 1677;
BA_ "SPN" SG_ 2566811134 AuxHeaterOutputPowerPercent 1689;
BA_ "SigType" SG_ 2566811134 AuxHeaterOutputPowerPercent 1;
BA_ "SPN" SG_ 2566811134 AuxHeaterInputAirTemp 1688;
BA_ "SigType" SG_ 2566811134 AuxHeaterInputAirTemp 1;
BA_ "SPN" SG_ 2566811134 AuxHeaterOutputCoolantTemp 1687;
BA_ "SigType" SG_ 2566811134 AuxHeaterOutputCoolantTemp 1;
BA_ "SPN" SG_ 2298375934 RearAxleRightWheelSpeed 1595;
BA_ "SigType" SG_ 2298375934 RearAxleRightWheelSpeed 1;
BA_ "SPN" SG_ 2298375934 RearAxleLeftWheelSpeed 1594;
BA_ "SigType" SG_ 2298375934 RearAxleLeftWheelSpeed 1;
BA_ "SPN" SG_ 2298375934 FrontAxleRightWheelSpeed 1593;
BA_ "SigType" SG_ 2298375934 FrontAxleRightWheelSpeed 1;
BA_ "SPN" SG_ 2298375934 FrontAxleLeftWheelSpeed 1592;
BA_ "SigType" SG_ 2298375934 FrontAxleLeftWheelSpeed 1;
BA_ "SPN" SG_ 2565867774 FireApparatusPumpEngagement 2599;
BA_ "SigType" SG_ 2565867774 FireApparatusPumpEngagement 4;
BA_ "SPN" SG_ 2565867774 HydPressGovernorPresetSwitch 6706;
BA_ "SigType" SG_ 2565867774 HydPressGovernorPresetSwitch 4;
BA_ "SPN" SG_ 2565867774 HydPressGovernorIncreaseSwitch 6703;
BA_ "SigType" SG_ 2565867774 HydPressGovernorIncreaseSwitch 4;
BA_ "SPN" SG_ 2565867774 HydPressGovernorDecreaseSwitch 6704;
BA_ "SigType" SG_ 2565867774 HydPressGovernorDecreaseSwitch 4;
BA_ "SPN" SG_ 2565867774 HydPressGovernorIdleSwitch 6705;
BA_ "SigType" SG_ 2565867774 HydPressGovernorIdleSwitch 4;
BA_ "SPN" SG_ 2565867774 HydDischargePressSetPoint 6708;
BA_ "SigType" SG_ 2565867774 HydDischargePressSetPoint 1;
BA_ "SPN" SG_ 2565867774 HydIntakePress 6707;
BA_ "SigType" SG_ 2565867774 HydIntakePress 1;
BA_ "SPN" SG_ 2565867774 FireApparatusOkayToPumpInterlock 6702;
BA_ "SigType" SG_ 2565867774 FireApparatusOkayToPumpInterlock 4;
BA_ "SPN" SG_ 2565867774 EngHydPressGovernorSwitch 1764;
BA_ "SigType" SG_ 2565867774 EngHydPressGovernorSwitch 4;
BA_ "SPN" SG_ 2565867774 EngHydPressGovernorModeIndicator 1763;
BA_ "SigType" SG_ 2565867774 EngHydPressGovernorModeIndicator 5;
BA_ "SPN" SG_ 2565867774 HydPress 1762;
BA_ "SigType" SG_ 2565867774 HydPress 1;
BA_ "SPN" SG_ 2566841854 EngTotalRevolutions 249;
BA_ "SigType" SG_ 2566841854 EngTotalRevolutions 1;
BA_ "SPN" SG_ 2566841854 EngTotalHoursOfOperation 247;
BA_ "SigType" SG_ 2566841854 EngTotalHoursOfOperation 1;
BA_ "SPN" SG_ 2365449982 HydBrakeFluidLevelSwitch 2931;
BA_ "SigType" SG_ 2365449982 HydBrakeFluidLevelSwitch 4;
BA_ "SPN" SG_ 2365449982 HydBrakeSystemAudibleWarningCmd 2930;
BA_ "SigType" SG_ 2365449982 HydBrakeSystemAudibleWarningCmd 5;
BA_ "SPN" SG_ 2365449982 HydBrakePressSupplyStateCircuit2 2583;
BA_ "SigType" SG_ 2365449982 HydBrakePressSupplyStateCircuit2 4;
BA_ "SPN" SG_ 2365449982 HydBrakePressSupplyStateCircuit1 2582;
BA_ "SigType" SG_ 2365449982 HydBrakePressSupplyStateCircuit1 4;
BA_ "SPN" SG_ 2365449982 HydBrkePressWarningStateCircuit2 2585;
BA_ "SigType" SG_ 2365449982 HydBrkePressWarningStateCircuit2 4;
BA_ "SPN" SG_ 2365449982 HydBrkePressWarningStateCircuit1 2584;
BA_ "SigType" SG_ 2365449982 HydBrkePressWarningStateCircuit1 4;
BA_ "SPN" SG_ 2365449982 HydBrakePressCircuit2 2581;
BA_ "SigType" SG_ 2365449982 HydBrakePressCircuit2 1;
BA_ "SPN" SG_ 2365449982 HydBrakePressCircuit1 2580;
BA_ "SigType" SG_ 2365449982 HydBrakePressCircuit1 1;
BA_ "SPN" SG_ 2633939198 TripDriveFuelEconomy 1012;
BA_ "SigType" SG_ 2633939198 TripDriveFuelEconomy 1;
BA_ "SPN" SG_ 2633939198 TripCruiseFuelUsed 1011;
BA_ "SigType" SG_ 2633939198 TripCruiseFuelUsed 1;
BA_ "SPN" SG_ 2633939198 TripVehicleIdleFuelUsed 1010;
BA_ "SigType" SG_ 2633939198 TripVehicleIdleFuelUsed 1;
BA_ "SPN" SG_ 2633939198 TripPTOGovernorNonmovingFuelUsed 1009;
BA_ "SigType" SG_ 2633939198 TripPTOGovernorNonmovingFuelUsed 1;
BA_ "SPN" SG_ 2633939198 TripPTOGovernorMovingFuelUsed 1008;
BA_ "SigType" SG_ 2633939198 TripPTOGovernorMovingFuelUsed 1;
BA_ "SPN" SG_ 2633939198 TripDriveFuelUsed 1007;
BA_ "SigType" SG_ 2633939198 TripDriveFuelUsed 1;
BA_ "SPN" SG_ 2633927678 EngFuelValve1OutletAbsPress 2980;
BA_ "SigType" SG_ 2633927678 EngFuelValve1OutletAbsPress 1;
BA_ "SPN" SG_ 2633927678 EngAirToFuelDiffPress 1392;
BA_ "SigType" SG_ 2633927678 EngAirToFuelDiffPress 1;
BA_ "SPN" SG_ 2633927678 EngFuelValveDiffPress 1391;
BA_ "SigType" SG_ 2633927678 EngFuelValveDiffPress 1;
BA_ "SPN" SG_ 2633927678 EngFuelValve1IntakeAbsPress 1390;
BA_ "SigType" SG_ 2633927678 EngFuelValve1IntakeAbsPress 1;
BA_ "SPN" SG_ 2633925118 EngRequestedFuelValve2Pos 1766;
BA_ "SigType" SG_ 2633925118 EngRequestedFuelValve2Pos 1;
BA_ "SPN" SG_ 2633925118 EngRequestedFuelValve1Pos 1765;
BA_ "SigType" SG_ 2633925118 EngRequestedFuelValve1Pos 1;
BA_ "SPN" SG_ 2633925118 EngFuelValve2Pos 1443;
BA_ "SigType" SG_ 2633925118 EngFuelValve2Pos 1;
BA_ "SPN" SG_ 2633925118 EngFuelValve1Pos 1442;
BA_ "SigType" SG_ 2633925118 EngFuelValve1Pos 1;
BA_ "SPN" SG_ 2633925118 EngFuelFlowRate2 1441;
BA_ "SigType" SG_ 2633925118 EngFuelFlowRate2 1;
BA_ "SPN" SG_ 2633925118 EngFuelFlowRate1 1440;
BA_ "SigType" SG_ 2633925118 EngFuelFlowRate1 1;
BA_ "SPN" SG_ 2633937662 EngFuelSpecificGravity 1389;
BA_ "SigType" SG_ 2633937662 EngFuelSpecificGravity 1;
BA_ "SPN" SG_ 2633937662 TripAverageFuelRate 1031;
BA_ "SigType" SG_ 2633937662 TripAverageFuelRate 1;
BA_ "SPN" SG_ 2633937662 TotalEngPTOGovernorFuelUsed 1030;
BA_ "SigType" SG_ 2633937662 TotalEngPTOGovernorFuelUsed 1;
BA_ "SPN" SG_ 2566804990 FuelEnergyContent 4245;
BA_ "SigType" SG_ 2566804990 FuelEnergyContent 1;
BA_ "SPN" SG_ 2566804990 ReferenceEngGasMassFlowRate 5684;
BA_ "SigType" SG_ 2566804990 ReferenceEngGasMassFlowRate 1;
BA_ "SPN" SG_ 2566804990 SpecificHeatRatio 1767;
BA_ "SigType" SG_ 2566804990 SpecificHeatRatio 1;
BA_ "SPN" SG_ 2633936894 TotalFuelUsed 1040;
BA_ "SigType" SG_ 2633936894 TotalFuelUsed 1;
BA_ "SPN" SG_ 2633936894 TripFuel 1039;
BA_ "SigType" SG_ 2633936894 TripFuel 1;
BA_ "SPN" SG_ 2566757630 SensorSupplyVoltage8 5126;
BA_ "SigType" SG_ 2566757630 SensorSupplyVoltage8 1;
BA_ "SPN" SG_ 2566757630 SensorSupplyVoltage7 5125;
BA_ "SigType" SG_ 2566757630 SensorSupplyVoltage7 1;
BA_ "SPN" SG_ 2566757630 SensorSupplyVoltage6 3514;
BA_ "SigType" SG_ 2566757630 SensorSupplyVoltage6 1;
BA_ "SPN" SG_ 2566757630 SensorSupplyVoltage5 3513;
BA_ "SigType" SG_ 2566757630 SensorSupplyVoltage5 1;
BA_ "SPN" SG_ 2566757886 SensorSupplyVoltage4 3512;
BA_ "SigType" SG_ 2566757886 SensorSupplyVoltage4 1;
BA_ "SPN" SG_ 2566757886 SensorSupplyVoltage3 3511;
BA_ "SigType" SG_ 2566757886 SensorSupplyVoltage3 1;
BA_ "SPN" SG_ 2566757886 SensorSupplyVoltage2 3510;
BA_ "SigType" SG_ 2566757886 SensorSupplyVoltage2 1;
BA_ "SPN" SG_ 2566757886 SensorSupplyVoltage1 3509;
BA_ "SigType" SG_ 2566757886 SensorSupplyVoltage1 1;
BA_ "SPN" SG_ 2566759678 AtLeastOnePTOEngaged 3948;
BA_ "SigType" SG_ 2566759678 AtLeastOnePTOEngaged 5;
BA_ "SPN" SG_ 2566759678 EnggmntSttsPTOEngAccessoryDrive2 3947;
BA_ "SigType" SG_ 2566759678 EnggmntSttsPTOEngAccessoryDrive2 5;
BA_ "SPN" SG_ 2566759678 EnggmntSttsPTOEngAccessoryDrive1 3944;
BA_ "SigType" SG_ 2566759678 EnggmntSttsPTOEngAccessoryDrive1 5;
BA_ "SPN" SG_ 2566759678 EngagementStatusPTOEngFlywheel 3941;
BA_ "SigType" SG_ 2566759678 EngagementStatusPTOEngFlywheel 5;
BA_ "SPN" SG_ 2566759678 EnggmntStatusTransInputShaftPTO1 3460;
BA_ "SigType" SG_ 2566759678 EnggmntStatusTransInputShaftPTO1 5;
BA_ "SPN" SG_ 2566759678 EnggmntStatusTransInputShaftPTO2 3461;
BA_ "SigType" SG_ 2566759678 EnggmntStatusTransInputShaftPTO2 5;
BA_ "SPN" SG_ 2566759678 EnggmntStatusTransOutputShaftPTO 3462;
BA_ "SigType" SG_ 2566759678 EnggmntStatusTransOutputShaftPTO 5;
BA_ "SPN" SG_ 2566759678 EnggmntSttsTrnsfrCsOtputShaftPTO 3463;
BA_ "SigType" SG_ 2566759678 EnggmntSttsTrnsfrCsOtputShaftPTO 5;
BA_ "SPN" SG_ 2566759678 EnggmntCnsntPTOEngAccssoryDrive2 3946;
BA_ "SigType" SG_ 2566759678 EnggmntCnsntPTOEngAccssoryDrive2 5;
BA_ "SPN" SG_ 2566759678 EnggmntCnsntPTOEngAccssoryDrive1 3943;
BA_ "SigType" SG_ 2566759678 EnggmntCnsntPTOEngAccssoryDrive1 5;
BA_ "SPN" SG_ 2566759678 EngagementConsentPTOEngFlywheel 3940;
BA_ "SigType" SG_ 2566759678 EngagementConsentPTOEngFlywheel 5;
BA_ "SPN" SG_ 2566759678 EnggmntCnsentTransInputShaftPTO1 3456;
BA_ "SigType" SG_ 2566759678 EnggmntCnsentTransInputShaftPTO1 5;
BA_ "SPN" SG_ 2566759678 EnggmntCnsentTransInputShaftPTO2 3457;
BA_ "SigType" SG_ 2566759678 EnggmntCnsentTransInputShaftPTO2 5;
BA_ "SPN" SG_ 2566759678 EnggmntCnsentTransOutputShaftPTO 3458;
BA_ "SigType" SG_ 2566759678 EnggmntCnsentTransOutputShaftPTO 5;
BA_ "SPN" SG_ 2566759678 EnggmntCnsntTrnsfrCsOtptShaftPTO 3459;
BA_ "SigType" SG_ 2566759678 EnggmntCnsntTrnsfrCsOtptShaftPTO 5;
BA_ "SPN" SG_ 2566759678 EnbleSwitchPTOEngAccessoryDrive2 3945;
BA_ "SigType" SG_ 2566759678 EnbleSwitchPTOEngAccessoryDrive2 5;
BA_ "SPN" SG_ 2566759678 EnbleSwitchPTOEngAccessoryDrive1 3942;
BA_ "SigType" SG_ 2566759678 EnbleSwitchPTOEngAccessoryDrive1 5;
BA_ "SPN" SG_ 2566759678 EnableSwitchPTOEngFlywheel 3939;
BA_ "SigType" SG_ 2566759678 EnableSwitchPTOEngFlywheel 5;
BA_ "SPN" SG_ 2566759678 EnableSwitchTransInputShaftPTO1 3452;
BA_ "SigType" SG_ 2566759678 EnableSwitchTransInputShaftPTO1 5;
BA_ "SPN" SG_ 2566759678 EnableSwitchTransInputShaftPTO2 3453;
BA_ "SigType" SG_ 2566759678 EnableSwitchTransInputShaftPTO2 5;
BA_ "SPN" SG_ 2566759678 EnableSwitchTransOutputShaftPTO 3454;
BA_ "SigType" SG_ 2566759678 EnableSwitchTransOutputShaftPTO 5;
BA_ "SPN" SG_ 2566759678 EnblSwtchTrnsfrCseOutputShaftPTO 3455;
BA_ "SigType" SG_ 2566759678 EnblSwtchTrnsfrCseOutputShaftPTO 5;
BA_ "SPN" SG_ 2432541438 EngFuelValve2OutletAbsPress 3469;
BA_ "SigType" SG_ 2432541438 EngFuelValve2OutletAbsPress 1;
BA_ "SPN" SG_ 2432541438 EngFuelTemp2 3468;
BA_ "SigType" SG_ 2432541438 EngFuelTemp2 1;
BA_ "SPN" SG_ 2432541438 EngGas2MassFlowRate 3467;
BA_ "SigType" SG_ 2432541438 EngGas2MassFlowRate 1;
BA_ "SPN" SG_ 2432541438 EngFuelValve2IntakeAbsPress 3466;
BA_ "SigType" SG_ 2432541438 EngFuelValve2IntakeAbsPress 1;
BA_ "SPN" SG_ 2566761214 EngChargeAirCoolerOutletPress 2631;
BA_ "SigType" SG_ 2566761214 EngChargeAirCoolerOutletPress 1;
BA_ "SPN" SG_ 2566761214 EngAftercoolerCoolantLevel 3676;
BA_ "SigType" SG_ 2566761214 EngAftercoolerCoolantLevel 1;
BA_ "SPN" SG_ 2566761214 EngIntercoolerCoolantLevel 3668;
BA_ "SigType" SG_ 2566761214 EngIntercoolerCoolantLevel 1;
BA_ "SPN" SG_ 2566761214 EngCentrifugalOilFilterSpeed 3343;
BA_ "SigType" SG_ 2566761214 EngCentrifugalOilFilterSpeed 1;
BA_ "SPN" SG_ 2566761214 EngCoolantPumpDiffPress 3342;
BA_ "SigType" SG_ 2566761214 EngCoolantPumpDiffPress 1;
BA_ "SPN" SG_ 2566761214 EngChargeAirCooler2IntakePress 3341;
BA_ "SigType" SG_ 2566761214 EngChargeAirCooler2IntakePress 1;
BA_ "SPN" SG_ 2566761214 EngChargeAirCooler1IntakePress 3340;
BA_ "SigType" SG_ 2566761214 EngChargeAirCooler1IntakePress 1;
BA_ "SPN" SG_ 2432541694 EngVriableGeometryTurboActuator1 641;
BA_ "SigType" SG_ 2432541694 EngVriableGeometryTurboActuator1 1;
BA_ "SPN" SG_ 2432541694 EngTrbCmprssrBypssActtr1TmpSttus 5368;
BA_ "SPN" SG_ 2432541694 EngTrbCmprssrBypssActtr1PrlmnryF 5367;
BA_ "SPN" SG_ 2432541694 EngTrbCmprssorBypassActuator2Cmd 5369;
BA_ "SigType" SG_ 2432541694 EngTrbCmprssorBypassActuator2Cmd 1;
BA_ "SPN" SG_ 2432541694 EngTrbCmprssorBypassActuator1Pos 3675;
BA_ "SigType" SG_ 2432541694 EngTrbCmprssorBypassActuator1Pos 1;
BA_ "SPN" SG_ 2432541694 EngTrbCmprssorBypassActuator1Cmd 3470;
BA_ "SigType" SG_ 2432541694 EngTrbCmprssorBypassActuator1Cmd 1;
BA_ "SPN" SG_ 2432541694 EngDsrdTrbCmprssrBypssActtor1Pos 5366;
BA_ "SigType" SG_ 2432541694 EngDsrdTrbCmprssrBypssActtor1Pos 1;
BA_ "SPN" SG_ 2566759934 EnableStatusOfDoor10 3441;
BA_ "SigType" SG_ 2566759934 EnableStatusOfDoor10 4;
BA_ "SPN" SG_ 2566759934 OpenStatusOfDoor10 3440;
BA_ "SigType" SG_ 2566759934 OpenStatusOfDoor10 4;
BA_ "SPN" SG_ 2566759934 LockStatusOfDoor10 3439;
BA_ "SigType" SG_ 2566759934 LockStatusOfDoor10 4;
BA_ "SPN" SG_ 2566759934 EnableStatusOfDoor9 3438;
BA_ "SigType" SG_ 2566759934 EnableStatusOfDoor9 4;
BA_ "SPN" SG_ 2566759934 OpenStatusOfDoor9 3437;
BA_ "SigType" SG_ 2566759934 OpenStatusOfDoor9 4;
BA_ "SPN" SG_ 2566759934 LockStatusOfDoor9 3436;
BA_ "SigType" SG_ 2566759934 LockStatusOfDoor9 4;
BA_ "SPN" SG_ 2566759934 EnableStatusOfDoor8 3435;
BA_ "SigType" SG_ 2566759934 EnableStatusOfDoor8 4;
BA_ "SPN" SG_ 2566759934 OpenStatusOfDoor8 3434;
BA_ "SigType" SG_ 2566759934 OpenStatusOfDoor8 4;
BA_ "SPN" SG_ 2566759934 LockStatusOfDoor8 3433;
BA_ "SigType" SG_ 2566759934 LockStatusOfDoor8 4;
BA_ "SPN" SG_ 2566759934 EnableStatusOfDoor7 3432;
BA_ "SigType" SG_ 2566759934 EnableStatusOfDoor7 4;
BA_ "SPN" SG_ 2566759934 OpenStatusOfDoor7 3431;
BA_ "SigType" SG_ 2566759934 OpenStatusOfDoor7 4;
BA_ "SPN" SG_ 2566759934 LockStatusOfDoor7 3430;
BA_ "SigType" SG_ 2566759934 LockStatusOfDoor7 4;
BA_ "SPN" SG_ 2566759934 EnableStatusOfDoor6 3429;
BA_ "SigType" SG_ 2566759934 EnableStatusOfDoor6 4;
BA_ "SPN" SG_ 2566759934 OpenStatusOfDoor6 3428;
BA_ "SigType" SG_ 2566759934 OpenStatusOfDoor6 4;
BA_ "SPN" SG_ 2566759934 LockStatusOfDoor6 3427;
BA_ "SigType" SG_ 2566759934 LockStatusOfDoor6 4;
BA_ "SPN" SG_ 2566759934 EnableStatusOfDoor5 3426;
BA_ "SigType" SG_ 2566759934 EnableStatusOfDoor5 4;
BA_ "SPN" SG_ 2566759934 OpenStatusOfDoor5 3425;
BA_ "SigType" SG_ 2566759934 OpenStatusOfDoor5 4;
BA_ "SPN" SG_ 2566759934 LockStatusOfDoor5 3424;
BA_ "SigType" SG_ 2566759934 LockStatusOfDoor5 4;
BA_ "SPN" SG_ 2566759934 EnableStatusOfDoor4 3423;
BA_ "SigType" SG_ 2566759934 EnableStatusOfDoor4 4;
BA_ "SPN" SG_ 2566759934 OpenStatusOfDoor4 3422;
BA_ "SigType" SG_ 2566759934 OpenStatusOfDoor4 4;
BA_ "SPN" SG_ 2566759934 LockStatusOfDoor4 3421;
BA_ "SigType" SG_ 2566759934 LockStatusOfDoor4 4;
BA_ "SPN" SG_ 2566759934 EnableStatusOfDoor3 3420;
BA_ "SigType" SG_ 2566759934 EnableStatusOfDoor3 4;
BA_ "SPN" SG_ 2566759934 OpenStatusOfDoor3 3419;
BA_ "SigType" SG_ 2566759934 OpenStatusOfDoor3 4;
BA_ "SPN" SG_ 2566759934 LockStatusOfDoor3 3418;
BA_ "SigType" SG_ 2566759934 LockStatusOfDoor3 4;
BA_ "SPN" SG_ 2566759934 EnableStatusOfDoor2 3417;
BA_ "SigType" SG_ 2566759934 EnableStatusOfDoor2 4;
BA_ "SPN" SG_ 2566759934 OpenStatusOfDoor2 3416;
BA_ "SigType" SG_ 2566759934 OpenStatusOfDoor2 4;
BA_ "SPN" SG_ 2566759934 LockStatusOfDoor2 3415;
BA_ "SigType" SG_ 2566759934 LockStatusOfDoor2 4;
BA_ "SPN" SG_ 2566759934 EnableStatusOfDoor1 3414;
BA_ "SigType" SG_ 2566759934 EnableStatusOfDoor1 4;
BA_ "SPN" SG_ 2566759934 OpenStatusOfDoor1 3413;
BA_ "SigType" SG_ 2566759934 OpenStatusOfDoor1 4;
BA_ "SPN" SG_ 2566759934 LockStatusOfDoor1 3412;
BA_ "SigType" SG_ 2566759934 LockStatusOfDoor1 4;
BA_ "SPN" SG_ 2566757374 DieselExhaustFluidSpeedOfSound 7346;
BA_ "SigType" SG_ 2566757374 DieselExhaustFluidSpeedOfSound 1;
BA_ "SPN" SG_ 2566757374 Property 3521;
BA_ "SPN" SG_ 2566757374 PropertiesPreliminaryFMI 3520;
BA_ "SPN" SG_ 2566757374 Temp2PreliminaryFMI 3519;
BA_ "SPN" SG_ 2566757374 Conductivity 3518;
BA_ "SigType" SG_ 2566757374 Conductivity 1;
BA_ "SPN" SG_ 2566757374 Concentration 3516;
BA_ "SigType" SG_ 2566757374 Concentration 1;
BA_ "SPN" SG_ 2566757374 Temp2 3515;
BA_ "SigType" SG_ 2566757374 Temp2 1;
BA_ "SPN" SG_ 2364546302 RqdGnrtrAvrgLneLineACRMSVoltage 3386;
BA_ "SigType" SG_ 2364546302 RqdGnrtrAvrgLneLineACRMSVoltage 1;
BA_ "SPN" SG_ 2431654654 EngFuelActuator2CtrlCmd 1244;
BA_ "SigType" SG_ 2431654654 EngFuelActuator2CtrlCmd 1;
BA_ "SPN" SG_ 2431654654 EngFuelActuator1CtrlCmd 633;
BA_ "SigType" SG_ 2431654654 EngFuelActuator1CtrlCmd 1;
BA_ "SPN" SG_ 2431654654 EngThrottleActuator2CtrlCmd 3465;
BA_ "SigType" SG_ 2431654654 EngThrottleActuator2CtrlCmd 1;
BA_ "SPN" SG_ 2431654654 EngThrottleActuator1CtrlCmd 3464;
BA_ "SigType" SG_ 2431654654 EngThrottleActuator1CtrlCmd 1;
BA_ "SPN" SG_ 2364545534 EngCyl24KnockLevel 1375;
BA_ "SigType" SG_ 2364545534 EngCyl24KnockLevel 1;
BA_ "SPN" SG_ 2364545534 EngCyl23KnockLevel 1374;
BA_ "SigType" SG_ 2364545534 EngCyl23KnockLevel 1;
BA_ "SPN" SG_ 2364545534 EngCyl22KnockLevel 1373;
BA_ "SigType" SG_ 2364545534 EngCyl22KnockLevel 1;
BA_ "SPN" SG_ 2364545534 EngCyl21KnockLevel 1372;
BA_ "SigType" SG_ 2364545534 EngCyl21KnockLevel 1;
BA_ "SPN" SG_ 2364545534 EngCyl20KnockLevel 1371;
BA_ "SigType" SG_ 2364545534 EngCyl20KnockLevel 1;
BA_ "SPN" SG_ 2364545534 EngCyl19KnockLevel 1370;
BA_ "SigType" SG_ 2364545534 EngCyl19KnockLevel 1;
BA_ "SPN" SG_ 2364545534 EngCyl18KnockLevel 1369;
BA_ "SigType" SG_ 2364545534 EngCyl18KnockLevel 1;
BA_ "SPN" SG_ 2364545534 EngCyl17KnockLevel 1368;
BA_ "SigType" SG_ 2364545534 EngCyl17KnockLevel 1;
BA_ "SPN" SG_ 2364545278 EngCyl16KnockLevel 1367;
BA_ "SigType" SG_ 2364545278 EngCyl16KnockLevel 1;
BA_ "SPN" SG_ 2364545278 EngCyl15KnockLevel 1366;
BA_ "SigType" SG_ 2364545278 EngCyl15KnockLevel 1;
BA_ "SPN" SG_ 2364545278 EngCyl14KnockLevel 1365;
BA_ "SigType" SG_ 2364545278 EngCyl14KnockLevel 1;
BA_ "SPN" SG_ 2364545278 EngCyl13KnockLevel 1364;
BA_ "SigType" SG_ 2364545278 EngCyl13KnockLevel 1;
BA_ "SPN" SG_ 2364545278 EngCyl12KnockLevel 1363;
BA_ "SigType" SG_ 2364545278 EngCyl12KnockLevel 1;
BA_ "SPN" SG_ 2364545278 EngCyl11KnockLevel 1362;
BA_ "SigType" SG_ 2364545278 EngCyl11KnockLevel 1;
BA_ "SPN" SG_ 2364545278 EngCyl10KnockLevel 1361;
BA_ "SigType" SG_ 2364545278 EngCyl10KnockLevel 1;
BA_ "SPN" SG_ 2364545278 EngCyl9KnockLevel 1360;
BA_ "SigType" SG_ 2364545278 EngCyl9KnockLevel 1;
BA_ "SPN" SG_ 2364545022 EngCyl8KnockLevel 1359;
BA_ "SigType" SG_ 2364545022 EngCyl8KnockLevel 1;
BA_ "SPN" SG_ 2364545022 EngCyl7KnockLevel 1358;
BA_ "SigType" SG_ 2364545022 EngCyl7KnockLevel 1;
BA_ "SPN" SG_ 2364545022 EngCyl6KnockLevel 1357;
BA_ "SigType" SG_ 2364545022 EngCyl6KnockLevel 1;
BA_ "SPN" SG_ 2364545022 EngCyl5KnockLevel 1356;
BA_ "SigType" SG_ 2364545022 EngCyl5KnockLevel 1;
BA_ "SPN" SG_ 2364545022 EngCyl4KnockLevel 1355;
BA_ "SigType" SG_ 2364545022 EngCyl4KnockLevel 1;
BA_ "SPN" SG_ 2364545022 EngCyl3KnockLevel 1354;
BA_ "SigType" SG_ 2364545022 EngCyl3KnockLevel 1;
BA_ "SPN" SG_ 2364545022 EngCyl2KnockLevel 1353;
BA_ "SigType" SG_ 2364545022 EngCyl2KnockLevel 1;
BA_ "SPN" SG_ 2364545022 EngCyl1KnockLevel 1352;
BA_ "SigType" SG_ 2364545022 EngCyl1KnockLevel 1;
BA_ "SPN" SG_ 2364544766 EngCyl24CombustionStatus 3410;
BA_ "SigType" SG_ 2364544766 EngCyl24CombustionStatus 5;
BA_ "SPN" SG_ 2364544766 EngCyl23CombustionStatus 3409;
BA_ "SigType" SG_ 2364544766 EngCyl23CombustionStatus 5;
BA_ "SPN" SG_ 2364544766 EngCyl22CombustionStatus 3408;
BA_ "SigType" SG_ 2364544766 EngCyl22CombustionStatus 5;
BA_ "SPN" SG_ 2364544766 EngCyl21CombustionStatus 3407;
BA_ "SigType" SG_ 2364544766 EngCyl21CombustionStatus 5;
BA_ "SPN" SG_ 2364544766 EngCyl20CombustionStatus 3406;
BA_ "SigType" SG_ 2364544766 EngCyl20CombustionStatus 5;
BA_ "SPN" SG_ 2364544766 EngCyl19CombustionStatus 3405;
BA_ "SigType" SG_ 2364544766 EngCyl19CombustionStatus 5;
BA_ "SPN" SG_ 2364544766 EngCyl18CombustionStatus 3404;
BA_ "SigType" SG_ 2364544766 EngCyl18CombustionStatus 5;
BA_ "SPN" SG_ 2364544766 EngCyl17CombustionStatus 3403;
BA_ "SigType" SG_ 2364544766 EngCyl17CombustionStatus 5;
BA_ "SPN" SG_ 2364544766 EngCyl16CombustionStatus 3402;
BA_ "SigType" SG_ 2364544766 EngCyl16CombustionStatus 5;
BA_ "SPN" SG_ 2364544766 EngCyl15CombustionStatus 3401;
BA_ "SigType" SG_ 2364544766 EngCyl15CombustionStatus 5;
BA_ "SPN" SG_ 2364544766 EngCyl14CombustionStatus 3400;
BA_ "SigType" SG_ 2364544766 EngCyl14CombustionStatus 5;
BA_ "SPN" SG_ 2364544766 EngCyl13CombustionStatus 3399;
BA_ "SigType" SG_ 2364544766 EngCyl13CombustionStatus 5;
BA_ "SPN" SG_ 2364544766 EngCyl12CombustionStatus 3398;
BA_ "SigType" SG_ 2364544766 EngCyl12CombustionStatus 5;
BA_ "SPN" SG_ 2364544766 EngCyl11CombustionStatus 3397;
BA_ "SigType" SG_ 2364544766 EngCyl11CombustionStatus 5;
BA_ "SPN" SG_ 2364544766 EngCyl10CombustionStatus 3396;
BA_ "SigType" SG_ 2364544766 EngCyl10CombustionStatus 5;
BA_ "SPN" SG_ 2364544766 EngCyl9CombustionStatus 3395;
BA_ "SigType" SG_ 2364544766 EngCyl9CombustionStatus 5;
BA_ "SPN" SG_ 2364544766 EngCyl8CombustionStatus 3394;
BA_ "SigType" SG_ 2364544766 EngCyl8CombustionStatus 5;
BA_ "SPN" SG_ 2364544766 EngCyl7CombustionStatus 3393;
BA_ "SigType" SG_ 2364544766 EngCyl7CombustionStatus 5;
BA_ "SPN" SG_ 2364544766 EngCyl6CombustionStatus 3392;
BA_ "SigType" SG_ 2364544766 EngCyl6CombustionStatus 5;
BA_ "SPN" SG_ 2364544766 EngCyl5CombustionStatus 3391;
BA_ "SigType" SG_ 2364544766 EngCyl5CombustionStatus 5;
BA_ "SPN" SG_ 2364544766 EngCyl4CombustionStatus 3390;
BA_ "SigType" SG_ 2364544766 EngCyl4CombustionStatus 5;
BA_ "SPN" SG_ 2364544766 EngCyl3CombustionStatus 3389;
BA_ "SigType" SG_ 2364544766 EngCyl3CombustionStatus 5;
BA_ "SPN" SG_ 2364544766 EngCyl2CombustionStatus 3388;
BA_ "SigType" SG_ 2364544766 EngCyl2CombustionStatus 5;
BA_ "SPN" SG_ 2364544766 EngCyl1CombustionStatus 3387;
BA_ "SigType" SG_ 2364544766 EngCyl1CombustionStatus 5;
BA_ "SPN" SG_ 2364544510 RqGenOverallPowerFactorLagging 3385;
BA_ "SigType" SG_ 2364544510 RqGenOverallPowerFactorLagging 5;
BA_ "SPN" SG_ 2364544510 RqGeneratorOverallPowerFactor 3384;
BA_ "SigType" SG_ 2364544510 RqGeneratorOverallPowerFactor 1;
BA_ "SPN" SG_ 2364544510 RqGeneratorTotalACReactivePower 3383;
BA_ "SigType" SG_ 2364544510 RqGeneratorTotalACReactivePower 1;
BA_ "SPN" SG_ 2364544254 BladeRotationAngleFigureOfMerit 3332;
BA_ "SigType" SG_ 2364544254 BladeRotationAngleFigureOfMerit 5;
BA_ "SPN" SG_ 2364544254 RelativeBladeHeightFigureOfMerit 3367;
BA_ "SigType" SG_ 2364544254 RelativeBladeHeightFigureOfMerit 5;
BA_ "SPN" SG_ 2364544254 RltvBldHghtAndBldRttnAnglMsrmntL 3366;
BA_ "SigType" SG_ 2364544254 RltvBldHghtAndBldRttnAnglMsrmntL 1;
BA_ "SPN" SG_ 2364544254 BladeRotationAngle 3331;
BA_ "SigType" SG_ 2364544254 BladeRotationAngle 1;
BA_ "SPN" SG_ 2364544254 RelativeBladeHeight 3365;
BA_ "SigType" SG_ 2364544254 RelativeBladeHeight 1;
BA_ "SigType" SG_ 2550333182 BrakeLightSwitch 4;
BA_ "SigType" SG_ 2550333182 ASREngineControlActive 4;
BA_ "SigType" SG_ 2550333182 ASRBreakControlActive 4;
BA_ "SigType" SG_ 2550333182 VehicleRetarderCtrlActive 4;
BA_ "SigType" SG_ 2550333182 VehicleABSActive 4;
BA_ "SPN" SG_ 2566834686 RoadCurvature 1591;
BA_ "SigType" SG_ 2566834686 RoadCurvature 1;
BA_ "SigType" SG_ 2566834686 PneumaticControlLine 4;
BA_ "SigType" SG_ 2566834686 ABSOffroadRequest 4;
BA_ "SigType" SG_ 2566834686 TwoElCircuitsBrakeDemand 4;
BA_ "SigType" SG_ 2566834686 VehicleRetarderCtrlActive 4;
BA_ "SigType" SG_ 2550398718 ActualRetarderPercTorque 1;
BA_ "SigType" SG_ 2550398718 Wheel_BasedVehicleSpeed 1;
BA_ "SigType" SG_ 2550398718 SupplyLineBrakingRequest 4;
BA_ "SigType" SG_ 2550398718 VDCActive 4;
BA_ "SigType" SG_ 2550398718 AutomTowedVehBreakActive 4;
BA_ "SigType" SG_ 2550398718 VehicleServiceBrakeActive 4;
BA_ "SigType" SG_ 2550398718 VehicleRetarderCtrlActive 4;
BA_ "SigType" SG_ 2550398718 VehicleABSActive 4;
BA_ "SPN" SG_ 2566833406 ReferenceRetarderTorque 556;
BA_ "SigType" SG_ 2566833406 ReferenceRetarderTorque 1;
BA_ "SigType" SG_ 2566833406 SupplyLineBrakingRequest 4;
BA_ "SigType" SG_ 2566833406 LoadingRampApproachAssist 4;
BA_ "SigType" SG_ 2566833406 SpringBrakeEngaged 4;
BA_ "SigType" SG_ 2566833406 ElectrLoadPropFunc 4;
BA_ "SigType" SG_ 2566833406 SpringBrakeInstalled 4;
BA_ "SigType" SG_ 2566833406 ElecSupplyOfNonBrakingSys 4;
BA_ "SigType" SG_ 2566833406 AmberWarningSignalReq 4;
BA_ "SigType" SG_ 2566833406 RedWarningSignalRequest 4;
BA_ "SigType" SG_ 2566833406 VehicleElectrSupplySuff 4;
BA_ "SigType" SG_ 2566833406 AutomTowedVehBreakActive 4;
BA_ "SigType" SG_ 2566833406 VehicleServiceBrakeActive 4;
BA_ "SigType" SG_ 2566833406 VehicleRetarderCtrlActive 4;
BA_ "SigType" SG_ 2566833406 VehicleABSActive 4;
BA_ "SigType" SG_ 2566833918 VehiclePneumSupplySuff 4;
BA_ "SigType" SG_ 2566833918 BrakeTemperatureStatus 4;
BA_ "SigType" SG_ 2566833918 BrakeLiningSufficient 4;
BA_ "SigType" SG_ 2566833918 TyrePressureSufficient 4;
BA_ "SigType" SG_ 2565013246 ODDRequest 4;
BA_ "SigType" SG_ 2565013246 AntiTheftDeviceReq 4;
BA_ "SPN" SG_ 2566807038 MaxVehicleSpeedLimit 74;
BA_ "SigType" SG_ 2566807038 MaxVehicleSpeedLimit 1;
BA_ "SigType" SG_ 2566807550 VehicleSpeed 1;
BA_ "SigType" SG_ 2566807550 PercentLoadAtCurrentSpeed 1;
BA_ "SigType" SG_ 2566807550 EngineSpeed 1;
BA_ "SigType" SG_ 2566807550 ActualEngine_PercTorque 1;
BA_ "SigType" SG_ 2566807550 DriversDemandEngine_PercTorque 1;
BA_ "SigType" SG_ 2566807550 EngineRunning 4;
BA_ "SigType" SG_ 2566807550 EngineControlAllowed 4;
BA_ "SigType" SG_ 2566808062 ClutchIndptdPTOFeedback 4;
BA_ "SigType" SG_ 2566808062 AccelPedalPosition 1;
BA_ "SigType" SG_ 2566808062 AccelPedalLowIdleSwitch 4;
BA_ "SigType" SG_ 2566808062 StarterActive 4;
BA_ "SigType" SG_ 2566808062 PTOControlAllowed 4;
BA_ "SigType" SG_ 2566808062 SecEngineMtdPTOFeedback 4;
BA_ "SigType" SG_ 2566808062 FirstEngineMtdPTOFeedback 4;
BA_ "SigType" SG_ 2566808062 SecClutchDptdPTOFeedback 4;
BA_ "SigType" SG_ 2566808062 FirstClutchDpdtPTOFeedback 4;
BA_ "SigType" SG_ 2566808062 CurrentGear 1;
BA_ "SPN" SG_ 2566808062 PercentClutchSlip 522;
BA_ "SigType" SG_ 2566808062 PercentClutchSlip 1;
BA_ "SigType" SG_ 2566808574 ReferenceEngineTorque 1;
BA_ "SigType" SG_ 2566808574 FuelLevelWarning 4;
BA_ "SigType" SG_ 2566808574 EngineOilPressureWarning 4;
BA_ "SigType" SG_ 2566808574 EngineOilPressure 1;
BA_ "SPN" SG_ 2566808574 EngCoolantTemp 110;
BA_ "SigType" SG_ 2566808574 EngCoolantTemp 1;
BA_ "SigType" SG_ 2566808574 EngineOilTemperature 1;
BA_ "SigType" SG_ 2566809086 AmbientAirTemperature 1;
BA_ "SigType" SG_ 2566834430 AntiTheftDeviceStatus 4;
BA_ "SigType" SG_ 2566834430 ODDStatus 4;
BA_ "SigType" SG_ 2566808318 SecEngineMtdPTOSwitch 4;
BA_ "SigType" SG_ 2566808318 SecClutchDpdtPTOSwitch 4;
BA_ "SigType" SG_ 2566808318 FirstClutchDpdtPTOSwitch 4;
BA_ "SigType" SG_ 2566808318 OperatingPanelActive 4;
BA_ "SigType" SG_ 2566808318 RefusePackerStepSwitch 4;
BA_ "SigType" SG_ 2566808318 EngineStopSwitch 4;
BA_ "SigType" SG_ 2566808318 EngineStartSwitch 4;
BA_ "SigType" SG_ 2566808318 StarterLockoutSwitch 4;
BA_ "SigType" SG_ 2566808318 RqstedPercentClutchSlip 1;
BA_ "SigType" SG_ 2566808318 FirstEngineMtdPTOSwitch 4;
BA_ "SigType" SG_ 2566808318 ClutchIndpdtPTOSwitch 4;
BA_ "SigType" SG_ 2566808830 TrailerLeftSideMarkerLight 4;
BA_ "SigType" SG_ 2566808830 TrailerLeftReversingLight 4;
BA_ "SigType" SG_ 2566808830 TrailerLeftRearWidIndLight 4;
BA_ "SigType" SG_ 2566808830 TrailerLeftRearRegPltLight 4;
BA_ "SigType" SG_ 2566808830 TrailerLeftRearLight 4;
BA_ "SigType" SG_ 2566808830 TrailerLeftRearFogLight 4;
BA_ "SigType" SG_ 2566808830 TrailerLeftDirIndLight 4;
BA_ "SigType" SG_ 2566808830 TrailerLeftCrnMarkerLight 4;
BA_ "SigType" SG_ 2566808830 TrailerInteriorLight 4;
BA_ "SigType" SG_ 2566808830 TrailerWorkLamp 4;
BA_ "SigType" SG_ 2566808830 TrailerRotatingIdentLight 4;
BA_ "SigType" SG_ 2566808830 TrailerRightStopLight 4;
BA_ "SigType" SG_ 2566808830 TrailerRightSideMrkLight 4;
BA_ "SigType" SG_ 2566808830 TrailerRightReversingLight 4;
BA_ "SigType" SG_ 2566808830 TrailRightRearWidIndLight 4;
BA_ "SigType" SG_ 2566808830 TrailerRightRearRegPltLight 4;
BA_ "SigType" SG_ 2566808830 TrailerRightRearLight 4;
BA_ "SigType" SG_ 2566808830 TrailerRightRearFogLight 4;
BA_ "SigType" SG_ 2566808830 TrailerRightDirIndLight 4;
BA_ "SigType" SG_ 2566808830 TrailerRightCrnMarkerLight 4;
BA_ "SigType" SG_ 2566808830 TrailerRearWarningLight 4;
BA_ "SigType" SG_ 2566808830 TrailerLeftStopLight 4;
BA_ "SPN" SG_ 2565734142 NumberOfSA_NAMEPairs 5602;
BA_ "SPN" SG_ 2565734142 ToPort 5594;
BA_ "SPN" SG_ 2565734142 NetworkMessageControlByte 5592;
BA_ "SigType" SG_ 2565734142 NetworkMessageControlByte 1;
BA_ "SPN" SG_ 2565734142 FilterMode 5596;
BA_ "SigType" SG_ 2565734142 FilterMode 1;
BA_ "SPN" SG_ 2565734142 NIECUPort 5593;
BA_ "SPN" SG_ 2565734142 FromPort 5595;
BA_ "SigType" SG_ 2565144318 ParkingAndTrailerAirPress 1;
BA_ "SigType" SG_ 2565144318 AuxEquipSupplyPressure 1;
BA_ "SigType" SG_ 2565144318 StopLevelChangeReq 4;
BA_ "SigType" SG_ 2565144318 RampLevelStorageReq 4;
BA_ "SigType" SG_ 2565144318 LevelControlReq 4;
BA_ "SigType" SG_ 2565144318 RampLevelReq 4;
BA_ "SigType" SG_ 2565144318 SteeringAxleLockingReq 4;
BA_ "SigType" SG_ 2565144318 LiftAxle2PositionReq 4;
BA_ "SigType" SG_ 2565144318 LiftAxle1PositionReq 4;
BA_ "SigType" SG_ 2565144318 TractionHelpReq 4;
BA_ "SigType" SG_ 2565144318 LevelChangeReqRearAxle 4;
BA_ "SigType" SG_ 2565144318 LevelChangeReqFrontAxle 4;
BA_ "SigType" SG_ 2565144318 RideHeightRequest 4;
BA_ "SigType" SG_ 2565209854 LevelControl 4;
BA_ "SigType" SG_ 2565209854 RampLevel 4;
BA_ "SigType" SG_ 2565209854 NormalLevel 4;
BA_ "SigType" SG_ 2565209854 StopLevelChangeAcknowledge 4;
BA_ "SigType" SG_ 2565209854 LevelChangeRearAxle 4;
BA_ "SigType" SG_ 2565209854 LevelChangeFrontAxle 4;
BA_ "SigType" SG_ 2565209854 RampLevelStorage 4;
BA_ "SigType" SG_ 2565209854 SteeringAxleLocking 4;
BA_ "SPN" SG_ 2565209854 LiftAxle2Pos 1822;
BA_ "SigType" SG_ 2565209854 LiftAxle2Pos 4;
BA_ "SPN" SG_ 2565209854 LiftAxle1Pos 1743;
BA_ "SigType" SG_ 2565209854 LiftAxle1Pos 4;
BA_ "SigType" SG_ 2565209854 RampLevelPosition 4;
BA_ "SigType" SG_ 2565209854 TractionHelp 4;
BA_ "SigType" SG_ 2565209854 LevelCtrlSysRideHeightLevel 4;
VAL_ 2365485822 LandLevelingSystemEnableStatus 3 "Not available / Not installed" 2 "Error" 0 "Disabled" ;
VAL_ 2365485822 BladeCtrlModeRight 15 "Not Available" 14 "Error" 2 "Inactive Auto" 1 "Auto" 0 "Manual" ;
VAL_ 2365485822 BladeCtrlModeLeft 15 "Not Available" 14 "Error" 2 "Inactive Auto" 1 "Auto" 0 "Manual" ;
VAL_ 2365485822 BladeCtrlMode 2 "Inactive automatic mode" 1 "Automatic mode" 0 "Manual mode" ;
VAL_ 2566768894 EngOprtrPrmryIntrmdtSpdSlctState 15 "not available" 14 "SAE reserved" 1 "thru 1101" 0 "Control state is ISC functionality is not requested" ;
VAL_ 2566769406 EngOprtrPrmryIntrmdteSpeedSelect 15 "not available" 14 "error condition" 1 "thru 1101" 0 "indicates that the ISC functionality is not requested" ;
VAL_ 2566811134 ADRCompliantHeaterInstallation 3 "Not Available" 2 "Error" 1 "Heater installation is ADR compliant" 0 "Heater installation is not ADR compliant" ;
VAL_ 2566811134 CabHeatingZone 3 "Not available" 2 "Reserved" 1 "Cab heating zone on" 0 "Cab heating zone off" ;
VAL_ 2566811134 EngHeatingZone 3 "Not available" 2 "Reserved" 1 "Engine heating zone on" 0 "Engine heating zone off" ;
VAL_ 2566811134 CabVentilation 3 "Not available" 2 "Reserved" 1 "Cab is ventilated" 0 "Cab not ventilated" ;
VAL_ 2566811134 AuxHeaterWaterPumpStatus 3 "Not available" 2 "Reserved" 1 "Water Pump is  running" 0 "Water Pump is not running" ;
VAL_ 2566811134 AuxHeaterMode 15 "Not available" 14 "Error" 8 "Heater Locked" 7 "Diagnose Active" 6 "Heater Stopping" 5 "Heater Starting" 4 "Heater pump up-keep  " 3 "Normal mode" 2 "Economy mode" 1 "Off due to ADR per European Regulations for Transport of hazardous materials" 0 "Heater not active" ;
VAL_ 2565867774 FireApparatusPumpEngagement 3 "Not available or not installed" 2 "Error" 1 "Pump engaged" 0 "Pump not engaged" ;
VAL_ 2565867774 HydPressGovernorPresetSwitch 3 "Not available" 2 "Error" 1 "Preset Switch Active" 0 "Preset Switch Inactive" ;
VAL_ 2565867774 HydPressGovernorIncreaseSwitch 3 "Not available" 2 "Error" 1 "Increase Switch Active" 0 "Increase Switch Inactive" ;
VAL_ 2565867774 HydPressGovernorDecreaseSwitch 3 "Not available" 2 "Error" 1 "Decrease Switch Active" 0 "Decrease Switch Inactive" ;
VAL_ 2565867774 HydPressGovernorIdleSwitch 3 "Not available" 2 "Error" 1 "Idle Switch Active" 0 "Idle Switch Inactive" ;
VAL_ 2565867774 FireApparatusOkayToPumpInterlock 3 "Not Available" 2 "Error" 1 "Okay to Pump Interlock Active" 0 "Okay to Pump Interlock Inactive" ;
VAL_ 2565867774 EngHydPressGovernorSwitch 3 "Not Available" 2 "Error Indicator" 1 "Pressure Mode Active" 0 "Pressure Mode Inactive" ;
VAL_ 2565867774 EngHydPressGovernorModeIndicator 3 "Not Available" 2 "Error Indicator" 1 "Enabled" 0 "Disabled" ;
VAL_ 2365449982 HydBrakeFluidLevelSwitch 3 "Not available" 2 "Error indicator" 1 "Fluid level is sufficient" 0 "Fluid level is not sufficient" ;
VAL_ 2365449982 HydBrakeSystemAudibleWarningCmd 3 "Don't care" 2 "Reserved" 1 "Audible warning on" 0 "Audible warning off" ;
VAL_ 2365449982 HydBrakePressSupplyStateCircuit2 3 "Not available" 2 "Error indicator" 1 "Supply is reliable" 0 "Supply is not reliable" ;
VAL_ 2365449982 HydBrakePressSupplyStateCircuit1 3 "Not available" 2 "Error indicator" 1 "Supply is reliable" 0 "Supply is not reliable" ;
VAL_ 2365449982 HydBrkePressWarningStateCircuit2 3 "Not available" 2 "Error indicator" 1 "Pressure level below warning level" 0 "Pressure level sufficient" ;
VAL_ 2365449982 HydBrkePressWarningStateCircuit1 3 "Not available" 2 "Error indicator" 1 "Pressure level below warning level" 0 "Pressure level sufficient" ;
VAL_ 2566759678 AtLeastOnePTOEngaged 3 "Not available" 2 "Error" 1 "At least one PTO drive is engaged" 0 "No PTO drive is engaged" ;
VAL_ 2566759678 EnggmntSttsPTOEngAccessoryDrive2 3 "Not available" 2 "Error" 1 "Drive engaged" 0 "Drive not engaged" ;
VAL_ 2566759678 EnggmntSttsPTOEngAccessoryDrive1 3 "Not available" 2 "Error" 1 "Drive engaged" 0 "Drive not engaged" ;
VAL_ 2566759678 EngagementStatusPTOEngFlywheel 3 "Not available" 2 "Error" 1 "Drive engaged" 0 "Drive not engaged" ;
VAL_ 2566759678 EnggmntStatusTransInputShaftPTO1 3 "Not available" 2 "Error" 1 "Drive is engaged" 0 "Drive not engaged" ;
VAL_ 2566759678 EnggmntStatusTransInputShaftPTO2 3 "Not available" 2 "Error" 1 "Drive is engaged" 0 "Drive not engaged" ;
VAL_ 2566759678 EnggmntStatusTransOutputShaftPTO 3 "Not available" 2 "Error" 1 "Drive is engaged" 0 "Drive not engaged" ;
VAL_ 2566759678 EnggmntSttsTrnsfrCsOtputShaftPTO 3 "Not available" 2 "Error" 1 "Drive is engaged" 0 "Drive not engaged" ;
VAL_ 2566759678 EnggmntCnsntPTOEngAccssoryDrive2 3 "Not available" 2 "Error" 1 "Consent given" 0 "Consent not given" ;
VAL_ 2566759678 EnggmntCnsntPTOEngAccssoryDrive1 3 "Not available" 2 "Error" 1 "Consent given" 0 "Consent not given" ;
VAL_ 2566759678 EngagementConsentPTOEngFlywheel 3 "Not available" 2 "Error" 1 "Consent given" 0 "Consent not given" ;
VAL_ 2566759678 EnggmntCnsentTransInputShaftPTO1 3 "Not available" 2 "Error" 1 "Consent given" 0 "Consent not given" ;
VAL_ 2566759678 EnggmntCnsentTransInputShaftPTO2 3 "Not available" 2 "Error" 1 "Consent given" 0 "Consent not given" ;
VAL_ 2566759678 EnggmntCnsentTransOutputShaftPTO 3 "Not available" 2 "Error" 1 "Consent given" 0 "Consent not given" ;
VAL_ 2566759678 EnggmntCnsntTrnsfrCsOtptShaftPTO 3 "Not available" 2 "Error" 1 "Consent given" 0 "Consent not given" ;
VAL_ 2566759678 EnbleSwitchPTOEngAccessoryDrive2 3 "Not available" 2 "Error" 1 "Enable switch on" 0 "Enable switch off" ;
VAL_ 2566759678 EnbleSwitchPTOEngAccessoryDrive1 3 "Not available" 2 "Error" 1 "Enable switch on" 0 "Enable switch off" ;
VAL_ 2566759678 EnableSwitchPTOEngFlywheel 3 "Not available" 2 "Error" 1 "Enable switch on" 0 "Enable switch off" ;
VAL_ 2566759678 EnableSwitchTransInputShaftPTO1 3 "Not available" 2 "Error" 1 "Enable switch on" 0 "Enable switch off" ;
VAL_ 2566759678 EnableSwitchTransInputShaftPTO2 3 "Not available" 2 "Error" 1 "Enable switch on" 0 "Enable switch off" ;
VAL_ 2566759678 EnableSwitchTransOutputShaftPTO 3 "Not available" 2 "Error" 1 "Enable switch on" 0 "Enable switch off" ;
VAL_ 2566759678 EnblSwtchTrnsfrCseOutputShaftPTO 3 "Not available" 2 "Error" 1 "Enable switch on" 0 "Enable switch off" ;
VAL_ 2432541694 EngTrbCmprssrBypssActtr1TmpSttus 7 "Not available" 6 "Error" 5 "Not Defined" 4 "Low Most severe" 3 "Low Least severe" 2 "In Range" 1 "High Least severe" 0 "High Most severe" ;
VAL_ 2566759934 EnableStatusOfDoor10 3 "not available" 2 "error" 1 "door enabled" 0 "door disabled" ;
VAL_ 2566759934 OpenStatusOfDoor10 3 "not available" 2 "error" 1 "door opened" 0 "door closed" ;
VAL_ 2566759934 LockStatusOfDoor10 3 "not available" 2 "error" 1 "locked" 0 "unlocked" ;
VAL_ 2566759934 EnableStatusOfDoor9 3 "not available" 2 "error" 1 "door enabled" 0 "door disabled" ;
VAL_ 2566759934 OpenStatusOfDoor9 3 "not available" 2 "error" 1 "door opened" 0 "door closed" ;
VAL_ 2566759934 LockStatusOfDoor9 3 "not available" 2 "error" 1 "locked" 0 "unlocked" ;
VAL_ 2566759934 EnableStatusOfDoor8 3 "not available" 2 "error" 1 "door enabled" 0 "door disabled" ;
VAL_ 2566759934 OpenStatusOfDoor8 3 "not available" 2 "error" 1 "door opened" 0 "door closed" ;
VAL_ 2566759934 LockStatusOfDoor8 3 "not available" 2 "error" 1 "locked" 0 "unlocked" ;
VAL_ 2566759934 EnableStatusOfDoor7 3 "not available" 2 "error" 1 "door enabled" 0 "door disabled" ;
VAL_ 2566759934 OpenStatusOfDoor7 3 "not available" 2 "error" 1 "door opened" 0 "door closed" ;
VAL_ 2566759934 LockStatusOfDoor7 3 "not available" 2 "error" 1 "locked" 0 "unlocked" ;
VAL_ 2566759934 EnableStatusOfDoor6 3 "not available" 2 "error" 1 "door enabled" 0 "door disabled" ;
VAL_ 2566759934 OpenStatusOfDoor6 3 "not available" 2 "error" 1 "door opened" 0 "door closed" ;
VAL_ 2566759934 LockStatusOfDoor6 3 "not available" 2 "error" 1 "locked" 0 "unlocked" ;
VAL_ 2566759934 EnableStatusOfDoor5 3 "not available" 2 "error" 1 "door enabled" 0 "door disabled" ;
VAL_ 2566759934 OpenStatusOfDoor5 3 "not available" 2 "error" 1 "door opened" 0 "door closed" ;
VAL_ 2566759934 LockStatusOfDoor5 3 "not available" 2 "error" 1 "locked" 0 "unlocked" ;
VAL_ 2566759934 EnableStatusOfDoor4 3 "not available" 2 "error" 1 "door enabled" 0 "door disabled" ;
VAL_ 2566759934 OpenStatusOfDoor4 3 "not available" 2 "error" 1 "door opened" 0 "door closed" ;
VAL_ 2566759934 LockStatusOfDoor4 3 "not available" 2 "error" 1 "locked" 0 "unlocked" ;
VAL_ 2566759934 EnableStatusOfDoor3 3 "not available" 2 "error" 1 "door enabled" 0 "door disabled" ;
VAL_ 2566759934 OpenStatusOfDoor3 3 "not available" 2 "error" 1 "door opened" 0 "door closed" ;
VAL_ 2566759934 LockStatusOfDoor3 3 "not available" 2 "error" 1 "locked" 0 "unlocked" ;
VAL_ 2566759934 EnableStatusOfDoor2 0 "door disabled" 3 "not available" 2 "error" 1 "door enabled" ;
VAL_ 2566759934 OpenStatusOfDoor2 3 "not available" 2 "error" 1 "door opened" 0 "door closed" ;
VAL_ 2566759934 LockStatusOfDoor2 3 "not available" 2 "error" 1 "locked" 0 "unlocked" ;
VAL_ 2566759934 EnableStatusOfDoor1 3 "not available" 2 "error" 1 "door enabled" 0 "door disabled" ;
VAL_ 2566759934 OpenStatusOfDoor1 3 "not available" 2 "error" 1 "door opened" 0 "door closed" ;
VAL_ 2566759934 LockStatusOfDoor1 3 "not available" 2 "error" 1 "locked" 0 "unlocked" ;
VAL_ 2566757374 Property 15 "Not available" 14 "Error with diesel exhaust fluid property detection" 13 "Not able to determine fluid property" 12 "Diesel exhaust fluid" 3 "Diesel exhaust fluid is proper mixture" 2 "Fluid is diesel" 1 "Urea concentration too low" 0 "Urea concentration too high" ;
VAL_ 2364544766 EngCyl24CombustionStatus 3 "Not available" 2 "Error" 1 "Combustion exists" 0 "No combustion" ;
VAL_ 2364544766 EngCyl23CombustionStatus 3 "Not available" 2 "Error" 1 "Combustion exists" 0 "No combustion" ;
VAL_ 2364544766 EngCyl22CombustionStatus 3 "Not available" 2 "Error" 1 "Combustion exists" 0 "No combustion" ;
VAL_ 2364544766 EngCyl21CombustionStatus 3 "Not available" 2 "Error" 1 "Combustion exists" 0 "No combustion" ;
VAL_ 2364544766 EngCyl20CombustionStatus 3 "Not available" 2 "Error" 1 "Combustion exists" 0 "No combustion" ;
VAL_ 2364544766 EngCyl19CombustionStatus 3 "Not available" 2 "Error" 1 "Combustion exists" 0 "No combustion" ;
VAL_ 2364544766 EngCyl18CombustionStatus 3 "Not available" 2 "Error" 1 "Combustion exists" 0 "No combustion" ;
VAL_ 2364544766 EngCyl17CombustionStatus 3 "Not available" 2 "Error" 1 "Combustion exists" 0 "No combustion" ;
VAL_ 2364544766 EngCyl16CombustionStatus 3 "Not available" 2 "Error" 1 "Combustion exists" 0 "No combustion" ;
VAL_ 2364544766 EngCyl15CombustionStatus 3 "Not available" 2 "Error" 1 "Combustion exists" 0 "No combustion" ;
VAL_ 2364544766 EngCyl14CombustionStatus 3 "Not available" 2 "Error" 1 "Combustion exists" 0 "No combustion" ;
VAL_ 2364544766 EngCyl13CombustionStatus 3 "Not available" 2 "Error" 1 "Combustion exists" 0 "No combustion" ;
VAL_ 2364544766 EngCyl12CombustionStatus 3 "Not available" 2 "Error" 1 "Combustion exists" 0 "No combustion" ;
VAL_ 2364544766 EngCyl11CombustionStatus 3 "Not available" 2 "Error" 1 "Combustion exists" 0 "No combustion" ;
VAL_ 2364544766 EngCyl10CombustionStatus 3 "Not available" 2 "Error" 1 "Combustion exists" 0 "No combustion" ;
VAL_ 2364544766 EngCyl9CombustionStatus 3 "Not available" 2 "Error" 1 "Combustion exists" 0 "No combustion" ;
VAL_ 2364544766 EngCyl8CombustionStatus 3 "Not available" 2 "Error" 1 "Combustion exists" 0 "No combustion" ;
VAL_ 2364544766 EngCyl7CombustionStatus 3 "Not available" 2 "Error" 1 "Combustion exists" 0 "No combustion" ;
VAL_ 2364544766 EngCyl6CombustionStatus 3 "Not available" 2 "Error" 1 "Combustion exists" 0 "No combustion" ;
VAL_ 2364544766 EngCyl5CombustionStatus 3 "Not available" 2 "Error" 1 "Combustion exists" 0 "No combustion" ;
VAL_ 2364544766 EngCyl4CombustionStatus 3 "Not available" 2 "Error" 1 "Combustion exists" 0 "No combustion" ;
VAL_ 2364544766 EngCyl3CombustionStatus 3 "Not available" 2 "Error" 1 "Combustion exists" 0 "No combustion" ;
VAL_ 2364544766 EngCyl2CombustionStatus 3 "Not available" 2 "Error" 1 "Combustion exists" 0 "No combustion" ;
VAL_ 2364544766 EngCyl1CombustionStatus 3 "Not available" 2 "Error" 1 "Combustion exists" 0 "No combustion" ;
VAL_ 2364544510 RqGenOverallPowerFactorLagging 3 "Not available or Not installed" 2 "Reserved" 1 "Lagging" 0 "Leading" ;
VAL_ 2364544254 BladeRotationAngleFigureOfMerit 3 "Blade Rotation Angle not available" 2 "Blade Rotation Angle failed" 1 "Blade Rotation Angle  degraded" 0 "Blade Rotation Angle fully functional" ;
VAL_ 2364544254 RelativeBladeHeightFigureOfMerit 3 "Relative Blade Height not available" 2 "Relative Blade Height failed." 1 "Relative Blade Height degraded" 0 "Relative Blade Height fully functional" ;
VAL_ 2550333182 VehicleType 1 "Dolly axle" 0 "Towing or towed vehicle" ;
VAL_ 2550333182 BrakeLightSwitch 1 "Switch on" 0 "Switch off" ;
VAL_ 2550333182 ASREngineControlActive 3 "NotAvailable" 2 "Reserved" 1 "ASREngineControlActive" 0 "ASREngnCntrlPassiveButInstalled" ;
VAL_ 2550333182 ASRBreakControlActive 1 "Active" 0 "Passive, but installed" ;
VAL_ 2550333182 VehicleRetarderCtrlActive 1 "Active" 0 "Passive" ;
VAL_ 2550333182 VehicleABSActive 1 "Active" 0 "Passiv, but installed" ;
VAL_ 2566834686 PneumaticControlLine 1 "Towing veh with pn ctrl line" 0 "Towing veh without pn ctrl line" ;
VAL_ 2566834686 ABSOffroadRequest 1 "ABS off-road switch on" 0 "ABS off-road switch off" ;
VAL_ 2566834686 TwoElCircuitsBrakeDemand 1 "Two el. circuit brake available" 0 "One el. circuit brake available" ;
VAL_ 2566834686 VehicleRetarderCtrlActive 1 "Active" 0 "Passive" ;
VAL_ 2550398718 SupplyLineBrakingRequest 1 "Supply line braking request" 0 "No supply line braking request" ;
VAL_ 2550398718 VDCActive 1 "Active" 0 "Passive, but installed" ;
VAL_ 2550398718 AutomTowedVehBreakActive 1 "Active" 0 "Passive" ;
VAL_ 2550398718 VehicleServiceBrakeActive 1 "Active" 0 "Passive" ;
VAL_ 2550398718 VehicleRetarderCtrlActive 1 "Active" 0 "Passive" ;
VAL_ 2550398718 VehicleABSActive 1 "Active" 0 "Passiv, but installed" ;
VAL_ 2566833406 SupplyLineBrakingRequest 1 "Supply line braking request" 0 "No supply line braking request" ;
VAL_ 2566833406 LoadingRampApproachAssist 1 "Assistance active" 0 "Assistance not active" ;
VAL_ 2566833406 SpringBrakeEngaged 1 "Vehicle spring brake is engaged" 0 "Vehicle spring brake is released" ;
VAL_ 2566833406 ElectrLoadPropFunc 1 "Vehicle with el. load proportion" 0 "Vehicle without el. load proport" ;
VAL_ 2566833406 SpringBrakeInstalled 1 "Vehicle with spring brakes" 0 "Vehicle without spring brakes" ;
VAL_ 2566833406 VehicleType 1 "Dolly axle" 0 "Towing or towed vehicle" ;
VAL_ 2566833406 ElecSupplyOfNonBrakingSys 1 "Supply switched on" 0 "Supply switched off" ;
VAL_ 2566833406 AmberWarningSignalReq 1 "Towed vehicle failure indicated" 0 "No towed vehicle failure indicat" ;
VAL_ 2566833406 RedWarningSignalRequest 1 "Towed vehicle failure indicated" 0 "No towed vehicle failure indicat" ;
VAL_ 2566833406 VehicleElectrSupplySuff 1 "Vehicle el. supply sufficient" 0 "Vehicle el. supply insufficient" ;
VAL_ 2566833406 AutomTowedVehBreakActive 1 "Active" 0 "Passive" ;
VAL_ 2566833406 VehicleServiceBrakeActive 1 "Active" 0 "Passive" ;
VAL_ 2566833406 VehicleRetarderCtrlActive 1 "Active" 0 "Passive" ;
VAL_ 2566833406 VehicleABSActive 1 "Active" 0 "Passiv, but installed" ;
VAL_ 2566833918 TyreWheelIdentTemp2 15 "Axle position 15" 14 "Axle position 14" 13 "Axle position 13" 12 "Axle position 12" 11 "Axle position 11" 10 "Axle position 10" 9 "Axle position 9" 8 "Axle position 8" 7 "Axle position 7" 6 "Axle position 6" 5 "Axle position 5" 4 "Axle position 4" 3 "Axle position 3" 2 "Axle position 2" 1 "Axle position 1" 0 "Axle position not identified" ;
VAL_ 2566833918 TyreWheelIdentTemp1 15 "Wheel position 15" 14 "Wheel position 14" 13 "Wheel position 13" 12 "Wheel position 12" 11 "Wheel position 11" 10 "Wheel position 10" 9 "Wheel position 9" 8 "Wheel position 8" 7 "Wheel position 7" 6 "Wheel position 6" 5 "Wheel position 5" 4 "Wheel position 4" 3 "Wheel position 3" 2 "Wheel position 2" 1 "Wheel position 1" 0 "Wheel position not identified" ;
VAL_ 2566833918 TyreWheelIdentPressure2 15 "Axle position 15" 14 "Axle position 14" 13 "Axle position 13" 12 "Axle position 12" 11 "Axle position 11" 10 "Axle position 10" 9 "Axle position 9" 8 "Axle position 8" 7 "Axle position 7" 6 "Axle position 6" 5 "Axle position 5" 4 "Axle position 4" 3 "Axle position 3" 2 "Axle position 2" 1 "Axle position 1" 0 "Axle position not identified" ;
VAL_ 2566833918 TyreWheelIdentPressure1 15 "Wheel position 15" 14 "Wheel position 14" 13 "Wheel position 13" 12 "Wheel position 12" 11 "Wheel position 11" 10 "Wheel position 10" 9 "Wheel position 9" 8 "Wheel position 8" 7 "Wheel position 7" 6 "Wheel position 6" 5 "Wheel position 5" 4 "Wheel position 4" 3 "Wheel position 3" 2 "Wheel position 2" 1 "Wheel position 1" 0 "Wheel position not identified" ;
VAL_ 2566833918 TyreWheelIdentLining2 15 "Axle position 15" 14 "Axle position 14" 13 "Axle position 13" 12 "Axle position 12" 11 "Axle position 11" 10 "Axle position 10" 9 "Axle position 9" 8 "Axle position 8" 7 "Axle position 7" 6 "Axle position 6" 5 "Axle position 5" 4 "Axle position 4" 3 "Axle position 3" 2 "Axle position 2" 1 "Axle position 1" 0 "Axle position not identified" ;
VAL_ 2566833918 TyreWheelIdentLining1 15 "Wheel position 15" 14 "Wheel position 14" 13 "Wheel position 13" 12 "Wheel position 12" 11 "Wheel position 11" 10 "Wheel position 10" 9 "Wheel position 9" 8 "Wheel position 8" 7 "Wheel position 7" 6 "Wheel position 6" 5 "Wheel position 5" 4 "Wheel position 4" 3 "Wheel position 3" 2 "Wheel position 2" 1 "Wheel position 1" 0 "Wheel position not identified" ;
VAL_ 2566833918 VehiclePneumSupplySuff 1 "Pneumatic supply sufficient" 0 "Pneumatic supply insufficient" ;
VAL_ 2566833918 BrakeTemperatureStatus 1 "Brake temperature normal" 0 "Brake temperature out of range" ;
VAL_ 2566833918 BrakeLiningSufficient 1 "Brake linings sufficient" 0 "Brake linings insufficient" ;
VAL_ 2566833918 TyrePressureSufficient 1 "Tyre pressure sufficient" 0 "Tyre pressure insufficient" ;
VAL_ 2565013246 ODDRequest 3 "Take no action" 1 "ODD on" 0 "ODD off" ;
VAL_ 2565013246 AntiTheftDeviceReq 3 "Take no action" 1 "Anti-theft device on" 0 "Anti-theft device off" ;
VAL_ 2565013246 VehicleType 1 "Dolly axle" 0 "Towing or towed vehicle" ;
VAL_ 2566807550 EngineTorqueMode 15 "Not available" 11 "Remote accelerator" 10 "Braking system" 9 "High speed governor" 8 "Torque limiting" 7 "ABS control" 6 "Transmission control" 5 "ASR control" 4 "Road speed governor" 3 "PTO governor" 2 "Cruise control" 1 "Accelerator pedal/operator selec" 0 "Low idle governor/no request (de" ;
VAL_ 2566807550 EngineRunning 1 "Engine running" 0 "Engine not running" ;
VAL_ 2566807550 EngineControlAllowed 1 "Engine control allowed" 0 "Engine control not allowed" ;
VAL_ 2566808062 ClutchIndptdPTOFeedback 1 "Engaged" 0 "Not engaged" ;
VAL_ 2566808062 AccelPedalLowIdleSwitch 1 "In low idle condition" 0 "Not in low idle condition" ;
VAL_ 2566808062 StarterActive 1 "Starter active" 0 "Starter not active" ;
VAL_ 2566808062 TorqueConvtOilTempWarning 2 "Warning" 1 "Prewarning" 0 "No warning" ;
VAL_ 2566808062 PTOControlAllowed 1 "PTO control allowed" 0 "PTO control not allowed" ;
VAL_ 2566808062 SecEngineMtdPTOFeedback 1 "Limits activated" 0 "Limits not activated" ;
VAL_ 2566808062 FirstEngineMtdPTOFeedback 1 "Limits activated" 0 "Limits not activated" ;
VAL_ 2566808062 SecClutchDptdPTOFeedback 1 "Engaged" 0 "Not engaged" ;
VAL_ 2566808062 FirstClutchDpdtPTOFeedback 1 "Engaged" 0 "Not engaged" ;
VAL_ 2566808574 FuelLevelWarning 1 "Fuel level warning on" 0 "Fuel level warning off" ;
VAL_ 2566808574 EngineOilPressureWarning 1 "Warning" 0 "No warning" ;
VAL_ 2566808574 EngineCoolantTempWarning 2 "Warning" 1 "Prewarning" 0 "No warning" ;
VAL_ 2564947710 VehicleType 1 "Dolly axle" 0 "Towing or towed vehicle" ;
VAL_ 2566834430 AntiTheftDeviceStatus 1 "Anti-theft device on" 0 "Anti-theft device off" ;
VAL_ 2566834430 ODDStatus 1 "ODD active" 0 "ODD inactive" ;
VAL_ 2566808318 SecEngineMtdPTOSwitch 1 "Switched on" 0 "Switched off" ;
VAL_ 2566808318 SecClutchDpdtPTOSwitch 1 "Switched on" 0 "Switched off" ;
VAL_ 2566808318 FirstClutchDpdtPTOSwitch 1 "Switched on" 0 "Switched off" ;
VAL_ 2566808318 OperatingPanelActive 1 "Operating panel active" 0 "Operating panel not active" ;
VAL_ 2566808318 RefusePackerStepSwitch 1 "Switched on" 0 "Switched off" ;
VAL_ 2566808318 EngineStopSwitch 1 "Switched on" 0 "Switched off" ;
VAL_ 2566808318 EngineStartSwitch 1 "Switched on" 0 "Switched off" ;
VAL_ 2566808318 StarterLockoutSwitch 1 "Switched on" 0 "Switched off" ;
VAL_ 2566808318 FirstEngineMtdPTOSwitch 1 "Switched on" 0 "Switched off" ;
VAL_ 2566808318 ClutchIndpdtPTOSwitch 1 "Switched on" 0 "Switched off" ;
VAL_ 2566808830 TrailerLeftSideMarkerLight 1 "Lamp(s) lit" 0 "Lamp(s) not lit" ;
VAL_ 2566808830 TrailerLeftReversingLight 1 "Lamp(s) lit" 0 "Lamp(s) not lit" ;
VAL_ 2566808830 TrailerLeftRearWidIndLight 1 "Lamp(s) lit" 0 "Lamp(s) not lit" ;
VAL_ 2566808830 TrailerLeftRearRegPltLight 1 "Lamp(s) lit" 0 "Lamp(s) not lit" ;
VAL_ 2566808830 TrailerLeftRearLight 1 "Lamp(s) lit" 0 "Lamp(s) not lit" ;
VAL_ 2566808830 TrailerLeftRearFogLight 1 "Lamp(s) lit" 0 "Lamp(s) not lit" ;
VAL_ 2566808830 TrailerLeftDirIndLight 1 "Lamp(s) lit" 0 "Lamp(s) not lit" ;
VAL_ 2566808830 TrailerLeftCrnMarkerLight 1 "Lamp(s) lit" 0 "Lamp(s) not lit" ;
VAL_ 2566808830 TrailerInteriorLight 1 "Lamp(s) lit" 0 "Lamp(s) not lit" ;
VAL_ 2566808830 TrailerWorkLamp 1 "Lamp(s) lit" 0 "Lamp(s) not lit" ;
VAL_ 2566808830 TrailerRotatingIdentLight 1 "Lamp(s) lit" 0 "Lamp(s) not lit" ;
VAL_ 2566808830 TrailerRightStopLight 1 "Lamp(s) lit" 0 "Lamp(s) not lit" ;
VAL_ 2566808830 TrailerRightSideMrkLight 1 "Lamp(s) lit" 0 "Lamp(s) not lit" ;
VAL_ 2566808830 TrailerRightReversingLight 1 "Lamp(s) lit" 0 "Lamp(s) not lit" ;
VAL_ 2566808830 TrailRightRearWidIndLight 1 "Lamp(s) lit" 0 "Lamp(s) not lit" ;
VAL_ 2566808830 TrailerRightRearRegPltLight 1 "Lamp(s) lit" 0 "Lamp(s) not lit" ;
VAL_ 2566808830 TrailerRightRearLight 1 "Lamp(s) lit" 0 "Lamp(s) not lit" ;
VAL_ 2566808830 TrailerRightRearFogLight 1 "Lamp(s) lit" 0 "Lamp(s) not lit" ;
VAL_ 2566808830 TrailerRightDirIndLight 1 "Lamp(s) lit" 0 "Lamp(s) not lit" ;
VAL_ 2566808830 TrailerRightCrnMarkerLight 1 "Lamp(s) lit" 0 "Lamp(s) not lit" ;
VAL_ 2566808830 TrailerRearWarningLight 1 "Lamp(s) lit" 0 "Lamp(s) not lit" ;
VAL_ 2566808830 TrailerLeftStopLight 1 "Lamp(s) lit" 0 "Lamp(s) not lit" ;
VAL_ 2564554494 FlowStatus 2 "Overflow" 1 "Wait " 0 "Continue To Send" ;
VAL_ 2564554494 ProtocolCtrlInformation 3 "Flow control " 2 "Consecutive frame" 1 "First frame" 0 "Single frame" ;
VAL_ 2564488958 FlowStatus 2 "Overflow" 1 "Wait " 0 "Continue To Send" ;
VAL_ 2564488958 ProtocolCtrlInformation 3 "Flow control " 2 "Consecutive frame" 1 "First frame" 0 "Single frame" ;
VAL_ 2565734142 ToPort 21 "Global (All ports)" 0 "Local" ;
VAL_ 2565734142 NetworkMessageControlByte 133 "SP_Reset Message " 132 "SP_Response Message " 131 "SP_Request Message " 130 "GP_Reset Message " 129 "GP_Response " 128 "GP_Request " 67 "NTX_Response " 66 "NTX_Request " 65 "NT_Response" 64 "NT_Request " 6 "MFDB_CreateEntry" 5 "MFDB_SetMode" 4 "MFDB_Clear" 3 "MFDB_Delete" 2 "MFDB_Add" 1 "MFDB_Response" 0 "MFDB_Request" ;
VAL_ 2565734142 FilterMode 1 "PassSpecificPGNs" 0 "BlockSpecificPGNs" ;
VAL_ 2565734142 NIECUPort 21 "Global (All ports)" 0 "Local" ;
VAL_ 2565734142 FromPort 21 "Global (All ports)" 0 "Local" ;
VAL_ 2565144318 StopLevelChangeReq 3 "Take no action" 1 "Stop request" 0 "No stop request" ;
VAL_ 2565144318 RampLevelStorageReq 3 "Take no action" 1 "Store ramp level 2" 0 "Store ramp level 1" ;
VAL_ 2565144318 LevelControlReq 3 "Take no action" 1 "Enable level control" 0 "Disable level control" ;
VAL_ 2565144318 RampLevelReq 3 "Take no action" 1 "Ramp level 2" 0 "Ramp level 1" ;
VAL_ 2565144318 SteeringAxleLockingReq 3 "Take no action" 1 "Lock steering axle" 0 "Unlock steering axle" ;
VAL_ 2565144318 LiftAxle2PositionReq 3 "Take no action" 1 "Position up / tag axle unladen" 0 "Position down / tag axle laden" ;
VAL_ 2565144318 LiftAxle1PositionReq 3 "Don't care/take no action" 2 "Reserved" 1 "Position up / tag axle unladen" 0 "Position down / tag axle laden" ;
VAL_ 2565144318 TractionHelpReq 3 "Take no action" 1 "Traction help request" 0 "No traction help request" ;
VAL_ 2565144318 LevelChangeReqRearAxle 2 "Take no action" 1 "Vehicle body down (lowering)" 0 "Vehicle body up (lifting)" ;
VAL_ 2565144318 LevelChangeReqFrontAxle 2 "Take no action" 1 "Vehicle body down (lowering)" 0 "Vehicle body up (lifting)" ;
VAL_ 2565144318 RideHeightRequest 2 "Take no action" 1 "Normal level 2" 0 "Normal level 1" ;
VAL_ 2565209854 LevelControl 1 "Level control enabled" 0 "Level control disabled" ;
VAL_ 2565209854 RampLevel 1 "Body at requested ramp level" 0 "Body not at requested ramp level" ;
VAL_ 2565209854 NormalLevel 3 "Not available" 1 "Normal level 2" 0 "Normal level 1" ;
VAL_ 2565209854 StopLevelChangeAcknowledge 1 "Level change stopped" 0 "No stop request" ;
VAL_ 2565209854 LevelChangeRearAxle 1 "Body lifting/lowering active" 0 "Body lifting/lowering not active" ;
VAL_ 2565209854 LevelChangeFrontAxle 1 "Body lifting/lowering active" 0 "Body lifting/lowering not active" ;
VAL_ 2565209854 RampLevelStorage 1 "New ramp level stored" 0 "No new storage request" ;
VAL_ 2565209854 SteeringAxleLocking 1 "Steering axle locked" 0 "Steering axle unlocked" ;
VAL_ 2565209854 LiftAxle2Pos 3 "Not available" 2 "Error" 1 "Lift axle position up / tag axle unladen" 0 "Lift axle position down / tag axle laden" ;
VAL_ 2565209854 LiftAxle1Pos 3 "Not available" 2 "Error" 1 "Lift axle position up / tag axle unladen" 0 "Lift axle position down / tag axle laden" ;
VAL_ 2565209854 RampLevelPosition 3 "Not available" 1 "Ramp level 2" 0 "Ramp level 1" ;
VAL_ 2565209854 TractionHelp 1 "Traction help active" 0 "Traction help inactive" ;
VAL_ 2565209854 LevelCtrlSysRideHeightLevel 1 "Vehicle body at requested level" 0 "Vehicle body not at req. level" ;
SG_MUL_VAL_ 2565734142 ToPort NetworkMessageControlByte 0-6, 131-133;
SG_MUL_VAL_ 2565734142 FilterMode NetworkMessageControlByte 1-1, 6-6;
SG_MUL_VAL_ 2565734142 NIECUPort NetworkMessageControlByte 64-67;
SG_MUL_VAL_ 2565734142 FromPort NetworkMessageControlByte 0-6, 131-133;
